VERSION "dbc-export 1 2026.26.6.5"

NS_ :

BS_:

BU_: ADSP APSB CMP DAS EPAS3P GTW OCS1P PTC RCM TCU TCU2 TRCM UDS UI UIS VCLEFT

BO_ 2047 GTW_carConfig: 8 GTW
 SG_ GTW_carConfigMultiplexer M : 0|8@1+ (1,0) [0|255] "" Vector__XXX
 SG_ GTW_deliveryStatus m1 : 8|1@1+ (1,0) [0|1] "" Vector__XXX
 SG_ GTW_cabinPTCHeaterType m1 : 10|1@1+ (1,0) [0|1] "" Vector__XXX
 SG_ GTW_rightHandDrive m1 : 11|1@1+ (1,0) [0|1] "" Vector__XXX
 SG_ GTW_rearLightType m1 : 12|2@1+ (1,0) [0|3] "" Vector__XXX
 SG_ GTW_headlamps m1 : 14|2@1+ (1,0) [0|3] "" Vector__XXX
 SG_ GTW_country m1 : 16|16@1+ (1,0) [0|65535] "" Vector__XXX
 SG_ GTW_tireType m1 : 32|6@1+ (1,0) [0|63] "" Vector__XXX
 SG_ GTW_dasHw m1 : 40|3@1+ (1,0) [3|5] "" Vector__XXX
 SG_ GTW_brakeHWType m1 : 43|5@1+ (1,0) [0|31] "" Vector__XXX
 SG_ GTW_restraintsHardwareType m1 : 48|8@1+ (1,0) [0|255] "" Vector__XXX
 SG_ GTW_drivetrainType m1 : 56|4@1+ (1,0) [0|4] "" Vector__XXX
 SG_ GTW_radarHeaterType m1 : 60|3@1+ (1,0) [0|5] "" Vector__XXX
 SG_ GTW_exteriorTrimType m2 : 8|1@1+ (1,0) [0|1] "" Vector__XXX
 SG_ GTW_frontSeatHeaters m2 : 9|1@1+ (1,0) [0|1] "" Vector__XXX
 SG_ GTW_rearSeatHeaters m2 : 10|1@1+ (1,0) [0|1] "" Vector__XXX
 SG_ GTW_eCallAntennaHW m2 : 12|1@1+ (1,0) [0|1] "" Vector__XXX
 SG_ GTW_homelinkType m2 : 13|1@1+ (1,0) [0|1] "" Vector__XXX
 SG_ GTW_vdcType m2 : 14|1@1+ (1,0) [0|1] "" Vector__XXX
 SG_ GTW_memoryMirrors m2 : 17|1@1+ (1,0) [0|1] "" Vector__XXX
 SG_ GTW_powerLiftgateType m2 : 18|2@1+ (1,0) [0|2] "" Vector__XXX
 SG_ GTW_lumbarECUType m2 : 20|4@1+ (1,0) [0|15] "" Vector__XXX
 SG_ GTW_rearSeatHeaterType m2 : 24|2@1+ (1,0) [0|3] "" Vector__XXX
 SG_ GTW_auxParkLamps m2 : 26|2@1+ (1,0) [0|3] "" Vector__XXX
 SG_ GTW_interiorCabinRadarType m2 : 28|1@1+ (1,0) [0|1] "" Vector__XXX
 SG_ GTW_hvacPanelVaneType m2 : 29|1@1+ (1,0) [0|1] "" Vector__XXX
 SG_ GTW_intakeAirFilterType m2 : 30|2@1+ (1,0) [0|2] "" Vector__XXX
 SG_ GTW_eBuckConfig m2 : 32|1@1+ (1,0) [0|1] "" Vector__XXX
 SG_ GTW_steeringHeaterEnabled m2 : 33|1@1+ (1,0) [0|1] "" Vector__XXX
 SG_ GTW_activeHighBeam m2 : 34|1@1+ (1,0) [0|1] "" Vector__XXX
 SG_ GTW_airbagCutoffSwitch m2 : 35|1@1+ (1,0) [0|1] "" Vector__XXX
 SG_ GTW_intrusionSensorType m2 : 36|1@1+ (1,0) [0|1] "" Vector__XXX
 SG_ GTW_spoilerType m2 : 37|1@1+ (1,0) [0|1] "" Vector__XXX
 SG_ GTW_backupCameraType m2 : 38|1@1+ (1,0) [0|1] "" Vector__XXX
 SG_ GTW_rearFogLamps m2 : 39|1@1+ (1,0) [0|1] "" Vector__XXX
 SG_ GTW_roofType m2 : 40|1@1+ (1,0) [0|1] "" Vector__XXX
 SG_ GTW_thirdRowSeatType m2 : 41|1@1+ (1,0) [0|1] "" Vector__XXX
 SG_ GTW_autopilot m2 : 42|3@1+ (1,0) [0|7] "" Vector__XXX
 SG_ GTW_superchargingAccess m2 : 45|2@1+ (1,0) [0|3] "" Vector__XXX
 SG_ GTW_exteriorColor m2 : 48|5@1+ (1,0) [0|31] "" Vector__XXX
 SG_ GTW_pedestrianWarningSound m2 : 53|2@1+ (1,0) [0|3] "" Vector__XXX
 SG_ GTW_steeringColumnUJointType m2 : 55|1@1+ (1,0) [0|1] "" Vector__XXX
 SG_ GTW_bPillarNFCParam m2 : 56|1@1+ (1,0) [0|1] "" Vector__XXX
 SG_ GTW_interiorLighting m2 : 57|3@1+ (1,0) [0|7] "" Vector__XXX
 SG_ GTW_headlightLevelerType m2 : 60|2@1+ (1,0) [0|3] "" Vector__XXX
 SG_ GTW_numberHVILNodes m2 : 62|2@1+ (1,0) [0|3] "" Vector__XXX
 SG_ GTW_mapRegion m3 : 8|4@1+ (1,0) [0|15] "" Vector__XXX
 SG_ GTW_performancePackage m3 : 12|3@1+ (1,0) [0|7] "" Vector__XXX
 SG_ GTW_chassisType m3 : 18|4@1+ (1,0) [0|15] "" Vector__XXX
 SG_ GTW_airSuspension m3 : 22|2@1+ (1,0) [0|3] "" Vector__XXX
 SG_ GTW_centerConsoleControllerType m3 : 24|2@1+ (1,0) [0|3] "" Vector__XXX
 SG_ GTW_autopilotCameraType m3 : 26|1@1+ (1,0) [0|1] "" Vector__XXX
 SG_ GTW_connectivityPackage m3 : 27|1@1+ (1,0) [0|1] "" Vector__XXX
 SG_ GTW_plcSupportType m3 : 28|2@1+ (1,0) [0|3] "" Vector__XXX
 SG_ GTW_badgingVersion m3 : 30|2@1+ (1,0) [0|3] "" Vector__XXX
 SG_ GTW_packEnergy m3 : 32|5@1+ (1,0) [0|31] "" Vector__XXX
 SG_ GTW_frontSeatReclinerHardware m3 : 37|2@1+ (1,0) [0|3] "" Vector__XXX
 SG_ GTW_brakeLineSwitchType m3 : 39|1@1+ (1,0) [0|1] "" Vector__XXX
 SG_ GTW_espValveType m3 : 40|2@1+ (1,0) [0|3] "" Vector__XXX
 SG_ GTW_softRange m3 : 42|3@1+ (1,0) [0|7] "" Vector__XXX
 SG_ GTW_refrigerantType m3 : 45|2@1+ (1,0) [0|3] "" Vector__XXX
 SG_ GTW_wheelType m3 : 48|7@1+ (1,0) [0|127] "" Vector__XXX
 SG_ GTW_ptcControlMode m3 : 55|2@1+ (1,0) [0|3] "" Vector__XXX
 SG_ GTW_brakeActuationType m3 : 57|3@1+ (1,0) [0|4] "" Vector__XXX
 SG_ GTW_secondRowSeatType m3 : 60|3@1+ (1,0) [0|7] "" Vector__XXX
 SG_ GTW_secondRowSeatMotorType m3 : 63|1@1+ (1,0) [0|1] "" Vector__XXX
 SG_ GTW_birthday m4 : 8|32@1+ (1,0) [0|4294967295] "" Vector__XXX
 SG_ GTW_eCallEnabled m4 : 40|2@1+ (1,0) [0|3] "" Vector__XXX
 SG_ GTW_parkAssistECUType m4 : 42|2@1+ (1,0) [0|3] "" Vector__XXX
 SG_ GTW_passengerAirbagType m4 : 44|2@1+ (1,0) [0|3] "" Vector__XXX
 SG_ GTW_forwardRadarHw m4 : 46|2@1+ (1,0) [0|2] "" Vector__XXX
 SG_ GTW_frontSeatType m4 : 48|4@1+ (1,0) [0|15] "" Vector__XXX
 SG_ GTW_secondRowDisplayType m4 : 52|1@1+ (1,0) [0|1] "" Vector__XXX
 SG_ GTW_wirelessPhoneChargerType m4 : 53|2@1+ (1,0) [0|3] "" Vector__XXX
 SG_ GTW_ethernetTunerType m4 : 55|2@1+ (1,0) [0|3] "" Vector__XXX
 SG_ GTW_interiorTrimType m4 : 60|4@1+ (1,0) [0|15] "" Vector__XXX
 SG_ GTW_gloveboxUSBType m5 : 8|2@1+ (1,0) [0|3] "" Vector__XXX
 SG_ GTW_coolantPumpType m5 : 10|3@1+ (1,0) [0|7] "" Vector__XXX
 SG_ GTW_epblHwType m5 : 13|4@1+ (1,0) [0|15] "" Vector__XXX
 SG_ GTW_epbrHwType m5 : 17|4@1+ (1,0) [0|15] "" Vector__XXX
 SG_ GTW_blowerMotorType m5 : 21|2@1+ (1,0) [0|3] "" Vector__XXX
 SG_ GTW_rearLeftBLEEndpointParameter m5 : 23|1@1+ (1,0) [0|1] "" Vector__XXX
 SG_ GTW_powerMirrorFoldType m5 : 24|1@1+ (1,0) [0|1] "" Vector__XXX
 SG_ GTW_frontUsbHubType m5 : 27|3@1+ (1,0) [0|5] "" Vector__XXX
 SG_ GTW_superManifoldType m5 : 30|2@1+ (1,0) [0|3] "" Vector__XXX
 SG_ GTW_rcmLocation m5 : 32|1@1+ (1,0) [0|1] "" Vector__XXX
 SG_ GTW_autopilotExteriorCameraType m5 : 33|1@1+ (1,0) [0|1] "" Vector__XXX
 SG_ GTW_interiorCamBeautyCoverType m5 : 35|2@1+ (1,0) [0|3] "" Vector__XXX
 SG_ GTW_sirenType m5 : 37|1@1+ (1,0) [0|1] "" Vector__XXX
 SG_ GTW_hornType m5 : 38|1@1+ (1,0) [0|1] "" Vector__XXX
 SG_ GTW_passengerTrackMotorType m5 : 40|1@1+ (1,0) [0|1] "" Vector__XXX
 SG_ GTW_steeringColumnMotorType m5 : 42|2@1+ (1,0) [0|3] "" Vector__XXX
 SG_ GTW_refrigACLineType m5 : 48|2@1+ (1,0) [0|3] "" Vector__XXX
 SG_ GTW_refrigFilterType m5 : 50|2@1+ (1,0) [0|3] "" Vector__XXX
 SG_ GTW_diBurnInType m5 : 52|1@1+ (1,0) [0|1] "" Vector__XXX
 SG_ GTW_specialBadgingType m5 : 53|2@1+ (1,0) [0|3] "" Vector__XXX
 SG_ GTW_chassisSubType m5 : 55|3@1+ (1,0) [0|7] "" Vector__XXX
 SG_ GTW_towPackage m5 : 58|2@1+ (1,0) [0|3] "" Vector__XXX
 SG_ GTW_refrigLccType m5 : 60|1@1+ (1,0) [0|1] "" Vector__XXX
 SG_ GTW_restraintControlsType m5 : 61|1@1+ (1,0) [0|1] "" Vector__XXX
 SG_ GTW_caliperColorType m5 : 62|2@1+ (1,0) [0|3] "" Vector__XXX
 SG_ GTW_wiperMotorType m6 : 9|1@1+ (1,0) [0|1] "" Vector__XXX
 SG_ GTW_frontOverheadConsoleType m6 : 10|2@1+ (1,0) [0|3] "" Vector__XXX
 SG_ GTW_shifterType m6 : 12|1@1+ (1,0) [0|1] "" Vector__XXX
 SG_ GTW_compressorType m6 : 13|4@1+ (1,0) [0|15] "" Vector__XXX
 SG_ GTW_twelveVBatteryType m6 : 17|3@1+ (1,0) [0|7] "" Vector__XXX
 SG_ GTW_efuseSWConfig m6 : 20|3@1+ (1,0) [0|7] "" Vector__XXX
 SG_ GTW_tollCollectionModuleType m6 : 23|1@1+ (1,0) [0|1] "" Vector__XXX
 SG_ GTW_bleEndpointUpdateMethod m6 : 24|1@1+ (1,0) [0|1] "" Vector__XXX
 SG_ GTW_steeringWheelControllerType m6 : 25|3@1+ (1,0) [0|7] "" Vector__XXX
 SG_ GTW_frontSeatVentilationEnabled m6 : 28|1@1+ (1,0) [0|1] "" Vector__XXX
 SG_ GTW_gloveboxActuatorType m6 : 29|2@1+ (1,0) [0|3] "" Vector__XXX
 SG_ GTW_epasType m6 : 32|4@1+ (1,0) [0|11] "" Vector__XXX
 SG_ GTW_homologationRegionOverride m6 : 36|2@1+ (1,0) [0|3] "" Vector__XXX
 SG_ GTW_windowCommandsPermissionType m6 : 38|2@1+ (1,0) [0|3] "" Vector__XXX
 SG_ GTW_headlightStepperStallDetectM m6 : 42|1@1+ (1,0) [0|1] "" Vector__XXX
 SG_ GTW_rgbInteriorLightingEnabled m6 : 43|2@1+ (1,0) [0|3] "" Vector__XXX
 SG_ GTW_windshieldWiperHeaterType m6 : 45|1@1+ (1,0) [0|1] "" Vector__XXX
 SG_ GTW_thirdRowSeatReclinerType m6 : 46|1@1+ (1,0) [0|1] "" Vector__XXX
 SG_ GTW_driveInterfaceType m6 : 47|1@1+ (1,0) [0|1] "" Vector__XXX
 SG_ GTW_efficiencyPackage m6 : 49|6@1+ (1,0) [0|63] "" Vector__XXX
 SG_ GTW_visorLightType m6 : 55|1@1+ (1,0) [0|1] "" Vector__XXX
 SG_ GTW_gnssAntennaType m6 : 58|2@1+ (1,0) [0|3] "" Vector__XXX
 SG_ GTW_airDistributionBoxType m6 : 60|1@1+ (1,0) [0|1] "" Vector__XXX
 SG_ GTW_frontSeatHeatersEnabled m6 : 62|1@1+ (1,0) [0|1] "" Vector__XXX
 SG_ GTW_windshieldWiperHeaterEnabled m6 : 63|1@1+ (1,0) [0|1] "" Vector__XXX
 SG_ GTW_alcoholInterlockType m7 : 8|1@1+ (1,0) [0|1] "" Vector__XXX
 SG_ GTW_fasciaType m7 : 9|4@1+ (1,0) [0|15] "" Vector__XXX
 SG_ GTW_powerSteeringColumn m7 : 13|1@1+ (1,0) [0|1] "" Vector__XXX
 SG_ GTW_frontSeatHeaterType m7 : 14|1@1+ (1,0) [0|1] "" Vector__XXX
 SG_ GTW_softPerformanceLimit m7 : 15|4@1+ (1,0) [0|15] "" Vector__XXX
 SG_ GTW_gsrFeatureType m7 : 21|2@1+ (1,0) [0|2] "" Vector__XXX
 SG_ GTW_immersiveAudio m7 : 23|2@1+ (1,0) [0|3] "" Vector__XXX
 SG_ GTW_frontSeatVentilationType m7 : 25|1@1+ (1,0) [0|1] "" Vector__XXX
 SG_ GTW_passengerOccupancySensorType m7 : 26|3@1+ (1,0) [0|7] "" Vector__XXX
 SG_ GTW_packPerformanceDeviation m7 : 30|3@1+ (1,0) [0|7] "" Vector__XXX
 SG_ GTW_pressurePadType m7 : 33|2@1+ (1,0) [0|3] "" Vector__XXX
 SG_ GTW_frontFogLamps m7 : 35|1@1+ (1,0) [0|1] "" Vector__XXX
 SG_ GTW_driverOccupancySensorType m7 : 36|1@1+ (1,0) [0|1] "" Vector__XXX
 SG_ GTW_audioType m7 : 37|3@1+ (1,0) [0|7] "" Vector__XXX
 SG_ GTW_thighExtenderType m7 : 41|1@1+ (1,0) [0|1] "" Vector__XXX
 SG_ GTW_occupancyClassificationFeatu m7 : 42|1@1+ (1,0) [0|1] "" Vector__XXX
 SG_ GTW_frontControllerArchitectureT m7 : 46|1@1+ (1,0) [0|1] "" Vector__XXX
 SG_ GTW_domeLightType m7 : 47|2@1+ (1,0) [0|3] "" Vector__XXX
 SG_ GTW_tpmsType m7 : 49|2@1+ (1,0) [0|3] "" Vector__XXX
 SG_ GTW_authenticationEndpointLayout m7 : 52|3@1+ (1,0) [0|6] "" Vector__XXX
 SG_ GTW_socSleepOverride m7 : 57|2@1+ (1,0) [0|3] "" Vector__XXX
 SG_ GTW_r79BehaviorOverride m7 : 59|1@1+ (1,0) [0|1] "" Vector__XXX
 SG_ GTW_steeringHeaterType m7 : 60|3@1+ (1,0) [0|7] "" Vector__XXX
 SG_ GTW_narrowWipingSupported m7 : 63|1@1+ (1,0) [0|1] "" Vector__XXX
 SG_ GTW_frontSeatHeaterGridType m8 : 8|1@1+ (1,0) [0|1] "" Vector__XXX
 SG_ GTW_frontSeatSideSwitchType m8 : 9|1@1+ (1,0) [0|1] "" Vector__XXX
 SG_ GTW_sohRegulatoryStatus m8 : 10|1@1+ (1,0) [0|1] "" Vector__XXX
 SG_ GTW_passengerTiltMotorType m8 : 11|2@1+ (1,0) [0|3] "" Vector__XXX
 SG_ GTW_frunkInteriorReleaseType m8 : 15|1@1+ (1,0) [0|1] "" Vector__XXX
 SG_ GTW_m3yBusArchitecture m8 : 17|2@1+ (1,0) [0|3] "" Vector__XXX
 SG_ GTW_passengerLiftMotorType m8 : 19|2@1+ (1,0) [0|3] "" Vector__XXX
 SG_ GTW_interiorUpperTrimType m8 : 21|1@1+ (1,0) [0|1] "" Vector__XXX
 SG_ GTW_blindSpotIndicatorLightType m8 : 22|2@1+ (1,0) [0|3] "" Vector__XXX
 SG_ GTW_wiperMotorAsicType m8 : 24|2@1+ (1,0) [0|3] "" Vector__XXX
 SG_ GTW_hvacCaseDoorType m8 : 28|1@1+ (1,0) [0|1] "" Vector__XXX
 SG_ GTW_occupancyDetectionSourceRequ m8 : 29|1@1+ (1,0) [0|1] "" Vector__XXX
 SG_ GTW_rduCableType m8 : 31|1@1+ (1,0) [0|1] "" Vector__XXX
 SG_ GTW_parkTelltaleBehaviorType m8 : 32|1@1+ (1,0) [0|1] "" Vector__XXX
 SG_ GTW_numberKeyCardsPairedInFactor m8 : 35|2@1+ (1,0) [0|2] "" Vector__XXX
 SG_ GTW_secondRowSeatVentilationType m8 : 37|1@1+ (1,0) [0|1] "" Vector__XXX
 SG_ GTW_thirdRowSeatHeaterType m8 : 38|1@1+ (1,0) [0|1] "" Vector__XXX
 SG_ GTW_interiorCameraType m8 : 39|2@1+ (1,0) [0|2] "" Vector__XXX
 SG_ GTW_frontFasciaCameraType m8 : 41|2@1+ (1,0) [0|3] "" Vector__XXX
 SG_ GTW_interiorCamFanType m8 : 45|3@1+ (1,0) [0|7] "" Vector__XXX
 SG_ GTW_puddleLampType m8 : 50|2@1+ (1,0) [0|2] "" Vector__XXX
 SG_ GTW_solarLensType m8 : 52|2@1+ (1,0) [0|2] "" Vector__XXX
 SG_ GTW_liftgateGeometryType m8 : 56|2@1+ (1,0) [0|3] "" Vector__XXX
 SG_ GTW_repeaterAeroRibType m8 : 60|3@1+ (1,0) [0|7] "" Vector__XXX
 SG_ GTW_highTipForceWiperArmsType m8 : 63|1@1+ (1,0) [0|1] "" Vector__XXX
 SG_ GTW_rcmUndersideAbuseZThreshold m9 : 8|3@1+ (1,0) [0|7] "" Vector__XXX
 SG_ GTW_rcmUndersideAbuseYThreshold m9 : 11|3@1+ (1,0) [0|7] "" Vector__XXX
 SG_ GTW_rcmUndersideAbuseWindow m9 : 14|2@1+ (1,0) [0|3] "" Vector__XXX
 SG_ GTW_uhfChargePortEnabled m9 : 16|1@1+ (1,0) [0|1] "" Vector__XXX
 SG_ GTW_automaticFeatureResetPackage m9 : 18|1@1+ (1,0) [0|1] "" Vector__XXX
 SG_ GTW_autopilotFeaturePackage m9 : 20|2@1+ (1,0) [0|2] "" Vector__XXX
 SG_ GTW_doorLatchType m9 : 23|1@1+ (1,0) [0|1] "" Vector__XXX
 SG_ GTW_headlinerMaterialType m9 : 25|2@1+ (1,0) [0|3] "" Vector__XXX
 SG_ GTW_glareShieldHeaterType m9 : 27|1@1+ (1,0) [0|1] "" Vector__XXX
 SG_ GTW_rearLightHardwareVariant m9 : 29|2@1+ (1,0) [0|3] "" Vector__XXX
 SG_ GTW_fasciaHarnessCleanPointType m9 : 31|2@1+ (1,0) [0|3] "" Vector__XXX
 SG_ GTW_epasSubType m9 : 33|1@1+ (1,0) [0|1] "" Vector__XXX
 SG_ GTW_wiperSupplyChainOrigin m9 : 35|2@1+ (1,0) [1|3] "" Vector__XXX
 SG_ GTW_windowPinchParameterType m9 : 37|2@1+ (1,0) [0|3] "" Vector__XXX
 SG_ GTW_badgingMaterialType m9 : 39|1@1+ (1,0) [0|1] "" Vector__XXX
 SG_ GTW_mRecordVersion m9 : 40|1@1+ (1,0) [0|1] "" Vector__XXX
 SG_ GTW_tcuType m9 : 47|2@1+ (1,0) [0|2] "" Vector__XXX
 SG_ GTW_carbComplianceBehaviorType m9 : 49|1@1+ (1,0) [0|1] "" Vector__XXX
 SG_ GTW_indirectTPMSCalibrationType m9 : 55|3@1+ (1,0) [0|7] "" Vector__XXX
 SG_ GTW_v2xEnabled m9 : 58|1@1+ (1,0) [0|1] "" Vector__XXX
 SG_ GTW_liftgateStrutType m9 : 60|1@1+ (1,0) [0|1] "" Vector__XXX
 SG_ GTW_exteriorMicrophoneType m9 : 63|1@1+ (1,0) [0|1] "" Vector__XXX
 SG_ GTW_contactorPowerSource m10 : 20|1@1+ (1,0) [0|1] "" Vector__XXX
 SG_ GTW_roofGlassType m10 : 21|3@1+ (1,0) [0|7] "" Vector__XXX
 SG_ GTW_pedalMapNameOverride m10 : 25|1@1+ (1,0) [0|1] "" Vector__XXX

BO_ 792 GTW_carState: 8 GTW
 SG_ GTW_factoryGated : 48|1@1+ (1,0) [0|1] "" Vector__XXX

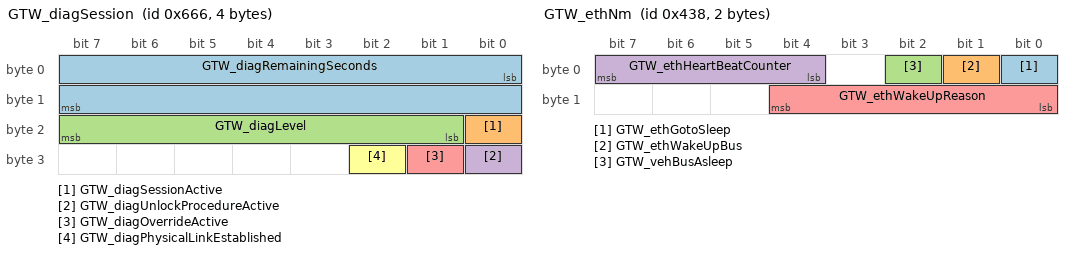
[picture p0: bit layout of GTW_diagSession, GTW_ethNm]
BO_ 1638 GTW_diagSession: 4 GTW
 SG_ GTW_diagRemainingSeconds : 0|16@1+ (1,0) [0|65535] "seconds" Vector__XXX
 SG_ GTW_diagSessionActive : 16|1@1+ (1,0) [0|1] "" Vector__XXX
 SG_ GTW_diagLevel : 17|7@1+ (1,0) [0|127] "" Vector__XXX
 SG_ GTW_diagUnlockProcedureActive : 24|1@1+ (1,0) [0|1] "" Vector__XXX
 SG_ GTW_diagOverrideActive : 25|1@1+ (1,0) [0|1] "" Vector__XXX
 SG_ GTW_diagPhysicalLinkEstablished : 26|1@1+ (1,0) [0|1] "" Vector__XXX

BO_ 1080 GTW_ethNm: 2 GTW
 SG_ GTW_ethGotoSleep : 0|1@1+ (1,0) [0|1] "" Vector__XXX
 SG_ GTW_ethWakeUpBus : 1|1@1+ (1,0) [0|1] "" Vector__XXX
 SG_ GTW_vehBusAsleep : 2|1@1+ (1,0) [0|1] "" Vector__XXX
 SG_ GTW_ethHeartBeatCounter : 4|4@1+ (1,0) [0|15] "" Vector__XXX
 SG_ GTW_ethWakeUpReason : 8|5@1+ (1,0) [0|31] "" Vector__XXX

BO_ 1376 GTW_factoryEcuPresent: 4 GTW
 SG_ GTW_OCS1Ppresent : 0|1@1+ (1,0) [0|1] "" Vector__XXX
 SG_ GTW_PCSpresent : 1|1@1+ (1,0) [0|1] "" Vector__XXX
 SG_ GTW_HVPpresent : 2|1@1+ (1,0) [0|1] "" Vector__XXX
 SG_ GTW_BMSpresent : 3|1@1+ (1,0) [0|1] "" Vector__XXX
 SG_ GTW_CPpresent : 4|1@1+ (1,0) [0|1] "" Vector__XXX
 SG_ GTW_RCMpresent : 5|1@1+ (1,0) [0|1] "" Vector__XXX
 SG_ GTW_SCCMpresent : 6|1@1+ (1,0) [0|1] "" Vector__XXX
 SG_ GTW_VCSECpresent : 7|1@1+ (1,0) [0|1] "" Vector__XXX
 SG_ GTW_EPAS3Ppresent : 8|1@1+ (1,0) [0|1] "" Vector__XXX
 SG_ GTW_EPBLpresent : 9|1@1+ (1,0) [0|1] "" Vector__XXX
 SG_ GTW_EPBRpresent : 10|1@1+ (1,0) [0|1] "" Vector__XXX
 SG_ GTW_ESPpresent : 11|1@1+ (1,0) [0|1] "" Vector__XXX
 SG_ GTW_IBSTpresent : 12|1@1+ (1,0) [0|1] "" Vector__XXX
 SG_ GTW_PARKpresent : 13|1@1+ (1,0) [0|1] "" Vector__XXX
 SG_ GTW_RADCpresent : 14|1@1+ (1,0) [0|1] "" Vector__XXX
 SG_ GTW_TPMSpresent : 15|1@1+ (1,0) [0|1] "" Vector__XXX
 SG_ GTW_VCFRONTpresent : 16|1@1+ (1,0) [0|1] "" Vector__XXX
 SG_ GTW_VCLEFTpresent : 17|1@1+ (1,0) [0|1] "" Vector__XXX
 SG_ GTW_VCRIGHTpresent : 18|1@1+ (1,0) [0|1] "" Vector__XXX
 SG_ GTW_EPAS3Spresent : 19|1@1+ (1,0) [0|1] "" Vector__XXX
 SG_ GTW_CMPpresent : 20|1@1+ (1,0) [0|1] "" Vector__XXX
 SG_ GTW_DASpresent : 21|1@1+ (1,0) [0|1] "" Vector__XXX
 SG_ GTW_PTCpresent : 22|1@1+ (1,0) [0|1] "" Vector__XXX
 SG_ GTW_SWCpresent : 23|1@1+ (1,0) [0|1] "" Vector__XXX
 SG_ GTW_PMRpresent : 25|1@1+ (1,0) [0|1] "" Vector__XXX
 SG_ GTW_PMFpresent : 26|1@1+ (1,0) [0|1] "" Vector__XXX
 SG_ GTW_DIRpresent : 27|1@1+ (1,0) [0|1] "" Vector__XXX
 SG_ GTW_DIFpresent : 28|1@1+ (1,0) [0|1] "" Vector__XXX

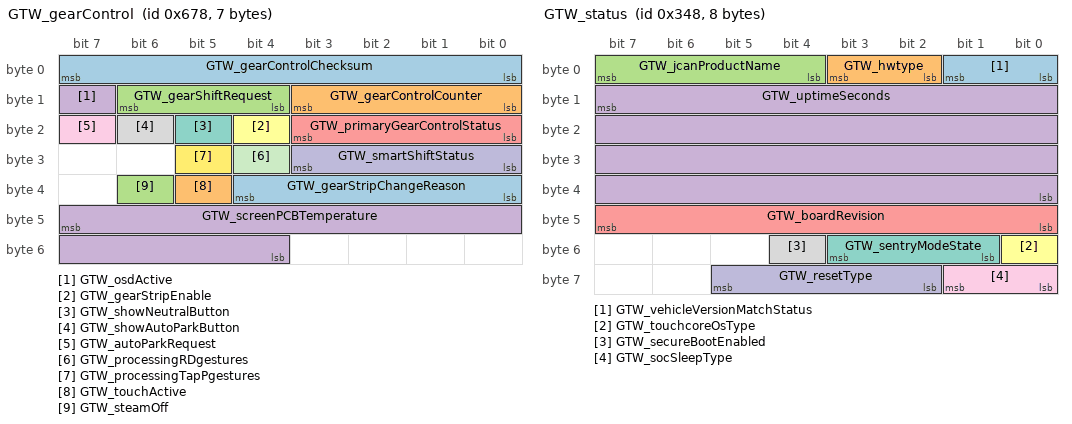
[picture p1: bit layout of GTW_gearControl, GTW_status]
BO_ 1656 GTW_gearControl: 7 GTW
 SG_ GTW_gearControlChecksum : 0|8@1+ (1,0) [0|255] "" Vector__XXX
 SG_ GTW_gearControlCounter : 8|4@1+ (1,0) [0|15] "" Vector__XXX
 SG_ GTW_gearShiftRequest : 12|3@1+ (1,0) [1|7] "" Vector__XXX
 SG_ GTW_osdActive : 15|1@1+ (1,0) [0|1] "" Vector__XXX
 SG_ GTW_primaryGearControlStatus : 16|4@1+ (1,0) [0|15] "" Vector__XXX
 SG_ GTW_gearStripEnable : 20|1@1+ (1,0) [0|1] "" Vector__XXX
 SG_ GTW_showNeutralButton : 21|1@1+ (1,0) [0|1] "" Vector__XXX
 SG_ GTW_showAutoParkButton : 22|1@1+ (1,0) [0|1] "" Vector__XXX
 SG_ GTW_autoParkRequest : 23|1@1+ (1,0) [0|1] "" Vector__XXX
 SG_ GTW_smartShiftStatus : 24|4@1+ (1,0) [1|15] "" Vector__XXX
 SG_ GTW_processingRDgestures : 28|1@1+ (1,0) [0|1] "" Vector__XXX
 SG_ GTW_processingTapPgestures : 29|1@1+ (1,0) [0|1] "" Vector__XXX
 SG_ GTW_gearStripChangeReason : 32|5@1+ (1,0) [1|31] "" Vector__XXX
 SG_ GTW_touchActive : 37|1@1+ (1,0) [0|1] "" Vector__XXX
 SG_ GTW_steamOff : 38|1@1+ (1,0) [0|1] "" Vector__XXX
 SG_ GTW_screenPCBTemperature : 47|12@0- (0.0625,0) [-128|127.875] "degC" Vector__XXX

BO_ 2033 GTW_hrl: 7 GTW
 SG_ GTW_hrlIndex M : 0|2@1+ (1,0) [0|3] "" Vector__XXX
 SG_ GTW_hrlPagesCount m1 : 15|32@0+ (1,0) [0|4294967295] "" Vector__XXX
 SG_ GTW_hrlSdCardSizeGB m1 : 40|8@1+ (1,0) [1|255] "" Vector__XXX
 SG_ GTW_hrlState m2 : 2|1@1+ (1,0) [0|1] "" Vector__XXX
 SG_ GTW_hrlTriggerDuration m2 : 15|16@0+ (1,0) [0|65535] "seconds" Vector__XXX
 SG_ GTW_hrlTriggerType m2 : 24|4@1+ (1,0) [0|15] "" Vector__XXX
 SG_ GTW_hrlTriggerId m2 : 39|16@0+ (1,0) [0|65535] "" Vector__XXX
 SG_ GTW_hrlTriggerBus m2 : 53|3@1+ (1,0) [0|7] "" Vector__XXX

BO_ 2026 GTW_hrlExternalEvent: 8 GTW
 SG_ GTW_hrlEventStartEpoch : 7|32@0+ (1,0) [0|4294967295] "seconds" Vector__XXX
 SG_ GTW_hrlEventEndEpoch : 39|32@0+ (1,0) [0|4294967295] "seconds" Vector__XXX

BO_ 60 GTW_info: 8 GTW
 SG_ GTW_infoIndex M : 0|8@1+ (1,0) [0|255] "" Vector__XXX
 SG_ GTW_buildType m10 : 8|3@1+ (1,0) [0|7] "" Vector__XXX
 SG_ GTW_hardwareId m10 : 32|16@1+ (1,0) [0|65535] "" Vector__XXX
 SG_ GTW_platformType m13 : 8|8@1+ (1,0) [0|255] "" Vector__XXX
 SG_ GTW_appCrc m13 : 32|32@1+ (1,0) [0|4294967295] "" Vector__XXX
 SG_ GTW_applicationGitHash m17 : 8|56@1+ (1,0) [0|7.20575940379e+16] "" Vector__XXX
 SG_ GTW_bootGitHash m18 : 8|56@1+ (1,0) [0|7.20575940379e+16] "" Vector__XXX

BO_ 1370 GTW_mismatchFault: 8 GTW
 SG_ GTW_mismatchFaultIndex M : 0|3@1+ (1,0) [0|7] "" Vector__XXX
 SG_ GTW_mismatchFaultChecksum : 3|8@1+ (1,0) [0|255] "" Vector__XXX
 SG_ GTW_mismatchFaultCounter : 11|4@1+ (1,0) [0|15] "" Vector__XXX
 SG_ GTW_GTWmismatchFault m1 : 15|1@1+ (1,0) [0|1] "" Vector__XXX
 SG_ GTW_BMSmismatchFault m1 : 16|1@1+ (1,0) [0|1] "" Vector__XXX
 SG_ GTW_APSmismatchFault m1 : 17|1@1+ (1,0) [0|1] "" Vector__XXX
 SG_ GTW_BLEEPCENTERmismatchFault m1 : 18|1@1+ (1,0) [0|1] "" Vector__XXX
 SG_ GTW_BLEEPLEFTmismatchFault m1 : 19|1@1+ (1,0) [0|1] "" Vector__XXX
 SG_ GTW_BLEEPREARmismatchFault m1 : 20|1@1+ (1,0) [0|1] "" Vector__XXX
 SG_ GTW_BLEEPRIGHTmismatchFault m1 : 21|1@1+ (1,0) [0|1] "" Vector__XXX
 SG_ GTW_CBCmismatchFault m1 : 22|1@1+ (1,0) [0|1] "" Vector__XXX
 SG_ GTW_CMPmismatchFault m1 : 23|1@1+ (1,0) [0|1] "" Vector__XXX
 SG_ GTW_CPmismatchFault m1 : 24|1@1+ (1,0) [0|1] "" Vector__XXX
 SG_ GTW_DIFmismatchFault m1 : 25|1@1+ (1,0) [0|1] "" Vector__XXX
 SG_ GTW_DIRmismatchFault m1 : 26|1@1+ (1,0) [0|1] "" Vector__XXX
 SG_ GTW_EPAS3PmismatchFault m1 : 27|1@1+ (1,0) [0|1] "" Vector__XXX
 SG_ GTW_EPAS3SmismatchFault m1 : 28|1@1+ (1,0) [0|1] "" Vector__XXX
 SG_ GTW_EPBLmismatchFault m1 : 29|1@1+ (1,0) [0|1] "" Vector__XXX
 SG_ GTW_EPBRmismatchFault m1 : 30|1@1+ (1,0) [0|1] "" Vector__XXX
 SG_ GTW_ESPCALmismatchFault m1 : 31|1@1+ (1,0) [0|1] "" Vector__XXX
 SG_ GTW_ESPmismatchFault m1 : 32|1@1+ (1,0) [0|1] "" Vector__XXX
 SG_ GTW_HCM3LmismatchFault m1 : 33|1@1+ (1,0) [0|1] "" Vector__XXX
 SG_ GTW_HCM3RmismatchFault m1 : 34|1@1+ (1,0) [0|1] "" Vector__XXX
 SG_ GTW_HCMLmismatchFault m1 : 35|1@1+ (1,0) [0|1] "" Vector__XXX
 SG_ GTW_HCMRmismatchFault m1 : 36|1@1+ (1,0) [0|1] "" Vector__XXX
 SG_ GTW_HVPmismatchFault m1 : 37|1@1+ (1,0) [0|1] "" Vector__XXX
 SG_ GTW_IBSTCALmismatchFault m1 : 38|1@1+ (1,0) [0|1] "" Vector__XXX
 SG_ GTW_IBSTmismatchFault m1 : 39|1@1+ (1,0) [0|1] "" Vector__XXX
 SG_ GTW_LVBMSmismatchFault m1 : 40|1@1+ (1,0) [0|1] "" Vector__XXX
 SG_ GTW_OCS1PmismatchFault m1 : 41|1@1+ (1,0) [0|1] "" Vector__XXX
 SG_ GTW_OPCFmismatchFault m1 : 42|1@1+ (1,0) [0|1] "" Vector__XXX
 SG_ GTW_OPCRmismatchFault m1 : 43|1@1+ (1,0) [0|1] "" Vector__XXX
 SG_ GTW_PARKmismatchFault m1 : 44|1@1+ (1,0) [0|1] "" Vector__XXX
 SG_ GTW_PCSCPU2mismatchFault m1 : 45|1@1+ (1,0) [0|1] "" Vector__XXX
 SG_ GTW_PCSmismatchFault m1 : 46|1@1+ (1,0) [0|1] "" Vector__XXX
 SG_ GTW_PMFmismatchFault m1 : 47|1@1+ (1,0) [0|1] "" Vector__XXX
 SG_ GTW_PMRmismatchFault m1 : 48|1@1+ (1,0) [0|1] "" Vector__XXX
 SG_ GTW_PTCmismatchFault m1 : 49|1@1+ (1,0) [0|1] "" Vector__XXX
 SG_ GTW_RCMCALmismatchFault m1 : 50|1@1+ (1,0) [0|1] "" Vector__XXX
 SG_ GTW_RCMmismatchFault m1 : 51|1@1+ (1,0) [0|1] "" Vector__XXX
 SG_ GTW_SCCMmismatchFault m1 : 52|1@1+ (1,0) [0|1] "" Vector__XXX
 SG_ GTW_SDCRmismatchFault m1 : 53|1@1+ (1,0) [0|1] "" Vector__XXX
 SG_ GTW_SWCmismatchFault m1 : 54|1@1+ (1,0) [0|1] "" Vector__XXX
 SG_ GTW_THSmismatchFault m1 : 55|1@1+ (1,0) [0|1] "" Vector__XXX
 SG_ GTW_VCFRONTmismatchFault m1 : 56|1@1+ (1,0) [0|1] "" Vector__XXX
 SG_ GTW_VCLEFTmismatchFault m1 : 57|1@1+ (1,0) [0|1] "" Vector__XXX
 SG_ GTW_VCRIGHTmismatchFault m1 : 58|1@1+ (1,0) [0|1] "" Vector__XXX
 SG_ GTW_VCSECmismatchFault m1 : 59|1@1+ (1,0) [0|1] "" Vector__XXX
 SG_ GTW_PMmismatchFault m1 : 60|1@1+ (1,0) [0|1] "" Vector__XXX

BO_ 840 GTW_status: 8 GTW
 SG_ GTW_vehicleVersionMatchStatus : 0|2@1+ (1,0) [0|3] "" Vector__XXX
 SG_ GTW_hwtype : 2|2@1+ (1,0) [1|3] "" Vector__XXX
 SG_ GTW_jcanProductName : 4|4@1+ (1,0) [1|15] "" Vector__XXX
 SG_ GTW_uptimeSeconds : 15|32@0+ (1,0) [0|4294967295] "s" Vector__XXX
 SG_ GTW_boardRevision : 40|8@1+ (1,0) [0|255] "" Vector__XXX
 SG_ GTW_touchcoreOsType : 48|1@1+ (1,0) [0|1] "" Vector__XXX
 SG_ GTW_sentryModeState : 49|3@1+ (1,0) [0|7] "" Vector__XXX
 SG_ GTW_secureBootEnabled : 52|1@1+ (1,0) [0|1] "" Vector__XXX
 SG_ GTW_socSleepType : 56|2@1+ (1,0) [1|3] "" Vector__XXX
 SG_ GTW_resetType : 58|4@1+ (1,0) [1|15] "" Vector__XXX

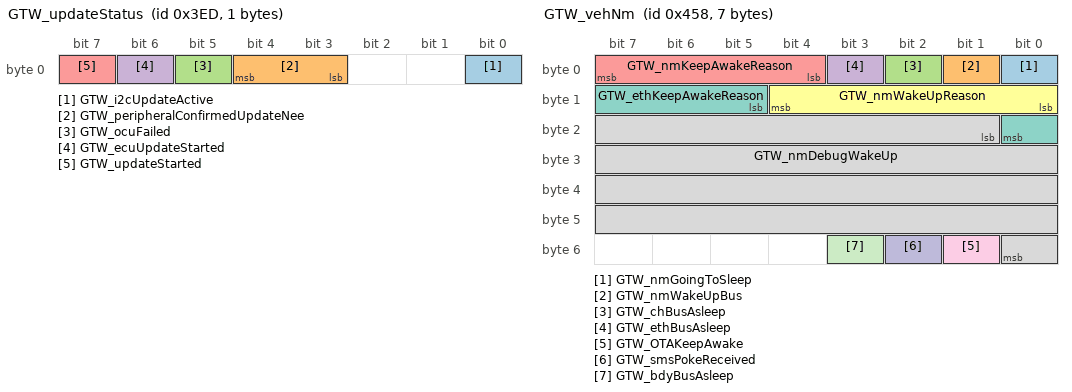
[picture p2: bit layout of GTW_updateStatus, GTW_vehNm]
BO_ 1005 GTW_updateStatus: 1 GTW
 SG_ GTW_i2cUpdateActive : 0|1@1+ (1,0) [0|1] "" Vector__XXX
 SG_ GTW_peripheralConfirmedUpdateNee : 3|2@1+ (1,0) [0|3] "" Vector__XXX
 SG_ GTW_ocuFailed : 5|1@1+ (1,0) [0|1] "" Vector__XXX
 SG_ GTW_ecuUpdateStarted : 6|1@1+ (1,0) [0|1] "" Vector__XXX
 SG_ GTW_updateStarted : 7|1@1+ (1,0) [0|1] "" Vector__XXX

BO_ 1112 GTW_vehNm: 7 GTW
 SG_ GTW_nmGoingToSleep : 0|1@1+ (1,0) [0|1] "" Vector__XXX
 SG_ GTW_nmWakeUpBus : 1|1@1+ (1,0) [0|1] "" Vector__XXX
 SG_ GTW_chBusAsleep : 2|1@1+ (1,0) [0|1] "" Vector__XXX
 SG_ GTW_ethBusAsleep : 3|1@1+ (1,0) [0|1] "" Vector__XXX
 SG_ GTW_nmKeepAwakeReason : 4|4@1+ (1,0) [1|15] "" Vector__XXX
 SG_ GTW_nmWakeUpReason : 8|5@1+ (1,0) [0|31] "" Vector__XXX
 SG_ GTW_ethKeepAwakeReason : 13|4@1+ (1,0) [1|15] "" Vector__XXX
 SG_ GTW_nmDebugWakeUp : 17|32@1+ (1,0) [0|4294967295] "" Vector__XXX
 SG_ GTW_OTAKeepAwake : 49|1@1+ (1,0) [0|1] "" Vector__XXX
 SG_ GTW_smsPokeReceived : 50|1@1+ (1,0) [0|1] "" Vector__XXX
 SG_ GTW_bdyBusAsleep : 51|1@1+ (1,0) [0|1] "" Vector__XXX

BO_ 1429 OCS1P_alertLog: 8 OCS1P
 SG_ OCS1P_alertID M : 0|8@1+ (1,0) [0|255] "" Vector__XXX
 SG_ OCS1P_alertState : 15|1@1+ (1,0) [0|1] "" Vector__XXX
 SG_ OCS1P_a121_sandwichFreq m121 : 16|32@1+ (1,0) [0|4294967295] "" Vector__XXX
 SG_ OCS1P_a122_sandwichFreq m122 : 16|32@1+ (1,0) [0|4294967295] "" Vector__XXX
 SG_ OCS1P_a123_sandwichFreq m123 : 16|32@1+ (1,0) [0|4294967295] "" Vector__XXX
 SG_ OCS1P_a124_cushionSelfFreq m124 : 16|32@1+ (1,0) [0|4294967295] "" Vector__XXX
 SG_ OCS1P_a125_cushionSelfFreq m125 : 16|32@1+ (1,0) [0|4294967295] "" Vector__XXX
 SG_ OCS1P_a126_cushionSelfFreq m126 : 16|32@1+ (1,0) [0|4294967295] "" Vector__XXX
 SG_ OCS1P_a127_seatbackSelfFreq m127 : 16|32@1+ (1,0) [0|4294967295] "" Vector__XXX
 SG_ OCS1P_a128_seatbackSelfFreq m128 : 16|32@1+ (1,0) [0|4294967295] "" Vector__XXX
 SG_ OCS1P_a129_seatbackSelfFreq m129 : 16|32@1+ (1,0) [0|4294967295] "" Vector__XXX
 SG_ OCS1P_a130_sandwichNoCalib m130 : 16|1@1+ (1,0) [0|1] "" Vector__XXX
 SG_ OCS1P_a131_cushionSelfNoCalib m131 : 16|1@1+ (1,0) [0|1] "" Vector__XXX
 SG_ OCS1P_a132_seatbackSelfNoCalib m132 : 16|1@1+ (1,0) [0|1] "" Vector__XXX
 SG_ OCS1P_a133_sandwichBadCalib m133 : 16|1@1+ (1,0) [0|1] "" Vector__XXX
 SG_ OCS1P_a134_uninitializedCalib m134 : 16|1@1+ (1,0) [0|1] "" Vector__XXX
 SG_ OCS1P_a135_tempNoCalib m135 : 16|1@1+ (1,0) [0|1] "" Vector__XXX
 SG_ OCS1P_a140_tempInvalidCalib m140 : 16|1@1+ (1,0) [0|1] "" Vector__XXX
 SG_ OCS1P_a141_humidityInvalidCalib m141 : 16|1@1+ (1,0) [0|1] "" Vector__XXX
 SG_ OCS1P_a142_tempHumidityInvalid m142 : 16|1@1+ (1,0) [0|1] "" Vector__XXX
 SG_ OCS1P_a143_mismatchPassAirbag m143 : 16|1@1+ (1,0) [0|1] "" Vector__XXX
 SG_ OCS1P_a144_mismatchCarRegion m144 : 16|1@1+ (1,0) [0|1] "" Vector__XXX

BO_ 767 OCS1P_alertMatrix: 8 OCS1P
 SG_ OCS1P_matrixIndex M : 0|4@1+ (1,0) [0|15] "" Vector__XXX
 SG_ OCS1P_w015_NVMMAlert m0 : 18|1@1+ (1,0) [0|1] "" Vector__XXX
 SG_ OCS1P_w121_sandwichOpen m2 : 4|1@1+ (1,0) [0|1] "" Vector__XXX
 SG_ OCS1P_w122_sandwichLow m2 : 5|1@1+ (1,0) [0|1] "" Vector__XXX
 SG_ OCS1P_w123_sandwichShort m2 : 6|1@1+ (1,0) [0|1] "" Vector__XXX
 SG_ OCS1P_w124_cushionSelfOpen m2 : 7|1@1+ (1,0) [0|1] "" Vector__XXX
 SG_ OCS1P_w125_cushionSelfLow m2 : 8|1@1+ (1,0) [0|1] "" Vector__XXX
 SG_ OCS1P_w126_cushionSelfShort m2 : 9|1@1+ (1,0) [0|1] "" Vector__XXX
 SG_ OCS1P_w127_seatbackSelfOpen m2 : 10|1@1+ (1,0) [0|1] "" Vector__XXX
 SG_ OCS1P_w128_seatbackSelfLow m2 : 11|1@1+ (1,0) [0|1] "" Vector__XXX
 SG_ OCS1P_w129_seatbackSelfShort m2 : 12|1@1+ (1,0) [0|1] "" Vector__XXX
 SG_ OCS1P_w130_sandwichNoCalib m2 : 13|1@1+ (1,0) [0|1] "" Vector__XXX
 SG_ OCS1P_w131_cushionSelfNoCalib m2 : 14|1@1+ (1,0) [0|1] "" Vector__XXX
 SG_ OCS1P_w132_seatbackSelfNoCalib m2 : 15|1@1+ (1,0) [0|1] "" Vector__XXX
 SG_ OCS1P_w133_sandwichBadCalib m2 : 16|1@1+ (1,0) [0|1] "" Vector__XXX
 SG_ OCS1P_w134_uninitializedCalib m2 : 17|1@1+ (1,0) [0|1] "" Vector__XXX
 SG_ OCS1P_w135_tempNoCalib m2 : 18|1@1+ (1,0) [0|1] "" Vector__XXX
 SG_ OCS1P_w136_cushionSelfDutyLow m2 : 19|1@1+ (1,0) [0|1] "" Vector__XXX
 SG_ OCS1P_w137_cushionSelfDutyHigh m2 : 20|1@1+ (1,0) [0|1] "" Vector__XXX
 SG_ OCS1P_w138_seatbackSelfDutyLow m2 : 21|1@1+ (1,0) [0|1] "" Vector__XXX
 SG_ OCS1P_w139_seatbackSelfDutyHigh m2 : 22|1@1+ (1,0) [0|1] "" Vector__XXX
 SG_ OCS1P_w140_tempInvalidCalib m2 : 23|1@1+ (1,0) [0|1] "" Vector__XXX
 SG_ OCS1P_w141_humidityInvalidCalib m2 : 24|1@1+ (1,0) [0|1] "" Vector__XXX
 SG_ OCS1P_w142_tempHumidityInvalid m2 : 25|1@1+ (1,0) [0|1] "" Vector__XXX
 SG_ OCS1P_w143_mismatchPassAirbag m2 : 26|1@1+ (1,0) [0|1] "" Vector__XXX
 SG_ OCS1P_w144_mismatchCarRegion m2 : 27|1@1+ (1,0) [0|1] "" Vector__XXX
 SG_ OCS1P_w145_rebaselineTriggered m2 : 28|1@1+ (1,0) [0|1] "" Vector__XXX
 SG_ OCS1P_w148_classificationMismatc m2 : 31|1@1+ (1,0) [0|1] "" Vector__XXX
 SG_ OCS1P_w150_rbEntryTriggered m2 : 33|1@1+ (1,0) [0|1] "" Vector__XXX
 SG_ OCS1P_w151_rbEntryExited m2 : 34|1@1+ (1,0) [0|1] "" Vector__XXX
 SG_ OCS1P_w152_rbExit1Triggered m2 : 35|1@1+ (1,0) [0|1] "" Vector__XXX
 SG_ OCS1P_w153_rbExit1Exited m2 : 36|1@1+ (1,0) [0|1] "" Vector__XXX
 SG_ OCS1P_w154_rbExit2Exited1 m2 : 37|1@1+ (1,0) [0|1] "" Vector__XXX
 SG_ OCS1P_w155_rbExit2Exited2 m2 : 38|1@1+ (1,0) [0|1] "" Vector__XXX
 SG_ OCS1P_w156_seatbeltReminderUnava m2 : 39|1@1+ (1,0) [0|1] "" Vector__XXX

BO_ 766 OCS1P_info: 8 OCS1P
 SG_ OCS1P_infoIndex M : 0|8@1+ (1,0) [0|255] "" Vector__XXX
 SG_ OCS1P_infoBuildType m10 : 8|8@1+ (1,0) [0|255] "" Vector__XXX
 SG_ OCS1P_infoBuildConfigID m10 : 16|16@1+ (1,0) [0|65535] "" Vector__XXX
 SG_ OCS1P_infoHardwareID m10 : 32|16@1+ (1,0) [0|65535] "" Vector__XXX
 SG_ OCS1P_infoComponentID m10 : 48|16@1+ (1,0) [0|65535] "" Vector__XXX
 SG_ OCS1P_infoPcbaID m11 : 16|8@1+ (1,0) [0|255] "" Vector__XXX
 SG_ OCS1P_infoAssemblyID m11 : 24|8@1+ (1,0) [0|255] "" Vector__XXX
 SG_ OCS1P_infoUsageID m11 : 32|16@1+ (1,0) [0|65535] "" Vector__XXX
 SG_ OCS1P_infoSubUsageID m11 : 48|16@1+ (1,0) [0|65535] "" Vector__XXX
 SG_ OCS1P_infoApplicationCRC m13 : 32|32@1+ (1,0) [0|4294967295] "" Vector__XXX
 SG_ OCS1P_infoBootSvnRev m14 : 8|24@1+ (1,0) [0|16777215] "" Vector__XXX
 SG_ OCS1P_infoAppGitHashBytes m17 : 8|56@1+ (1,0) [0|7.20575940379e+16] "" Vector__XXX
 SG_ OCS1P_infoBootGitHashBytes m18 : 8|56@1+ (1,0) [0|7.20575940379e+16] "" Vector__XXX
 SG_ OCS1P_infoPlatformType m19 : 8|8@1+ (1,0) [0|255] "" Vector__XXX
 SG_ OCS1P_infoBootUdsProtoVersion m20 : 8|8@1+ (1,0) [0|255] "" Vector__XXX
 SG_ OCS1P_infoBootloaderCRC m20 : 32|32@1+ (1,0) [0|4294967295] "" Vector__XXX

BO_ 771 OCS1P_status: 8 OCS1P
 SG_ OCS1P_occupantClassification : 0|8@1+ (1,0) [0|254] "" Vector__XXX
 SG_ OCS1P_occupantClassificationQF : 8|1@1+ (1,0) [0|1] "" Vector__XXX
 SG_ OCS1P_occupiedState : 9|2@1+ (1,0) [0|2] "" Vector__XXX
 SG_ OCS1P_triggerSnapshot : 11|5@1+ (1,0) [0|31] "" Vector__XXX
 SG_ OCS1P_occupantClassificationRaw : 16|3@1+ (1,0) [0|6] "" Vector__XXX
 SG_ OCS1P_occupantClassificationSelf : 19|3@1+ (1,0) [0|6] "" Vector__XXX
 SG_ OCS1P_occupantClassificationRawC : 22|3@1+ (1,0) [0|6] "" Vector__XXX
 SG_ OCS1P_occupantClassificationCap : 25|3@1+ (1,0) [0|6] "" Vector__XXX
 SG_ OCS1P_classificationHeld : 30|1@1+ (1,0) [0|1] "" Vector__XXX
 SG_ OCS1P_cushionStable : 31|1@1+ (1,0) [0|1] "" Vector__XXX
 SG_ OCS1P_classificationExtHold : 32|1@1+ (1,0) [0|1] "" Vector__XXX
 SG_ OCS1P_classificationHoldState : 33|3@1+ (1,0) [0|7] "" Vector__XXX
 SG_ OCS1P_classificationVariant : 36|3@1+ (1,0) [0|7] "" Vector__XXX
 SG_ OCS1P_sandwichDisabled : 39|1@1+ (1,0) [0|1] "" Vector__XXX
 SG_ OCS1P_noSandwichType : 40|2@1+ (1,0) [0|3] "" Vector__XXX
 SG_ OCS1P_sandwichBoundaryType : 42|1@1+ (1,0) [0|1] "" Vector__XXX
 SG_ OCS1P_sbrBoundaryType : 43|1@1+ (1,0) [0|1] "" Vector__XXX
 SG_ OCS1P_occupiedStateCap : 45|2@1+ (1,0) [0|2] "" Vector__XXX
 SG_ OCS1P_seatbackStable : 47|1@1+ (1,0) [0|1] "" Vector__XXX
 SG_ OCS1P_sandwichStable : 48|1@1+ (1,0) [0|1] "" Vector__XXX
 SG_ OCS1P_cushionStableCap : 49|1@1+ (1,0) [0|1] "" Vector__XXX
 SG_ OCS1P_seatbackStableCap : 50|1@1+ (1,0) [0|1] "" Vector__XXX
 SG_ OCS1P_classificationHeldCap : 51|1@1+ (1,0) [0|1] "" Vector__XXX
 SG_ OCS1P_statusCounter : 52|4@1+ (1,0) [0|15] "" Vector__XXX
 SG_ OCS1P_statusChecksum : 56|8@1+ (1,0) [0|255] "" Vector__XXX

BO_ 1619 OCS1P_udsResponse: 8 OCS1P
 SG_ OCS1P_udsResponseData : 0|64@1+ (1,0) [0|1.84467440737e+19] "" Vector__XXX

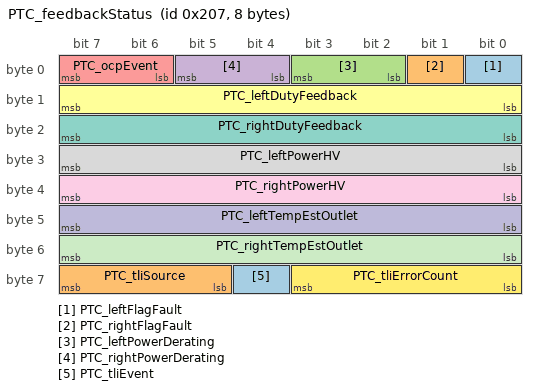
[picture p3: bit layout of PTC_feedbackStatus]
BO_ 519 PTC_feedbackStatus: 8 PTC
 SG_ PTC_leftFlagFault : 0|1@1+ (1,0) [0|1] "" Vector__XXX
 SG_ PTC_rightFlagFault : 1|1@1+ (1,0) [0|1] "" Vector__XXX
 SG_ PTC_leftPowerDerating : 2|2@1+ (1,0) [0|3] "" Vector__XXX
 SG_ PTC_rightPowerDerating : 4|2@1+ (1,0) [0|3] "" Vector__XXX
 SG_ PTC_ocpEvent : 6|2@1+ (1,0) [0|3] "" Vector__XXX
 SG_ PTC_leftDutyFeedback : 8|8@1+ (0.5,0) [0|100] "%" Vector__XXX
 SG_ PTC_rightDutyFeedback : 16|8@1+ (0.5,0) [0|100] "%" Vector__XXX
 SG_ PTC_leftPowerHV : 24|8@1+ (30,0) [0|7650] "W" Vector__XXX
 SG_ PTC_rightPowerHV : 32|8@1+ (30,0) [0|7650] "W" Vector__XXX
 SG_ PTC_leftTempEstOutlet : 40|8@1+ (1,-40) [-40|200] "degC" Vector__XXX
 SG_ PTC_rightTempEstOutlet : 48|8@1+ (1,-40) [-40|200] "degC" Vector__XXX
 SG_ PTC_tliErrorCount : 56|4@1+ (1,0) [0|15] "" Vector__XXX
 SG_ PTC_tliEvent : 60|1@1+ (1,0) [0|1] "" Vector__XXX
 SG_ PTC_tliSource : 61|3@1+ (1,0) [0|7] "" Vector__XXX

BO_ 1297 RCM_alertLog: 8 RCM
 SG_ RCM_alertID M : 0|10@1+ (1,0) [0|1023] "" Vector__XXX
 SG_ RCM_alertState : 10|1@1+ (1,0) [0|1] "" Vector__XXX
 SG_ RCM_a000_eventArmStatus m0 : 11|1@1+ (1,0) [0|1] "" Vector__XXX
 SG_ RCM_a000_eventFactoryMode m0 : 12|1@1+ (1,0) [0|1] "" Vector__XXX
 SG_ RCM_a000_eventDiagEnabled m0 : 13|1@1+ (1,0) [0|1] "" Vector__XXX
 SG_ RCM_a000_eventDriveOrientation m0 : 14|1@1+ (1,0) [0|1] "" Vector__XXX
 SG_ RCM_a000_crashDetectedFront m0 : 16|1@1+ (1,0) [0|1] "" Vector__XXX
 SG_ RCM_a000_crashDetectedRear m0 : 17|1@1+ (1,0) [0|1] "" Vector__XXX
 SG_ RCM_a000_crashDetectedLeft m0 : 18|1@1+ (1,0) [0|1] "" Vector__XXX
 SG_ RCM_a000_crashDetectedRight m0 : 19|1@1+ (1,0) [0|1] "" Vector__XXX
 SG_ RCM_a000_crashDetectedRoll m0 : 20|1@1+ (1,0) [0|1] "" Vector__XXX
 SG_ RCM_a000_crashDetectedPreten m0 : 21|1@1+ (1,0) [0|1] "" Vector__XXX
 SG_ RCM_a000_crashDetectedStage1 m0 : 22|1@1+ (1,0) [0|1] "" Vector__XXX
 SG_ RCM_a000_crashDetectedStage2 m0 : 23|1@1+ (1,0) [0|1] "" Vector__XXX
 SG_ RCM_a000_crashDetectedHVpyro m0 : 24|1@1+ (1,0) [0|1] "" Vector__XXX
 SG_ RCM_a000_eventIDFsignal m0 : 25|1@1+ (1,0) [0|1] "" Vector__XXX
 SG_ RCM_a000_eventFrontLeftSeatbelt m0 : 26|1@1+ (1,0) [0|1] "" Vector__XXX
 SG_ RCM_a000_eventFrontRightSeatbelt m0 : 27|1@1+ (1,0) [0|1] "" Vector__XXX
 SG_ RCM_a000_eventVehicleSpeed m0 : 28|12@1+ (0.08,-40) [-40|287.6] "kph" Vector__XXX
 SG_ RCM_a000_eventSteeringAngle m0 : 45|14@0+ (0.1,-819.2) [-819.2|819.1] "deg" Vector__XXX
 SG_ RCM_a000_eventDriverBrakeApply m0 : 46|2@1+ (1,0) [0|3] "" Vector__XXX
 SG_ RCM_a000_eventAccelPedalPos m0 : 56|8@1+ (0.4,0) [0|102] "%" Vector__XXX
 SG_ RCM_a001_eventArmStatus m1 : 11|1@1+ (1,0) [0|1] "" Vector__XXX
 SG_ RCM_a001_eventFactoryMode m1 : 12|1@1+ (1,0) [0|1] "" Vector__XXX
 SG_ RCM_a001_eventDiagEnabled m1 : 13|1@1+ (1,0) [0|1] "" Vector__XXX
 SG_ RCM_a001_eventDriveOrientation m1 : 14|1@1+ (1,0) [0|1] "" Vector__XXX
 SG_ RCM_a001_nearDeployFront m1 : 16|1@1+ (1,0) [0|1] "" Vector__XXX
 SG_ RCM_a001_nearDeployRear m1 : 17|1@1+ (1,0) [0|1] "" Vector__XXX
 SG_ RCM_a001_nearDeployLeft m1 : 18|1@1+ (1,0) [0|1] "" Vector__XXX
 SG_ RCM_a001_nearDeployRight m1 : 19|1@1+ (1,0) [0|1] "" Vector__XXX
 SG_ RCM_a001_nearDeployRoll m1 : 20|1@1+ (1,0) [0|1] "" Vector__XXX
 SG_ RCM_a001_nearDeployPretensioner m1 : 21|1@1+ (1,0) [0|1] "" Vector__XXX
 SG_ RCM_a001_eventIDFsignal m1 : 25|1@1+ (1,0) [0|1] "" Vector__XXX
 SG_ RCM_a001_eventFrontLeftSeatbelt m1 : 26|1@1+ (1,0) [0|1] "" Vector__XXX
 SG_ RCM_a001_eventFrontRightSeatbelt m1 : 27|1@1+ (1,0) [0|1] "" Vector__XXX
 SG_ RCM_a001_eventVehicleSpeed m1 : 28|12@1+ (0.08,-40) [-40|287.6] "kph" Vector__XXX
 SG_ RCM_a001_eventSteeringAngle m1 : 45|14@0+ (0.1,-819.2) [-819.2|819.1] "deg" Vector__XXX
 SG_ RCM_a001_eventDriverBrakeApply m1 : 46|2@1+ (1,0) [0|2] "" Vector__XXX
 SG_ RCM_a001_eventAccelPedalPos m1 : 56|8@1+ (0.4,0) [0|101.6] "%" Vector__XXX
 SG_ RCM_a002_eventArmStatus m2 : 11|1@1+ (1,0) [0|1] "" Vector__XXX
 SG_ RCM_a002_eventFactoryMode m2 : 12|1@1+ (1,0) [0|1] "" Vector__XXX
 SG_ RCM_a002_eventDiagEnabled m2 : 13|1@1+ (1,0) [0|1] "" Vector__XXX
 SG_ RCM_a002_eventDriveOrientation m2 : 14|1@1+ (1,0) [0|1] "" Vector__XXX
 SG_ RCM_a002_airbagsUnArmed m2 : 16|1@1+ (1,0) [0|1] "" Vector__XXX
 SG_ RCM_a002_eventIDFsignal m2 : 25|1@1+ (1,0) [0|1] "" Vector__XXX
 SG_ RCM_a002_eventFrontLeftSeatbelt m2 : 26|1@1+ (1,0) [0|1] "" Vector__XXX
 SG_ RCM_a002_eventFrontRightSeatbelt m2 : 27|1@1+ (1,0) [0|1] "" Vector__XXX
 SG_ RCM_a002_eventVehicleSpeed m2 : 28|12@1+ (0.08,-40) [-40|287.6] "kph" Vector__XXX
 SG_ RCM_a002_eventSteeringAngle m2 : 45|14@0+ (0.1,-819.2) [-819.2|819.1] "deg" Vector__XXX
 SG_ RCM_a002_eventDriverBrakeApply m2 : 46|2@1+ (1,0) [0|2] "" Vector__XXX
 SG_ RCM_a002_eventAccelPedalPos m2 : 56|8@1+ (0.4,0) [0|101.6] "%" Vector__XXX
 SG_ RCM_a003_eventArmStatus m3 : 11|1@1+ (1,0) [0|1] "" Vector__XXX
 SG_ RCM_a003_eventFactoryMode m3 : 12|1@1+ (1,0) [0|1] "" Vector__XXX
 SG_ RCM_a003_eventDiagEnabled m3 : 13|1@1+ (1,0) [0|1] "" Vector__XXX
 SG_ RCM_a003_eventDriveOrientation m3 : 14|1@1+ (1,0) [0|1] "" Vector__XXX
 SG_ RCM_a003_warningIndicatorOn m3 : 16|1@1+ (1,0) [0|1] "" Vector__XXX
 SG_ RCM_a003_eventIDFsignal m3 : 25|1@1+ (1,0) [0|1] "" Vector__XXX
 SG_ RCM_a003_eventFrontLeftSeatbelt m3 : 26|1@1+ (1,0) [0|1] "" Vector__XXX
 SG_ RCM_a003_eventFrontRightSeatbelt m3 : 27|1@1+ (1,0) [0|1] "" Vector__XXX
 SG_ RCM_a003_eventVehicleSpeed m3 : 28|12@1+ (0.08,-40) [-40|287.6] "kph" Vector__XXX
 SG_ RCM_a003_eventSteeringAngle m3 : 45|14@0+ (0.1,-819.2) [-819.2|819.1] "deg" Vector__XXX
 SG_ RCM_a003_eventDriverBrakeApply m3 : 46|2@1+ (1,0) [0|2] "" Vector__XXX
 SG_ RCM_a003_eventAccelPedalPos m3 : 56|8@1+ (0.4,0) [0|101.6] "%" Vector__XXX
 SG_ RCM_a004_eventArmStatus m4 : 11|1@1+ (1,0) [0|1] "" Vector__XXX
 SG_ RCM_a004_eventFactoryMode m4 : 12|1@1+ (1,0) [0|1] "" Vector__XXX
 SG_ RCM_a004_eventDiagEnabled m4 : 13|1@1+ (1,0) [0|1] "" Vector__XXX
 SG_ RCM_a004_eventDriveOrientation m4 : 14|1@1+ (1,0) [0|1] "" Vector__XXX
 SG_ RCM_a004_frontAlgoDisabled m4 : 16|1@1+ (1,0) [0|1] "" Vector__XXX
 SG_ RCM_a004_sideAlgoDisabled m4 : 17|1@1+ (1,0) [0|1] "" Vector__XXX
 SG_ RCM_a004_rollAlgoDisabled m4 : 18|1@1+ (1,0) [0|1] "" Vector__XXX
 SG_ RCM_a004_idleMode m4 : 19|1@1+ (1,0) [0|1] "" Vector__XXX
 SG_ RCM_a004_internalFaultDetected m4 : 20|1@1+ (1,0) [0|1] "" Vector__XXX
 SG_ RCM_a004_swVersionMismatch m4 : 21|1@1+ (1,0) [0|1] "" Vector__XXX
 SG_ RCM_a004_paramLayoutIDInv m4 : 22|1@1+ (1,0) [0|1] "" Vector__XXX
 SG_ RCM_a004_algoPASIDMismatch m4 : 23|1@1+ (1,0) [0|1] "" Vector__XXX
 SG_ RCM_a004_eventIDFsignal m4 : 25|1@1+ (1,0) [0|1] "" Vector__XXX
 SG_ RCM_a004_eventFrontLeftSeatbelt m4 : 26|1@1+ (1,0) [0|1] "" Vector__XXX
 SG_ RCM_a004_eventFrontRightSeatbelt m4 : 27|1@1+ (1,0) [0|1] "" Vector__XXX
 SG_ RCM_a004_eventVehicleSpeed m4 : 28|12@1+ (0.08,-40) [-40|287.6] "kph" Vector__XXX
 SG_ RCM_a004_eventSteeringAngle m4 : 45|14@0+ (0.1,-819.2) [-819.2|819.1] "deg" Vector__XXX
 SG_ RCM_a004_eventDriverBrakeApply m4 : 46|2@1+ (1,0) [0|2] "" Vector__XXX
 SG_ RCM_a004_eventAccelPedalPos m4 : 56|8@1+ (0.4,0) [0|101.6] "%" Vector__XXX
 SG_ RCM_a005_eventArmStatus m5 : 11|1@1+ (1,0) [0|1] "" Vector__XXX
 SG_ RCM_a005_eventFactoryMode m5 : 12|1@1+ (1,0) [0|1] "" Vector__XXX
 SG_ RCM_a005_eventDiagEnabled m5 : 13|1@1+ (1,0) [0|1] "" Vector__XXX
 SG_ RCM_a005_eventDriveOrientation m5 : 14|1@1+ (1,0) [0|1] "" Vector__XXX
 SG_ RCM_a005_externalCRCError m5 : 16|1@1+ (1,0) [0|1] "" Vector__XXX
 SG_ RCM_a005_eventIDFsignal m5 : 25|1@1+ (1,0) [0|1] "" Vector__XXX
 SG_ RCM_a005_eventFrontLeftSeatbelt m5 : 26|1@1+ (1,0) [0|1] "" Vector__XXX
 SG_ RCM_a005_eventFrontRightSeatbelt m5 : 27|1@1+ (1,0) [0|1] "" Vector__XXX
 SG_ RCM_a005_eventVehicleSpeed m5 : 28|12@1+ (0.08,-40) [-40|287.6] "kph" Vector__XXX
 SG_ RCM_a005_eventSteeringAngle m5 : 45|14@0+ (0.1,-819.2) [-819.2|819.1] "deg" Vector__XXX
 SG_ RCM_a005_eventDriverBrakeApply m5 : 46|2@1+ (1,0) [0|2] "" Vector__XXX
 SG_ RCM_a005_eventAccelPedalPos m5 : 56|8@1+ (0.4,0) [0|101.6] "%" Vector__XXX
 SG_ RCM_a006_eventArmStatus m6 : 11|1@1+ (1,0) [0|1] "" Vector__XXX
 SG_ RCM_a006_eventFactoryMode m6 : 12|1@1+ (1,0) [0|1] "" Vector__XXX
 SG_ RCM_a006_eventDiagEnabled m6 : 13|1@1+ (1,0) [0|1] "" Vector__XXX
 SG_ RCM_a006_eventDriveOrientation m6 : 14|1@1+ (1,0) [0|1] "" Vector__XXX
 SG_ RCM_a006_batteryVoltageTooHigh m6 : 16|1@1+ (1,0) [0|1] "" Vector__XXX
 SG_ RCM_a006_batteryVoltageTooLow m6 : 17|1@1+ (1,0) [0|1] "" Vector__XXX
 SG_ RCM_a006_eventIDFsignal m6 : 25|1@1+ (1,0) [0|1] "" Vector__XXX
 SG_ RCM_a006_eventFrontLeftSeatbelt m6 : 26|1@1+ (1,0) [0|1] "" Vector__XXX
 SG_ RCM_a006_eventFrontRightSeatbelt m6 : 27|1@1+ (1,0) [0|1] "" Vector__XXX
 SG_ RCM_a006_eventVehicleSpeed m6 : 28|12@1+ (0.08,-40) [-40|287.6] "kph" Vector__XXX
 SG_ RCM_a006_eventSteeringAngle m6 : 45|14@0+ (0.1,-819.2) [-819.2|819.1] "deg" Vector__XXX
 SG_ RCM_a006_eventDriverBrakeApply m6 : 46|2@1+ (1,0) [0|2] "" Vector__XXX
 SG_ RCM_a006_eventAccelPedalPos m6 : 56|8@1+ (0.4,0) [0|101.6] "%" Vector__XXX
 SG_ RCM_a008_eventArmStatus m8 : 11|1@1+ (1,0) [0|1] "" Vector__XXX
 SG_ RCM_a008_eventFactoryMode m8 : 12|1@1+ (1,0) [0|1] "" Vector__XXX
 SG_ RCM_a008_eventDiagEnabled m8 : 13|1@1+ (1,0) [0|1] "" Vector__XXX
 SG_ RCM_a008_eventDriveOrientation m8 : 14|1@1+ (1,0) [0|1] "" Vector__XXX
 SG_ RCM_a008_lossOfMainPwrSupMonit m8 : 16|1@1+ (1,0) [0|1] "" Vector__XXX
 SG_ RCM_a008_lossOfBckupPwrSupMonit m8 : 17|1@1+ (1,0) [0|1] "" Vector__XXX
 SG_ RCM_a008_normalShtdwnUnavail m8 : 18|1@1+ (1,0) [0|1] "" Vector__XXX
 SG_ RCM_a008_eventIDFsignal m8 : 25|1@1+ (1,0) [0|1] "" Vector__XXX
 SG_ RCM_a008_eventFrontLeftSeatbelt m8 : 26|1@1+ (1,0) [0|1] "" Vector__XXX
 SG_ RCM_a008_eventFrontRightSeatbelt m8 : 27|1@1+ (1,0) [0|1] "" Vector__XXX
 SG_ RCM_a008_eventVehicleSpeed m8 : 28|12@1+ (0.08,-40) [-40|287.6] "kph" Vector__XXX
 SG_ RCM_a008_eventSteeringAngle m8 : 45|14@0+ (0.1,-819.2) [-819.2|819.1] "deg" Vector__XXX
 SG_ RCM_a008_eventDriverBrakeApply m8 : 46|2@1+ (1,0) [0|2] "" Vector__XXX
 SG_ RCM_a008_eventAccelPedalPos m8 : 56|8@1+ (0.4,0) [0|101.6] "%" Vector__XXX
 SG_ RCM_a009_eventArmStatus m9 : 11|1@1+ (1,0) [0|1] "" Vector__XXX
 SG_ RCM_a009_eventFactoryMode m9 : 12|1@1+ (1,0) [0|1] "" Vector__XXX
 SG_ RCM_a009_eventDiagEnabled m9 : 13|1@1+ (1,0) [0|1] "" Vector__XXX
 SG_ RCM_a009_eventDriveOrientation m9 : 14|1@1+ (1,0) [0|1] "" Vector__XXX
 SG_ RCM_a009_reprogramLimitExceeded m9 : 16|1@1+ (1,0) [0|1] "" Vector__XXX
 SG_ RCM_a009_eventIDFsignal m9 : 25|1@1+ (1,0) [0|1] "" Vector__XXX
 SG_ RCM_a009_eventFrontLeftSeatbelt m9 : 26|1@1+ (1,0) [0|1] "" Vector__XXX
 SG_ RCM_a009_eventFrontRightSeatbelt m9 : 27|1@1+ (1,0) [0|1] "" Vector__XXX
 SG_ RCM_a009_eventVehicleSpeed m9 : 28|12@1+ (0.08,-40) [-40|287.6] "kph" Vector__XXX
 SG_ RCM_a009_eventSteeringAngle m9 : 45|14@0+ (0.1,-819.2) [-819.2|819.1] "deg" Vector__XXX
 SG_ RCM_a009_eventDriverBrakeApply m9 : 46|2@1+ (1,0) [0|2] "" Vector__XXX
 SG_ RCM_a009_eventAccelPedalPos m9 : 56|8@1+ (0.4,0) [0|101.6] "%" Vector__XXX
 SG_ RCM_a011_eventArmStatus m11 : 11|1@1+ (1,0) [0|1] "" Vector__XXX
 SG_ RCM_a011_eventFactoryMode m11 : 12|1@1+ (1,0) [0|1] "" Vector__XXX
 SG_ RCM_a011_eventDiagEnabled m11 : 13|1@1+ (1,0) [0|1] "" Vector__XXX
 SG_ RCM_a011_eventDriveOrientation m11 : 14|1@1+ (1,0) [0|1] "" Vector__XXX
 SG_ RCM_a011_edrDataAreaLocked m11 : 16|1@1+ (1,0) [0|1] "" Vector__XXX
 SG_ RCM_a011_eventIDFsignal m11 : 25|1@1+ (1,0) [0|1] "" Vector__XXX
 SG_ RCM_a011_eventFrontLeftSeatbelt m11 : 26|1@1+ (1,0) [0|1] "" Vector__XXX
 SG_ RCM_a011_eventFrontRightSeatbelt m11 : 27|1@1+ (1,0) [0|1] "" Vector__XXX
 SG_ RCM_a011_eventVehicleSpeed m11 : 28|12@1+ (0.08,-40) [-40|287.6] "kph" Vector__XXX
 SG_ RCM_a011_eventSteeringAngle m11 : 45|14@0+ (0.1,-819.2) [-819.2|819.1] "deg" Vector__XXX
 SG_ RCM_a011_eventDriverBrakeApply m11 : 46|2@1+ (1,0) [0|2] "" Vector__XXX
 SG_ RCM_a011_eventAccelPedalPos m11 : 56|8@1+ (0.4,0) [0|101.6] "%" Vector__XXX
 SG_ RCM_a012_eventArmStatus m12 : 11|1@1+ (1,0) [0|1] "" Vector__XXX
 SG_ RCM_a012_eventFactoryMode m12 : 12|1@1+ (1,0) [0|1] "" Vector__XXX
 SG_ RCM_a012_eventDiagEnabled m12 : 13|1@1+ (1,0) [0|1] "" Vector__XXX
 SG_ RCM_a012_eventDriveOrientation m12 : 14|1@1+ (1,0) [0|1] "" Vector__XXX
 SG_ RCM_a012_vinMismatch m12 : 16|1@1+ (1,0) [0|1] "" Vector__XXX
 SG_ RCM_a012_vinNotProgrammed m12 : 17|1@1+ (1,0) [0|1] "" Vector__XXX
 SG_ RCM_a012_eventIDFsignal m12 : 25|1@1+ (1,0) [0|1] "" Vector__XXX
 SG_ RCM_a012_eventFrontLeftSeatbelt m12 : 26|1@1+ (1,0) [0|1] "" Vector__XXX
 SG_ RCM_a012_eventFrontRightSeatbelt m12 : 27|1@1+ (1,0) [0|1] "" Vector__XXX
 SG_ RCM_a012_eventVehicleSpeed m12 : 28|12@1+ (0.08,-40) [-40|287.6] "kph" Vector__XXX
 SG_ RCM_a012_eventSteeringAngle m12 : 45|14@0+ (0.1,-819.2) [-819.2|819.1] "deg" Vector__XXX
 SG_ RCM_a012_eventDriverBrakeApply m12 : 46|2@1+ (1,0) [0|2] "" Vector__XXX
 SG_ RCM_a012_eventAccelPedalPos m12 : 56|8@1+ (0.4,0) [0|101.6] "%" Vector__XXX
 SG_ RCM_a013_eventArmStatus m13 : 11|1@1+ (1,0) [0|1] "" Vector__XXX
 SG_ RCM_a013_eventFactoryMode m13 : 12|1@1+ (1,0) [0|1] "" Vector__XXX
 SG_ RCM_a013_eventDiagEnabled m13 : 13|1@1+ (1,0) [0|1] "" Vector__XXX
 SG_ RCM_a013_eventDriveOrientation m13 : 14|1@1+ (1,0) [0|1] "" Vector__XXX
 SG_ RCM_a013_driveOrientiInitNotDone m13 : 16|1@1+ (1,0) [0|1] "" Vector__XXX
 SG_ RCM_a013_driveOrientPlausiCheck m13 : 17|1@1+ (1,0) [0|1] "" Vector__XXX
 SG_ RCM_a013_eventIDFsignal m13 : 25|1@1+ (1,0) [0|1] "" Vector__XXX
 SG_ RCM_a013_eventFrontLeftSeatbelt m13 : 26|1@1+ (1,0) [0|1] "" Vector__XXX
 SG_ RCM_a013_eventFrontRightSeatbelt m13 : 27|1@1+ (1,0) [0|1] "" Vector__XXX
 SG_ RCM_a013_eventVehicleSpeed m13 : 28|12@1+ (0.08,-40) [-40|287.6] "kph" Vector__XXX
 SG_ RCM_a013_eventSteeringAngle m13 : 45|14@0+ (0.1,-819.2) [-819.2|819.1] "deg" Vector__XXX
 SG_ RCM_a013_eventDriverBrakeApply m13 : 46|2@1+ (1,0) [0|2] "" Vector__XXX
 SG_ RCM_a013_eventAccelPedalPos m13 : 56|8@1+ (0.4,0) [0|101.6] "%" Vector__XXX
 SG_ RCM_a014_eventArmStatus m14 : 11|1@1+ (1,0) [0|1] "" Vector__XXX
 SG_ RCM_a014_eventFactoryMode m14 : 12|1@1+ (1,0) [0|1] "" Vector__XXX
 SG_ RCM_a014_eventDiagEnabled m14 : 13|1@1+ (1,0) [0|1] "" Vector__XXX
 SG_ RCM_a014_eventDriveOrientation m14 : 14|1@1+ (1,0) [0|1] "" Vector__XXX
 SG_ RCM_a014_driverABStg1Sht2Gnd m14 : 16|1@1+ (1,0) [0|1] "" Vector__XXX
 SG_ RCM_a014_driverABStg1Sht2Bat m14 : 17|1@1+ (1,0) [0|1] "" Vector__XXX
 SG_ RCM_a014_driverABStg1Open m14 : 18|1@1+ (1,0) [0|1] "" Vector__XXX
 SG_ RCM_a014_driverABStg1Short m14 : 19|1@1+ (1,0) [0|1] "" Vector__XXX
 SG_ RCM_a014_driverABStg1CrossCoup m14 : 20|1@1+ (1,0) [0|1] "" Vector__XXX
 SG_ RCM_a014_driverABStg1Config m14 : 21|1@1+ (1,0) [0|1] "" Vector__XXX
 SG_ RCM_a014_eventIDFsignal m14 : 25|1@1+ (1,0) [0|1] "" Vector__XXX
 SG_ RCM_a014_eventFrontLeftSeatbelt m14 : 26|1@1+ (1,0) [0|1] "" Vector__XXX
 SG_ RCM_a014_eventFrontRightSeatbelt m14 : 27|1@1+ (1,0) [0|1] "" Vector__XXX
 SG_ RCM_a014_eventVehicleSpeed m14 : 28|12@1+ (0.08,-40) [-40|287.6] "kph" Vector__XXX

BO_TX_BU_ 2047 : GTW;
BO_TX_BU_ 792 : GTW;
BO_TX_BU_ 1638 : GTW;
BO_TX_BU_ 1080 : GTW;
BO_TX_BU_ 1376 : GTW;
BO_TX_BU_ 1656 : GTW;
BO_TX_BU_ 2033 : GTW;
BO_TX_BU_ 2026 : GTW;
BO_TX_BU_ 60 : GTW;
BO_TX_BU_ 1370 : GTW;
BO_TX_BU_ 840 : GTW;
BO_TX_BU_ 1005 : GTW;
BO_TX_BU_ 1112 : GTW;
BO_TX_BU_ 1429 : OCS1P;
BO_TX_BU_ 767 : OCS1P;
BO_TX_BU_ 766 : OCS1P;
BO_TX_BU_ 771 : OCS1P;
BO_TX_BU_ 1619 : OCS1P;
BO_TX_BU_ 519 : PTC;
BO_TX_BU_ 1297 : RCM;
CM_ BO_ 2047 "Gateway message: car config";
CM_ SG_ 2047 GTW_carConfigMultiplexer "Gateway: car config multiplexer";
CM_ SG_ 2047 GTW_deliveryStatus "Indicates whether the vehicle has been marked delivered to the customer in Tesla backend systems.";
CM_ SG_ 2047 GTW_cabinPTCHeaterType "Gateway: cabin PTC heater type";
CM_ SG_ 2047 GTW_rightHandDrive "Gateway: right hand drive";
CM_ SG_ 2047 GTW_rearLightType "Gateway: rear light type";
CM_ SG_ 2047 GTW_headlamps "Gateway: headlamps";
CM_ SG_ 2047 GTW_country "Gateway: country";
CM_ SG_ 2047 GTW_tireType "Gateway: tire type";
CM_ SG_ 2047 GTW_dasHw "Indicates the Driver Assistance System (DAS) hardware installed.";
CM_ SG_ 2047 GTW_brakeHWType "Gateway: brake HW type";
CM_ SG_ 2047 GTW_restraintsHardwareType "Gateway: restraints hardware type";
CM_ SG_ 2047 GTW_drivetrainType "Gateway: drivetrain type";
CM_ SG_ 2047 GTW_radarHeaterType "Gateway: radar heater type";
CM_ SG_ 2047 GTW_exteriorTrimType "Gateway: exterior trim type";
CM_ SG_ 2047 GTW_frontSeatHeaters "Gateway: front seat heaters";
CM_ SG_ 2047 GTW_rearSeatHeaters "Gateway: rear seat heaters";
CM_ SG_ 2047 GTW_eCallAntennaHW "Gateway: e call antenna HW";
CM_ SG_ 2047 GTW_homelinkType "Gateway: homelink type";
CM_ SG_ 2047 GTW_vdcType "Gateway: vdc type";
CM_ SG_ 2047 GTW_memoryMirrors "Gateway: memory mirrors";
CM_ SG_ 2047 GTW_powerLiftgateType "Gateway: power liftgate type";
CM_ SG_ 2047 GTW_lumbarECUType "Gateway: lumbar ECU type";
CM_ SG_ 2047 GTW_rearSeatHeaterType "Gateway: rear seat heater type";
CM_ SG_ 2047 GTW_auxParkLamps "Gateway: aux park lamps";
CM_ SG_ 2047 GTW_interiorCabinRadarType "Gateway: interior cabin radar type";
CM_ SG_ 2047 GTW_hvacPanelVaneType "Gateway: hvac panel vane type";
CM_ SG_ 2047 GTW_intakeAirFilterType "Gateway: intake air filter type";
CM_ SG_ 2047 GTW_eBuckConfig "Gateway: e buck config";
CM_ SG_ 2047 GTW_steeringHeaterEnabled "Gateway: steering heater enabled";
CM_ SG_ 2047 GTW_activeHighBeam "Gateway: active high beam";
CM_ SG_ 2047 GTW_airbagCutoffSwitch "Gateway: airbag cutoff switch";
CM_ SG_ 2047 GTW_intrusionSensorType "Gateway: intrusion sensor type";
CM_ SG_ 2047 GTW_spoilerType "Gateway: spoiler type";
CM_ SG_ 2047 GTW_backupCameraType "Gateway: backup camera type";
CM_ SG_ 2047 GTW_rearFogLamps "Gateway: rear fog lamps";
CM_ SG_ 2047 GTW_roofType "Gateway: roof type";
CM_ SG_ 2047 GTW_thirdRowSeatType "Gateway: third row seat type";
CM_ SG_ 2047 GTW_autopilot "Gateway: autopilot";
CM_ SG_ 2047 GTW_superchargingAccess "Gateway: supercharging access";
CM_ SG_ 2047 GTW_exteriorColor "Gateway: exterior color";
CM_ SG_ 2047 GTW_pedestrianWarningSound "Gateway: pedestrian warning sound";
CM_ SG_ 2047 GTW_steeringColumnUJointType "Gateway: steering column u joint type";
CM_ SG_ 2047 GTW_bPillarNFCParam "Gateway: b pillar NFC param";
CM_ SG_ 2047 GTW_interiorLighting "Gateway: interior lighting";
CM_ SG_ 2047 GTW_headlightLevelerType "Gateway: headlight leveler type";
CM_ SG_ 2047 GTW_numberHVILNodes "Gateway: number HVIL nodes";
CM_ SG_ 2047 GTW_mapRegion "Gateway: map region";
CM_ SG_ 2047 GTW_performancePackage "Gateway: performance package";
CM_ SG_ 2047 GTW_chassisType "Indicates the chassis type, which determines physical aspects such as suspension geometry, track width, wheel base, baseline tire size, and trailer capability.";
CM_ SG_ 2047 GTW_airSuspension "Gateway: air suspension";
CM_ SG_ 2047 GTW_centerConsoleControllerType "Gateway: center console controller type";
CM_ SG_ 2047 GTW_autopilotCameraType "Gateway: autopilot camera type";
CM_ SG_ 2047 GTW_connectivityPackage "Gateway: connectivity package";
CM_ SG_ 2047 GTW_plcSupportType "Gateway: plc support type";
CM_ SG_ 2047 GTW_badgingVersion "Gateway: badging version";
CM_ SG_ 2047 GTW_packEnergy "Gateway: pack energy";
CM_ SG_ 2047 GTW_frontSeatReclinerHardware "Gateway: front seat recliner hardware";
CM_ SG_ 2047 GTW_brakeLineSwitchType "Gateway: brake line switch type";
CM_ SG_ 2047 GTW_espValveType "Gateway: esp valve type";
CM_ SG_ 2047 GTW_softRange "Gateway: soft range";
CM_ SG_ 2047 GTW_refrigerantType "Gateway: refrigerant type";
CM_ SG_ 2047 GTW_wheelType "Gateway: wheel type";
CM_ SG_ 2047 GTW_ptcControlMode "Gateway: ptc control mode";
CM_ SG_ 2047 GTW_brakeActuationType "Gateway: brake actuation type";
CM_ SG_ 2047 GTW_secondRowSeatType "Gateway: second row seat type";
CM_ SG_ 2047 GTW_secondRowSeatMotorType "Gateway: second row seat motor type";
CM_ SG_ 2047 GTW_birthday "Gateway: birthday";
CM_ SG_ 2047 GTW_eCallEnabled "Gateway: e call enabled";
CM_ SG_ 2047 GTW_parkAssistECUType "Gateway: park assist ECU type";
CM_ SG_ 2047 GTW_passengerAirbagType "Gateway: passenger airbag type";
CM_ SG_ 2047 GTW_forwardRadarHw "Gateway: forward radar hw";
CM_ SG_ 2047 GTW_frontSeatType "Gateway: front seat type";
CM_ SG_ 2047 GTW_secondRowDisplayType "Gateway: second row display type";
CM_ SG_ 2047 GTW_wirelessPhoneChargerType "Gateway: wireless phone charger type";
CM_ SG_ 2047 GTW_ethernetTunerType "Gateway: ethernet tuner type";
CM_ SG_ 2047 GTW_interiorTrimType "Gateway: interior trim type";
CM_ SG_ 2047 GTW_gloveboxUSBType "Gateway: glovebox USB type";
CM_ SG_ 2047 GTW_coolantPumpType "Gateway: coolant pump type";
CM_ SG_ 2047 GTW_epblHwType "Gateway: epbl hw type";
CM_ SG_ 2047 GTW_epbrHwType "Gateway: epbr hw type";
CM_ SG_ 2047 GTW_blowerMotorType "Gateway: blower motor type";
CM_ SG_ 2047 GTW_rearLeftBLEEndpointParameter "Gateway: rear left BLE endpoint parameter type";
CM_ SG_ 2047 GTW_powerMirrorFoldType "Gateway: power mirror fold type";
CM_ SG_ 2047 GTW_frontUsbHubType "Gateway: front usb hub type";
CM_ SG_ 2047 GTW_superManifoldType "Type of HVAC super manifold installed";
CM_ SG_ 2047 GTW_rcmLocation "Gateway: rcm location";
CM_ SG_ 2047 GTW_autopilotExteriorCameraType "Gateway: autopilot exterior camera type";
CM_ SG_ 2047 GTW_interiorCamBeautyCoverType "Gateway: interior cam beauty cover type";
CM_ SG_ 2047 GTW_sirenType "Gateway: siren type";
CM_ SG_ 2047 GTW_hornType "Gateway: horn type";
CM_ SG_ 2047 GTW_passengerTrackMotorType "Gateway: passenger track motor type";
CM_ SG_ 2047 GTW_steeringColumnMotorType "Gateway: steering column motor type";
CM_ SG_ 2047 GTW_refrigACLineType "Gateway: refrig AC line type";
CM_ SG_ 2047 GTW_refrigFilterType "Gateway: refrig filter type";
CM_ SG_ 2047 GTW_diBurnInType "Gateway: di burn in type";
CM_ SG_ 2047 GTW_specialBadgingType "Gateway: special badging type";
CM_ SG_ 2047 GTW_chassisSubType "Reports chassis sub-variant type.";
CM_ SG_ 2047 GTW_towPackage "Gateway: tow package";
CM_ SG_ 2047 GTW_refrigLccType "Gateway: refrig lcc type";
CM_ SG_ 2047 GTW_restraintControlsType "Gateway: restraint controls type";
CM_ SG_ 2047 GTW_caliperColorType "Gateway: caliper color type";
CM_ SG_ 2047 GTW_wiperMotorType "Gateway: wiper motor type";
CM_ SG_ 2047 GTW_frontOverheadConsoleType "Gateway: front overhead console type";
CM_ SG_ 2047 GTW_shifterType "Gateway: shifter type";
CM_ SG_ 2047 GTW_compressorType "Gateway: compressor type";
CM_ SG_ 2047 GTW_twelveVBatteryType "Gateway: twelve v battery type";
CM_ SG_ 2047 GTW_efuseSWConfig "Gateway: efuse SW config";
CM_ SG_ 2047 GTW_tollCollectionModuleType "Gateway: toll collection module type";
CM_ SG_ 2047 GTW_bleEndpointUpdateMethod "Gateway: ble endpoint update method";
CM_ SG_ 2047 GTW_steeringWheelControllerType "Gateway: steering wheel controller type";
CM_ SG_ 2047 GTW_frontSeatVentilationEnabled "Gateway: front seat ventilation enabled";
CM_ SG_ 2047 GTW_gloveboxActuatorType "Gateway: glovebox actuator type";
CM_ SG_ 2047 GTW_epasType "Gateway: epas type";
CM_ SG_ 2047 GTW_homologationRegionOverride "Gateway: homologation region override";
CM_ SG_ 2047 GTW_windowCommandsPermissionType "Gateway: window commands permission type";
CM_ SG_ 2047 GTW_headlightStepperStallDetectM "Gateway: headlight stepper stall detect mode";
CM_ SG_ 2047 GTW_rgbInteriorLightingEnabled "Gateway: rgb interior lighting enabled";
CM_ SG_ 2047 GTW_windshieldWiperHeaterType "Gateway: windshield wiper heater type";
CM_ SG_ 2047 GTW_thirdRowSeatReclinerType "Gateway: third row seat recliner type";
CM_ SG_ 2047 GTW_driveInterfaceType "Gateway: drive interface type";
CM_ SG_ 2047 GTW_efficiencyPackage "Gateway: efficiency package";
CM_ SG_ 2047 GTW_visorLightType "Gateway: visor light type";
CM_ SG_ 2047 GTW_gnssAntennaType "Gateway: gnss antenna type";
CM_ SG_ 2047 GTW_airDistributionBoxType "Gateway: air distribution box type";
CM_ SG_ 2047 GTW_frontSeatHeatersEnabled "Gateway: front seat heaters enabled";
CM_ SG_ 2047 GTW_windshieldWiperHeaterEnabled "Gateway: windshield wiper heater enabled";
CM_ SG_ 2047 GTW_alcoholInterlockType "Gateway: alcohol interlock type";
CM_ SG_ 2047 GTW_fasciaType "Gateway: fascia type";
CM_ SG_ 2047 GTW_powerSteeringColumn "Gateway: power steering column";
CM_ SG_ 2047 GTW_frontSeatHeaterType "Gateway: front seat heater type";
CM_ SG_ 2047 GTW_softPerformanceLimit "Gateway: soft performance limit";
CM_ SG_ 2047 GTW_gsrFeatureType "Gateway: gsr feature type";
CM_ SG_ 2047 GTW_immersiveAudio "Gateway: immersive audio";
CM_ SG_ 2047 GTW_frontSeatVentilationType "Gateway: front seat ventilation type";
CM_ SG_ 2047 GTW_passengerOccupancySensorType "Gateway: passenger occupancy sensor type";
CM_ SG_ 2047 GTW_packPerformanceDeviation "Measures deviation from standard pack mass or power output capability associated with the vehicle packEnergy configuration.";
CM_ SG_ 2047 GTW_pressurePadType "Gateway: pressure pad type";
CM_ SG_ 2047 GTW_frontFogLamps "Gateway: front fog lamps";
CM_ SG_ 2047 GTW_driverOccupancySensorType "Gateway: driver occupancy sensor type";
CM_ SG_ 2047 GTW_audioType "Gateway: audio type";
CM_ SG_ 2047 GTW_thighExtenderType "Gateway: thigh extender type";
CM_ SG_ 2047 GTW_occupancyClassificationFeatu "Gateway: occupancy classification feature type";
CM_ SG_ 2047 GTW_frontControllerArchitectureT "Reports internal microcontroller architecture of the Front Controller assembly, which contains the Front Vehicle Controller (VCFRONT) and may contain a Vehicle Battery Controller (VCBATT).";
CM_ SG_ 2047 GTW_domeLightType "Gateway: dome light type";
CM_ SG_ 2047 GTW_tpmsType "Gateway: tpms type";
CM_ SG_ 2047 GTW_authenticationEndpointLayout "Gateway: authentication endpoint layout";
CM_ SG_ 2047 GTW_socSleepOverride "Gateway: soc sleep override";
CM_ SG_ 2047 GTW_r79BehaviorOverride "Gateway: r79 behavior override";
CM_ SG_ 2047 GTW_steeringHeaterType "Gateway: steering heater type";
CM_ SG_ 2047 GTW_narrowWipingSupported "Gateway: narrow wiping supported";
CM_ SG_ 2047 GTW_frontSeatHeaterGridType "Gateway: front seat heater grid type";
CM_ SG_ 2047 GTW_frontSeatSideSwitchType "Gateway: front seat side switch type";
CM_ SG_ 2047 GTW_sohRegulatoryStatus "Gateway: soh regulatory status";
CM_ SG_ 2047 GTW_passengerTiltMotorType "Gateway: passenger tilt motor type";
CM_ SG_ 2047 GTW_frunkInteriorReleaseType "Gateway: frunk interior release type";
CM_ SG_ 2047 GTW_m3yBusArchitecture "Reports notable features of vehicle communication bus architecture. Used for firmware artifact selection during update installation process.";
CM_ SG_ 2047 GTW_passengerLiftMotorType "Gateway: passenger lift motor type";
CM_ SG_ 2047 GTW_interiorUpperTrimType "Gateway: interior upper trim type";
CM_ SG_ 2047 GTW_blindSpotIndicatorLightType "Gateway: blind spot indicator light type";
CM_ SG_ 2047 GTW_wiperMotorAsicType "Gateway: wiper motor asic type";
CM_ SG_ 2047 GTW_hvacCaseDoorType "Gateway: hvac case door type";
CM_ SG_ 2047 GTW_occupancyDetectionSourceRequ "Gateway: occupancy detection source request";
CM_ SG_ 2047 GTW_rduCableType "Indicates type of rear drive unit cable installed on vehicle.";
CM_ SG_ 2047 GTW_parkTelltaleBehaviorType "Gateway: park telltale behavior type";
CM_ SG_ 2047 GTW_numberKeyCardsPairedInFactor "Gateway: number key cards paired in factory";
CM_ SG_ 2047 GTW_secondRowSeatVentilationType "Gateway: second row seat ventilation type";
CM_ SG_ 2047 GTW_thirdRowSeatHeaterType "Gateway: third row seat heater type";
CM_ SG_ 2047 GTW_interiorCameraType "Gateway: interior camera type";
CM_ SG_ 2047 GTW_frontFasciaCameraType "Reports type of forward facing fascia camera installed.";
CM_ SG_ 2047 GTW_interiorCamFanType "Gateway: interior cam fan type";
CM_ SG_ 2047 GTW_puddleLampType "Gateway: puddle lamp type";
CM_ SG_ 2047 GTW_solarLensType "Gateway: solar lens type";
CM_ SG_ 2047 GTW_liftgateGeometryType "Gateway: liftgate geometry type";
CM_ SG_ 2047 GTW_repeaterAeroRibType "Gateway: repeater aero rib type";
CM_ SG_ 2047 GTW_highTipForceWiperArmsType "Gateway: high tip force wiper arms type";
CM_ SG_ 2047 GTW_rcmUndersideAbuseZThreshold "Gateway: rcm underside abuse z threshold";
CM_ SG_ 2047 GTW_rcmUndersideAbuseYThreshold "Gateway: rcm underside abuse y threshold";
CM_ SG_ 2047 GTW_rcmUndersideAbuseWindow "Gateway: rcm underside abuse window";
CM_ SG_ 2047 GTW_uhfChargePortEnabled "Gateway: uhf charge port enabled";
CM_ SG_ 2047 GTW_automaticFeatureResetPackage "Gateway: automatic feature reset package";
CM_ SG_ 2047 GTW_autopilotFeaturePackage "Gateway: autopilot feature package";
CM_ SG_ 2047 GTW_doorLatchType "Gateway: door latch type";
CM_ SG_ 2047 GTW_headlinerMaterialType "Gateway: headliner material type";
CM_ SG_ 2047 GTW_glareShieldHeaterType "Gateway: glare shield heater type";
CM_ SG_ 2047 GTW_rearLightHardwareVariant "Gateway: rear light hardware variant";
CM_ SG_ 2047 GTW_fasciaHarnessCleanPointType "Gateway: fascia harness clean point type";
CM_ SG_ 2047 GTW_epasSubType "Gateway: epas sub type";
CM_ SG_ 2047 GTW_wiperSupplyChainOrigin "Gateway: wiper supply chain origin; raw 0 = signal not available (SNA)";
CM_ SG_ 2047 GTW_windowPinchParameterType "Gateway: window pinch parameter type";
CM_ SG_ 2047 GTW_badgingMaterialType "Gateway: badging material type";
CM_ SG_ 2047 GTW_mRecordVersion "Gateway: m record version";
CM_ SG_ 2047 GTW_tcuType "Gateway: tcu type";
CM_ SG_ 2047 GTW_carbComplianceBehaviorType "Gateway: carb compliance behavior type";
CM_ SG_ 2047 GTW_indirectTPMSCalibrationType "Indirect TPMS calibration type.";
CM_ SG_ 2047 GTW_v2xEnabled "Gateway: v2x enabled";
CM_ SG_ 2047 GTW_liftgateStrutType "Gateway: liftgate strut type";
CM_ SG_ 2047 GTW_exteriorMicrophoneType "Gateway: exterior microphone type";
CM_ SG_ 2047 GTW_contactorPowerSource "Gateway: contactor power source";
CM_ SG_ 2047 GTW_roofGlassType "Gateway: roof glass type";
CM_ SG_ 2047 GTW_pedalMapNameOverride "Gateway: pedal map name override";
CM_ BO_ 792 "Gateway message: car state";
CM_ SG_ 792 GTW_factoryGated "Gateway: factory gated";
CM_ BO_ 1638 "Gateway message: diag session";
CM_ SG_ 1638 GTW_diagRemainingSeconds "Seconds remaining for the diagnostics session";
CM_ SG_ 1638 GTW_diagSessionActive "UDS Session Active";
CM_ SG_ 1638 GTW_diagLevel "Current diagnostics level";
CM_ SG_ 1638 GTW_diagUnlockProcedureActive "GTW diag unlock procedure active";
CM_ SG_ 1638 GTW_diagOverrideActive "GTW diag level override active";
CM_ SG_ 1638 GTW_diagPhysicalLinkEstablished "Physical diag cable connected to the switch and link established";
CM_ BO_ 1080 "Gateway message: eth nm";
CM_ SG_ 1080 GTW_ethGotoSleep "ETH bus sleep commanded";
CM_ SG_ 1080 GTW_ethWakeUpBus "Gateway: eth wake up bus";
CM_ SG_ 1080 GTW_vehBusAsleep "VEH bus sleep state";
CM_ SG_ 1080 GTW_ethHeartBeatCounter "Gateway: eth heart beat counter";
CM_ SG_ 1080 GTW_ethWakeUpReason "Tracks the cause of why the gateway wakes up the ethernet bus";
CM_ BO_ 1376 "Gateway message: factory ecu present";
CM_ SG_ 1376 GTW_OCS1Ppresent "Gateway: OCS1 ppresent";
CM_ SG_ 1376 GTW_PCSpresent "Gateway: PC spresent";
CM_ SG_ 1376 GTW_HVPpresent "Gateway: HV ppresent";
CM_ SG_ 1376 GTW_BMSpresent "Gateway: BM spresent";
CM_ SG_ 1376 GTW_CPpresent "Gateway: c ppresent";
CM_ SG_ 1376 GTW_RCMpresent "Gateway: RC mpresent";
CM_ SG_ 1376 GTW_SCCMpresent "Gateway: SCC mpresent";
CM_ SG_ 1376 GTW_VCSECpresent "Gateway: VCSE cpresent";
CM_ SG_ 1376 GTW_EPAS3Ppresent "Gateway: EPAS3 ppresent";
CM_ SG_ 1376 GTW_EPBLpresent "Gateway: EPB lpresent";
CM_ SG_ 1376 GTW_EPBRpresent "Gateway: EPB rpresent";
CM_ SG_ 1376 GTW_ESPpresent "Gateway: ES ppresent";
CM_ SG_ 1376 GTW_IBSTpresent "Gateway: IBS tpresent";
CM_ SG_ 1376 GTW_PARKpresent "Gateway: PAR kpresent";
CM_ SG_ 1376 GTW_RADCpresent "Gateway: RAD cpresent";
CM_ SG_ 1376 GTW_TPMSpresent "Gateway: TPM spresent";
CM_ SG_ 1376 GTW_VCFRONTpresent "Gateway: VCFRON tpresent";
CM_ SG_ 1376 GTW_VCLEFTpresent "Gateway: VCLEF tpresent";
CM_ SG_ 1376 GTW_VCRIGHTpresent "Gateway: VCRIGH tpresent";
CM_ SG_ 1376 GTW_EPAS3Spresent "Gateway: EPAS3 spresent";
CM_ SG_ 1376 GTW_CMPpresent "Gateway: CM ppresent";
CM_ SG_ 1376 GTW_DASpresent "Gateway: DA spresent";
CM_ SG_ 1376 GTW_PTCpresent "Gateway: PT cpresent";
CM_ SG_ 1376 GTW_SWCpresent "Gateway: SW cpresent";
CM_ SG_ 1376 GTW_PMRpresent "Gateway: PM rpresent";
CM_ SG_ 1376 GTW_PMFpresent "Gateway: PM fpresent";
CM_ SG_ 1376 GTW_DIRpresent "Gateway: DI rpresent";
CM_ SG_ 1376 GTW_DIFpresent "Gateway: DI fpresent";
CM_ BO_ 1656 "Gateway message: gear control";
CM_ SG_ 1656 GTW_gearControlChecksum "Gateway: gear control checksum";
CM_ SG_ 1656 GTW_gearControlCounter "Gateway: gear control counter";
CM_ SG_ 1656 GTW_gearShiftRequest "Request to change gear state from center display UI control; raw 0 = signal not available (SNA)";
CM_ SG_ 1656 GTW_osdActive "Whether OSD is active";
CM_ SG_ 1656 GTW_primaryGearControlStatus "Status of the center display UI control";
CM_ SG_ 1656 GTW_gearStripEnable "UI control for showing and or activating the primary gear strip interface";
CM_ SG_ 1656 GTW_showNeutralButton "Tell UI that it is time to animate the N button to be shown";
CM_ SG_ 1656 GTW_showAutoParkButton "Tell UI that it is time to animate the autopark button to be shown";
CM_ SG_ 1656 GTW_autoParkRequest "Request to auto park from center display UI control";
CM_ SG_ 1656 GTW_smartShiftStatus "Based on the status of the infotainment system smart shift feature should be disabled; raw 0 = signal not available (SNA)";
CM_ SG_ 1656 GTW_processingRDgestures "Is GTW processing R and D swipe gestures";
CM_ SG_ 1656 GTW_processingTapPgestures "Is GTW processing contextual tap-to-park gestures";
CM_ SG_ 1656 GTW_gearStripChangeReason "Gateway: gear strip change reason; raw 0 = signal not available (SNA)";
CM_ SG_ 1656 GTW_touchActive "User present as touch on display is active";
CM_ SG_ 1656 GTW_steamOff "Let UI know to turn Steam off";
CM_ SG_ 1656 GTW_screenPCBTemperature "Reading from display i2c temperature sensor; raw 2047 = signal not available (SNA)";
CM_ BO_ 2033 "Gateway message: hrl";
CM_ SG_ 2033 GTW_hrlIndex "Gateway: hrl index";
CM_ SG_ 2033 GTW_hrlPagesCount "Gateway: hrl pages count";
CM_ SG_ 2033 GTW_hrlSdCardSizeGB "Gateway: hrl sd card size GB; raw 0 = signal not available (SNA)";
CM_ SG_ 2033 GTW_hrlState "GTW hrl state";
CM_ SG_ 2033 GTW_hrlTriggerDuration "HRL duration";
CM_ SG_ 2033 GTW_hrlTriggerType "HRL trigger type";
CM_ SG_ 2033 GTW_hrlTriggerId "HRL trigger ID. A unique ID representing the signal conditions causing the HRL event to occur.";
CM_ SG_ 2033 GTW_hrlTriggerBus "Gateway: hrl trigger bus";
CM_ BO_ 2026 "Gateway message: hrl external event";
CM_ SG_ 2026 GTW_hrlEventStartEpoch "Gateway: hrl event start epoch";
CM_ SG_ 2026 GTW_hrlEventEndEpoch "Gateway: hrl event end epoch";
CM_ BO_ 60 "Gateway message: info";
CM_ SG_ 60 GTW_infoIndex "Gateway: info index";
CM_ SG_ 60 GTW_buildType "Gateway: build type";
CM_ SG_ 60 GTW_hardwareId "GTW hardware ID";
CM_ SG_ 60 GTW_platformType "Gateway: platform type";
CM_ SG_ 60 GTW_appCrc "Gateway: app crc";
CM_ SG_ 60 GTW_applicationGitHash "Gateway: application git hash";
CM_ SG_ 60 GTW_bootGitHash "Gateway: boot git hash";
CM_ BO_ 1370 "Gateway message: mismatch fault";
CM_ SG_ 1370 GTW_mismatchFaultIndex "Gateway: mismatch fault index";
CM_ SG_ 1370 GTW_mismatchFaultChecksum "Gateway: mismatch fault checksum";
CM_ SG_ 1370 GTW_mismatchFaultCounter "Gateway: mismatch fault counter";
CM_ SG_ 1370 GTW_GTWmismatchFault "Reports the Gateway (GTW) running a firmware version that does not match the rest of the vehicle";
CM_ SG_ 1370 GTW_BMSmismatchFault "Reports the high voltage Battery Management System (BMS) electronic control unit (ECU) running a firmware version that does not match the rest of the vehicle";
CM_ SG_ 1370 GTW_APSmismatchFault "Reports the Autopilot Processor Secondary (APS) electronic control unit (ECU) running a firmware version that does not match the rest of the vehicle";
CM_ SG_ 1370 GTW_BLEEPCENTERmismatchFault "Reports the Bluetooth Low Energy End Point Center (BLEEPCENTER) electronic control unit (ECU) running a firmware version that does not match the rest of the vehicle";
CM_ SG_ 1370 GTW_BLEEPLEFTmismatchFault "Reports the Bluetooth Low Energy End Point Left (BLEEPLEFT) electronic control unit (ECU) running a firmware version that does not match the rest of the vehicle";
CM_ SG_ 1370 GTW_BLEEPREARmismatchFault "Reports the Bluetooth Low Energy End Point Rear (BLEEPREAR) electronic control unit (ECU) running a firmware version that does not match the rest of the vehicle";
CM_ SG_ 1370 GTW_BLEEPRIGHTmismatchFault "Reports the Bluetooth Low Energy End Point Right (BLEEPRIGHT) electronic control unit (ECU) running a firmware version that does not match the rest of the vehicle";
CM_ SG_ 1370 GTW_CBCmismatchFault "Reports the Cabin Blower Controller (CBC) electronic control unit (ECU) running a firmware version that does not match the rest of the vehicle";
CM_ SG_ 1370 GTW_CMPmismatchFault "Reports the air conditioning compressor (CMP) electronic control unit (ECU) running a firmware version that does not match the rest of the vehicle";
CM_ SG_ 1370 GTW_CPmismatchFault "Reports the Charge Port (CP) electronic control unit (ECU) running a firmware version that does not match the rest of the vehicle";
CM_ SG_ 1370 GTW_DIFmismatchFault "Reports the front drive inverter (DIF) electronic control unit (ECU) running a firmware version that does not match the rest of the vehicle";
CM_ SG_ 1370 GTW_DIRmismatchFault "Reports the rear drive inverter (DIR) electronic control unit (ECU) running a firmware version that does not match the rest of the vehicle";
CM_ SG_ 1370 GTW_EPAS3PmismatchFault "Reports the primary Electronic Power Assisted Steering (EPAS3P) electronic control unit (ECU) running a firmware version that does not match the rest of the vehicle";
CM_ SG_ 1370 GTW_EPAS3SmismatchFault "Reports the secondary Electronic Power Assisted Steering (EPAS3S) electronic control unit (ECU) running a firmware version that does not match the rest of the vehicle";
CM_ SG_ 1370 GTW_EPBLmismatchFault "Reports the left Electronic Park Brake (EPBL) electronic control unit (ECU) running a firmware version that does not match the rest of the vehicle";
CM_ SG_ 1370 GTW_EPBRmismatchFault "Reports the right Electronic Park Brake (EPBR) electronic control unit (ECU) running a firmware version that does not match the rest of the vehicle";
CM_ SG_ 1370 GTW_ESPCALmismatchFault "Reports the Electronic Stability Program Calibration (ESPCAL) electronic control unit (ECU) running a firmware version that does not match the rest of the vehicle";
CM_ SG_ 1370 GTW_ESPmismatchFault "Reports the Electronic Stability Program (ESP) electronic control unit (ECU) running a firmware version that does not match the rest of the vehicle";
CM_ SG_ 1370 GTW_HCM3LmismatchFault "Reports the left LED matrix Headlamp Control Module (HCM3L) electronic control unit (ECU) running a firmware version that does not match the rest of the vehicle";
CM_ SG_ 1370 GTW_HCM3RmismatchFault "Reports the right LED matrix Headlamp Control Module (HCM3R) electronic control unit (ECU) running a firmware version that does not match the rest of the vehicle";
CM_ SG_ 1370 GTW_HCMLmismatchFault "Reports the left Headlamp Control Module (HCML) electronic control unit (ECU) running a firmware version that does not match the rest of the vehicle";
CM_ SG_ 1370 GTW_HCMRmismatchFault "Reports the right Headlamp Control Module (HCMR) electronic control unit (ECU) running a firmware version that does not match the rest of the vehicle";
CM_ SG_ 1370 GTW_HVPmismatchFault "Reports the High Voltage Processor (HVP) electronic control unit (ECU) running a firmware version that does not match the rest of the vehicle";
CM_ SG_ 1370 GTW_IBSTCALmismatchFault "Reports the electromechanical brake booster calibration, or iBooster Calibration (IBSTCAL), electronic control unit (ECU) running a firmware version that does not match the rest of the vehicle";
CM_ SG_ 1370 GTW_IBSTmismatchFault "Reports the electromechanical brake booster, or iBooster (IBST), electronic control unit (ECU) running a firmware version that does not match the rest of the vehicle";
CM_ SG_ 1370 GTW_LVBMSmismatchFault "Reports the Low Voltage Battery Management System (LVBMS) electronic control unit (ECU) running a firmware version that does not match the rest of the vehicle";
CM_ SG_ 1370 GTW_OCS1PmismatchFault "Reports the Occupancy Classification System - 1st Row Passenger (OCS1P) electronic control unit (ECU) running a firmware version that does not match the rest of the vehicle";
CM_ SG_ 1370 GTW_OPCFmismatchFault "Reports the front Oil Pump Controller (OPCF) electronic control unit (ECU) running a firmware version that does not match the rest of the vehicle";
CM_ SG_ 1370 GTW_OPCRmismatchFault "Reports the rear Oil Pump Controller (OPCR) electronic control unit (ECU) running a firmware version that does not match the rest of the vehicle";
CM_ SG_ 1370 GTW_PARKmismatchFault "Reports the Park Assist (PARK) electronic control unit (ECU) running a firmware version that does not match the rest of the vehicle";
CM_ SG_ 1370 GTW_PCSCPU2mismatchFault "Reports the Power Conversion System AC charging core (PCSCPU2) electronic control unit (ECU) running a firmware version that does not match the rest of the vehicle";
CM_ SG_ 1370 GTW_PCSmismatchFault "Reports the Power Conversion System (PCS) electronic control unit (ECU) running a firmware version that does not match the rest of the vehicle";
CM_ SG_ 1370 GTW_PMFmismatchFault "Reports the front Pedal Monitor (PMF) electronic control unit (ECU) running a firmware version that does not match the rest of the vehicle";
CM_ SG_ 1370 GTW_PMRmismatchFault "Reports the rear Pedal Monitor (PMR) electronic control unit (ECU) running a firmware version that does not match the rest of the vehicle";
CM_ SG_ 1370 GTW_PTCmismatchFault "Reports the Positive Temperature Coefficient (PTC) heater electronic control unit (ECU) running a firmware version that does not match the rest of the vehicle";
CM_ SG_ 1370 GTW_RCMCALmismatchFault "Reports the Restraint Control Module Calibration (RCMCAL) electronic control unit (ECU) running a firmware version that does not match the rest of the vehicle";
CM_ SG_ 1370 GTW_RCMmismatchFault "Reports the Restraint Control Module (RCM) electronic control unit (ECU) running a firmware version that does not match the rest of the vehicle";
CM_ SG_ 1370 GTW_SCCMmismatchFault "Reports the Steering Column Control Module (SCCM) electronic control unit (ECU) running a firmware version that does not match the rest of the vehicle";
CM_ SG_ 1370 GTW_SDCRmismatchFault "Reports the Secondary Disconnect Controller (SDCR) electronic control unit (ECU) running a firmware version that does not match the rest of the vehicle";
CM_ SG_ 1370 GTW_SWCmismatchFault "Reports the Steering Wheel Controller (SWC) electronic control unit (ECU) running a firmware version that does not match the rest of the vehicle";
CM_ SG_ 1370 GTW_THSmismatchFault "Reports the Temperature Humidity Sensor (THS) electronic control unit (ECU) running a firmware version that does not match the rest of the vehicle";
CM_ SG_ 1370 GTW_VCFRONTmismatchFault "Reports the front vehicle controller (VCFRONT) electronic control unit (ECU) running a firmware version that does not match the rest of the vehicle";
CM_ SG_ 1370 GTW_VCLEFTmismatchFault "Reports the left vehicle controller (VCLEFT) electronic control unit (ECU) running a firmware version that does not match the rest of the vehicle";
CM_ SG_ 1370 GTW_VCRIGHTmismatchFault "Reports the right vehicle controller (VCRIGHT) electronic control unit (ECU) running a firmware version that does not match the rest of the vehicle";
CM_ SG_ 1370 GTW_VCSECmismatchFault "Reports the vehicle security controller (VCSEC) electronic control unit (ECU) running a firmware version that does not match the rest of the vehicle";
CM_ SG_ 1370 GTW_PMmismatchFault "Reports the Pedal Monitor (PM) electronic control unit (ECU) running a firmware version that does not match the rest of the vehicle";
CM_ BO_ 840 "Gateway message: status";
CM_ SG_ 840 GTW_vehicleVersionMatchStatus "Signal to indicate if the vehicle ECUs are all on a matched production version";
CM_ SG_ 840 GTW_hwtype "Describes the chip GTW is running on; raw 0 = signal not available (SNA)";
CM_ SG_ 840 GTW_jcanProductName "Describes the JCAN reference (product) name; raw 0 = signal not available (SNA)";
CM_ SG_ 840 GTW_uptimeSeconds "GTW uptime in seconds";
CM_ SG_ 840 GTW_boardRevision "Board revision ID of the MCU PCBA";
CM_ SG_ 840 GTW_touchcoreOsType "Gateway: touchcore os type";
CM_ SG_ 840 GTW_sentryModeState "Sentry Mode state; raw 6 = signal not available (SNA)";
CM_ SG_ 840 GTW_secureBootEnabled "Gateway: secure boot enabled";
CM_ SG_ 840 GTW_socSleepType "Describes the sleep type GTW is expecting from the SoC; raw 0 = signal not available (SNA)";
CM_ SG_ 840 GTW_resetType "Describes the type of reset GTW experienced; raw 0 = signal not available (SNA)";
CM_ BO_ 1005 "Gateway message: update status";
CM_ SG_ 1005 GTW_i2cUpdateActive "Gateway: i2c update active";
CM_ SG_ 1005 GTW_peripheralConfirmedUpdateNee "Detects if peripheral has confirmed update is needed";
CM_ SG_ 1005 GTW_ocuFailed "Reports the offboard charger update was unsuccessful.";
CM_ SG_ 1005 GTW_ecuUpdateStarted "Reports whether Electronic Control Unit (ECU) update phase is active.";
CM_ SG_ 1005 GTW_updateStarted "Main update in progress bit";
CM_ BO_ 1112 "Gateway message: veh nm";
CM_ SG_ 1112 GTW_nmGoingToSleep "Network management - Going to sleep state";
CM_ SG_ 1112 GTW_nmWakeUpBus "Gateway: nm wake up bus";
CM_ SG_ 1112 GTW_chBusAsleep "Chassis bus sleep state";
CM_ SG_ 1112 GTW_ethBusAsleep "ETH bus sleep state";
CM_ SG_ 1112 GTW_nmKeepAwakeReason "Network management - Keep awake reason; raw 0 = signal not available (SNA)";
CM_ SG_ 1112 GTW_nmWakeUpReason "Network management - Wakeup reason";
CM_ SG_ 1112 GTW_ethKeepAwakeReason "Reason GTW is keeping ETH bus awake; raw 0 = signal not available (SNA)";
CM_ SG_ 1112 GTW_nmDebugWakeUp "Gateway: nm debug wake up";
CM_ SG_ 1112 GTW_OTAKeepAwake "Signals that the vehicle buses should remain awake for an ongoing OTA update";
CM_ SG_ 1112 GTW_smsPokeReceived "The modem indicated it received an SMS poke";
CM_ SG_ 1112 GTW_bdyBusAsleep "BDY bus sleep state";
CM_ BO_ 1429 "Occupant classification system message: alert log";
CM_ SG_ 1429 OCS1P_alertID "Occupant classification system: alert ID";
CM_ SG_ 1429 OCS1P_alertState "Occupant classification system: alert state";
CM_ SG_ 1429 OCS1P_a121_sandwichFreq "Occupant classification system: a121 sandwich freq";
CM_ SG_ 1429 OCS1P_a122_sandwichFreq "Occupant classification system: a122 sandwich freq";
CM_ SG_ 1429 OCS1P_a123_sandwichFreq "Occupant classification system: a123 sandwich freq";
CM_ SG_ 1429 OCS1P_a124_cushionSelfFreq "Occupant classification system: a124 cushion self freq";
CM_ SG_ 1429 OCS1P_a125_cushionSelfFreq "Occupant classification system: a125 cushion self freq";
CM_ SG_ 1429 OCS1P_a126_cushionSelfFreq "Occupant classification system: a126 cushion self freq";
CM_ SG_ 1429 OCS1P_a127_seatbackSelfFreq "Occupant classification system: a127 seatback self freq";
CM_ SG_ 1429 OCS1P_a128_seatbackSelfFreq "Occupant classification system: a128 seatback self freq";
CM_ SG_ 1429 OCS1P_a129_seatbackSelfFreq "Occupant classification system: a129 seatback self freq";
CM_ SG_ 1429 OCS1P_a130_sandwichNoCalib "Occupant classification system: a130 sandwich no calib";
CM_ SG_ 1429 OCS1P_a131_cushionSelfNoCalib "Occupant classification system: a131 cushion self no calib";
CM_ SG_ 1429 OCS1P_a132_seatbackSelfNoCalib "Occupant classification system: a132 seatback self no calib";
CM_ SG_ 1429 OCS1P_a133_sandwichBadCalib "Occupant classification system: a133 sandwich bad calib";
CM_ SG_ 1429 OCS1P_a134_uninitializedCalib "Occupant classification system: a134 uninitialized calib";
CM_ SG_ 1429 OCS1P_a135_tempNoCalib "Occupant classification system: a135 temp no calib";
CM_ SG_ 1429 OCS1P_a140_tempInvalidCalib "Occupant classification system: a140 temp invalid calib";
CM_ SG_ 1429 OCS1P_a141_humidityInvalidCalib "Occupant classification system: a141 humidity invalid calib";
CM_ SG_ 1429 OCS1P_a142_tempHumidityInvalid "Occupant classification system: a142 temp humidity invalid";
CM_ SG_ 1429 OCS1P_a143_mismatchPassAirbag "Occupant classification system: a143 mismatch pass airbag";
CM_ SG_ 1429 OCS1P_a144_mismatchCarRegion "Occupant classification system: a144 mismatch car region";
CM_ BO_ 767 "Occupant classification system message: alert matrix";
CM_ SG_ 767 OCS1P_matrixIndex "Occupant classification system: matrix index";
CM_ SG_ 767 OCS1P_w015_NVMMAlert "Occupant classification system: w015 NVMM alert";
CM_ SG_ 767 OCS1P_w121_sandwichOpen "Occupant classification system: w121 sandwich open";
CM_ SG_ 767 OCS1P_w122_sandwichLow "Occupant classification system: w122 sandwich low";
CM_ SG_ 767 OCS1P_w123_sandwichShort "Occupant classification system: w123 sandwich short";
CM_ SG_ 767 OCS1P_w124_cushionSelfOpen "Occupant classification system: w124 cushion self open";
CM_ SG_ 767 OCS1P_w125_cushionSelfLow "Occupant classification system: w125 cushion self low";
CM_ SG_ 767 OCS1P_w126_cushionSelfShort "Occupant classification system: w126 cushion self short";
CM_ SG_ 767 OCS1P_w127_seatbackSelfOpen "Occupant classification system: w127 seatback self open";
CM_ SG_ 767 OCS1P_w128_seatbackSelfLow "Occupant classification system: w128 seatback self low";
CM_ SG_ 767 OCS1P_w129_seatbackSelfShort "Occupant classification system: w129 seatback self short";
CM_ SG_ 767 OCS1P_w130_sandwichNoCalib "Occupant classification system: w130 sandwich no calib";
CM_ SG_ 767 OCS1P_w131_cushionSelfNoCalib "Occupant classification system: w131 cushion self no calib";
CM_ SG_ 767 OCS1P_w132_seatbackSelfNoCalib "Occupant classification system: w132 seatback self no calib";
CM_ SG_ 767 OCS1P_w133_sandwichBadCalib "Occupant classification system: w133 sandwich bad calib";
CM_ SG_ 767 OCS1P_w134_uninitializedCalib "Occupant classification system: w134 uninitialized calib";
CM_ SG_ 767 OCS1P_w135_tempNoCalib "Occupant classification system: w135 temp no calib";
CM_ SG_ 767 OCS1P_w136_cushionSelfDutyLow "Occupant classification system: w136 cushion self duty low";
CM_ SG_ 767 OCS1P_w137_cushionSelfDutyHigh "Occupant classification system: w137 cushion self duty high";
CM_ SG_ 767 OCS1P_w138_seatbackSelfDutyLow "Occupant classification system: w138 seatback self duty low";
CM_ SG_ 767 OCS1P_w139_seatbackSelfDutyHigh "Occupant classification system: w139 seatback self duty high";
CM_ SG_ 767 OCS1P_w140_tempInvalidCalib "Occupant classification system: w140 temp invalid calib";
CM_ SG_ 767 OCS1P_w141_humidityInvalidCalib "Occupant classification system: w141 humidity invalid calib";
CM_ SG_ 767 OCS1P_w142_tempHumidityInvalid "Occupant classification system: w142 temp humidity invalid";
CM_ SG_ 767 OCS1P_w143_mismatchPassAirbag "Occupant classification system: w143 mismatch pass airbag";
CM_ SG_ 767 OCS1P_w144_mismatchCarRegion "Occupant classification system: w144 mismatch car region";
CM_ SG_ 767 OCS1P_w145_rebaselineTriggered "Occupant classification system: w145 rebaseline triggered";
CM_ SG_ 767 OCS1P_w148_classificationMismatc "Occupant classification system: w148 classification mismatch";
CM_ SG_ 767 OCS1P_w150_rbEntryTriggered "Occupant classification system: w150 rb entry triggered";
CM_ SG_ 767 OCS1P_w151_rbEntryExited "Occupant classification system: w151 rb entry exited";
CM_ SG_ 767 OCS1P_w152_rbExit1Triggered "Occupant classification system: w152 rb exit1 triggered";
CM_ SG_ 767 OCS1P_w153_rbExit1Exited "Occupant classification system: w153 rb exit1 exited";
CM_ SG_ 767 OCS1P_w154_rbExit2Exited1 "Occupant classification system: w154 rb exit2 exited1";
CM_ SG_ 767 OCS1P_w155_rbExit2Exited2 "Occupant classification system: w155 rb exit2 exited2";
CM_ SG_ 767 OCS1P_w156_seatbeltReminderUnava "Occupant classification system: w156 seatbelt reminder unavailable";
CM_ BO_ 766 "Occupant classification system message: info";
CM_ SG_ 766 OCS1P_infoIndex "Occupant classification system: info index";
CM_ SG_ 766 OCS1P_infoBuildType "Occupant classification system: info build type";
CM_ SG_ 766 OCS1P_infoBuildConfigID "Occupant classification system: info build config ID";
CM_ SG_ 766 OCS1P_infoHardwareID "Occupant classification system: info hardware ID";
CM_ SG_ 766 OCS1P_infoComponentID "Occupant classification system: info component ID";
CM_ SG_ 766 OCS1P_infoPcbaID "Occupant classification system: info pcba ID";
CM_ SG_ 766 OCS1P_infoAssemblyID "Occupant classification system: info assembly ID";
CM_ SG_ 766 OCS1P_infoUsageID "Occupant classification system: info usage ID";
CM_ SG_ 766 OCS1P_infoSubUsageID "Occupant classification system: info sub usage ID";
CM_ SG_ 766 OCS1P_infoApplicationCRC "Occupant classification system: info application CRC";
CM_ SG_ 766 OCS1P_infoBootSvnRev "Occupant classification system: info boot svn rev";
CM_ SG_ 766 OCS1P_infoAppGitHashBytes "Occupant classification system: info app git hash bytes";
CM_ SG_ 766 OCS1P_infoBootGitHashBytes "Occupant classification system: info boot git hash bytes";
CM_ SG_ 766 OCS1P_infoPlatformType "Occupant classification system: info platform type";
CM_ SG_ 766 OCS1P_infoBootUdsProtoVersion "Occupant classification system: info boot uds proto version";
CM_ SG_ 766 OCS1P_infoBootloaderCRC "Occupant classification system: info bootloader CRC";
CM_ BO_ 771 "Occupant classification system message: status";
CM_ SG_ 771 OCS1P_occupantClassification "Occupant Classification (Filtered); raw 255 = signal not available (SNA)";
CM_ SG_ 771 OCS1P_occupantClassificationQF "Occupant classification system: occupant classification QF";
CM_ SG_ 771 OCS1P_occupiedState "Passenger seat occupied State; raw 3 = signal not available (SNA)";
CM_ SG_ 771 OCS1P_triggerSnapshot "Occupant classification system: trigger snapshot";
CM_ SG_ 771 OCS1P_occupantClassificationRaw "Occupant classification system: occupant classification raw; raw 7 = signal not available (SNA)";
CM_ SG_ 771 OCS1P_occupantClassificationSelf "Occupant classification system: occupant classification self; raw 7 = signal not available (SNA)";
CM_ SG_ 771 OCS1P_occupantClassificationRawC "Occupant classification system: occupant classification raw cap; raw 7 = signal not available (SNA)";
CM_ SG_ 771 OCS1P_occupantClassificationCap "Occupant classification system: occupant classification cap; raw 7 = signal not available (SNA)";
CM_ SG_ 771 OCS1P_classificationHeld "Whether occupant classification is filtered due to door state or stability based on frequency";
CM_ SG_ 771 OCS1P_cushionStable "Whether frequency reading is unchanging of Cushion Self sensor";
CM_ SG_ 771 OCS1P_classificationExtHold "Occupant classification request to be filtered due to door state";
CM_ SG_ 771 OCS1P_classificationHoldState "Occupant classification system: classification hold state";
CM_ SG_ 771 OCS1P_classificationVariant "The combination of sensors used to classify occupant";
CM_ SG_ 771 OCS1P_sandwichDisabled "Cushion mutual sensor disabled by calibration";
CM_ SG_ 771 OCS1P_noSandwichType "Configuration set in factory or service that determines logic around uninstalled sandwich";
CM_ SG_ 771 OCS1P_sandwichBoundaryType "Occupant classification system: sandwich boundary type";
CM_ SG_ 771 OCS1P_sbrBoundaryType "Occupant classification system: sbr boundary type";
CM_ SG_ 771 OCS1P_occupiedStateCap "Occupant classification system: occupied state cap; raw 3 = signal not available (SNA)";
CM_ SG_ 771 OCS1P_seatbackStable "Whether frequency reading is unchanging of Seatback Self sensor";
CM_ SG_ 771 OCS1P_sandwichStable "Whether frequency reading is unchanging of Cushion Mutual sensor";
CM_ SG_ 771 OCS1P_cushionStableCap "Occupant classification system: cushion stable cap";
CM_ SG_ 771 OCS1P_seatbackStableCap "Occupant classification system: seatback stable cap";
CM_ SG_ 771 OCS1P_classificationHeldCap "Occupant classification system: classification held cap";
CM_ SG_ 771 OCS1P_statusCounter "Occupant classification system: status counter";
CM_ SG_ 771 OCS1P_statusChecksum "Occupant classification system: status checksum";
CM_ BO_ 1619 "Occupant classification system message: uds response";
CM_ SG_ 1619 OCS1P_udsResponseData "Occupant classification system: uds response data";
CM_ BO_ 519 "Cabin heater message: feedback status";
CM_ SG_ 519 PTC_leftFlagFault "Heater left bank fault indication flag";
CM_ SG_ 519 PTC_rightFlagFault "Heater right bank fault indication flag";
CM_ SG_ 519 PTC_leftPowerDerating "Heater left bank power derating state";
CM_ SG_ 519 PTC_rightPowerDerating "Heater right bank power derating state";
CM_ SG_ 519 PTC_ocpEvent "Indication that an over current protection event has occurred";
CM_ SG_ 519 PTC_leftDutyFeedback "Current PWM duty cycle applied to left side of PTC heater";
CM_ SG_ 519 PTC_rightDutyFeedback "Current PWM duty cycle applied to right side of PTC heater";
CM_ SG_ 519 PTC_leftPowerHV "Heater left bank power";
CM_ SG_ 519 PTC_rightPowerHV "Heater right bank power";
CM_ SG_ 519 PTC_leftTempEstOutlet "Cabin heater: left temp est outlet";
CM_ SG_ 519 PTC_rightTempEstOutlet "Cabin heater: right temp est outlet";
CM_ SG_ 519 PTC_tliErrorCount "Heater top level interrupt error count";
CM_ SG_ 519 PTC_tliEvent "Indicator of heater top level interrupt event";
CM_ SG_ 519 PTC_tliSource "Heater top level interrupt event source";
CM_ BO_ 1297 "Restraint control module message: alert log";
CM_ SG_ 1297 RCM_alertID "Restraint control module: alert ID";
CM_ SG_ 1297 RCM_alertState "Restraint control module: alert state";
CM_ SG_ 1297 RCM_a000_eventArmStatus "Restraint control module: a000 event arm status";
CM_ SG_ 1297 RCM_a000_eventFactoryMode "Restraint control module: a000 event factory mode";
CM_ SG_ 1297 RCM_a000_eventDiagEnabled "Restraint control module: a000 event diag enabled";
CM_ SG_ 1297 RCM_a000_eventDriveOrientation "Restraint control module: a000 event drive orientation";
CM_ SG_ 1297 RCM_a000_crashDetectedFront "Restraint control module: a000 crash detected front";
CM_ SG_ 1297 RCM_a000_crashDetectedRear "Restraint control module: a000 crash detected rear";
CM_ SG_ 1297 RCM_a000_crashDetectedLeft "Restraint control module: a000 crash detected left";
CM_ SG_ 1297 RCM_a000_crashDetectedRight "Restraint control module: a000 crash detected right";
CM_ SG_ 1297 RCM_a000_crashDetectedRoll "Restraint control module: a000 crash detected roll";
CM_ SG_ 1297 RCM_a000_crashDetectedPreten "Restraint control module: a000 crash detected preten";
CM_ SG_ 1297 RCM_a000_crashDetectedStage1 "Restraint control module: a000 crash detected stage1";
CM_ SG_ 1297 RCM_a000_crashDetectedStage2 "Restraint control module: a000 crash detected stage2";
CM_ SG_ 1297 RCM_a000_crashDetectedHVpyro "Restraint control module: a000 crash detected h vpyro";
CM_ SG_ 1297 RCM_a000_eventIDFsignal "Restraint control module: a000 event ID fsignal";
CM_ SG_ 1297 RCM_a000_eventFrontLeftSeatbelt "Restraint control module: a000 event front left seatbelt";
CM_ SG_ 1297 RCM_a000_eventFrontRightSeatbelt "Restraint control module: a000 event front right seatbelt";
CM_ SG_ 1297 RCM_a000_eventVehicleSpeed "Restraint control module: a000 event vehicle speed";
CM_ SG_ 1297 RCM_a000_eventSteeringAngle "Restraint control module: a000 event steering angle";
CM_ SG_ 1297 RCM_a000_eventDriverBrakeApply "Restraint control module: a000 event driver brake apply";
CM_ SG_ 1297 RCM_a000_eventAccelPedalPos "Restraint control module: a000 event accel pedal pos";
CM_ SG_ 1297 RCM_a001_eventArmStatus "Restraint control module: a001 event arm status";
CM_ SG_ 1297 RCM_a001_eventFactoryMode "Restraint control module: a001 event factory mode";
CM_ SG_ 1297 RCM_a001_eventDiagEnabled "Restraint control module: a001 event diag enabled";
CM_ SG_ 1297 RCM_a001_eventDriveOrientation "Restraint control module: a001 event drive orientation";
CM_ SG_ 1297 RCM_a001_nearDeployFront "Restraint control module: a001 near deploy front";
CM_ SG_ 1297 RCM_a001_nearDeployRear "Restraint control module: a001 near deploy rear";
CM_ SG_ 1297 RCM_a001_nearDeployLeft "Restraint control module: a001 near deploy left";
CM_ SG_ 1297 RCM_a001_nearDeployRight "Restraint control module: a001 near deploy right";
CM_ SG_ 1297 RCM_a001_nearDeployRoll "Restraint control module: a001 near deploy roll";
CM_ SG_ 1297 RCM_a001_nearDeployPretensioner "Restraint control module: a001 near deploy pretensioner";
CM_ SG_ 1297 RCM_a001_eventIDFsignal "Restraint control module: a001 event ID fsignal";
CM_ SG_ 1297 RCM_a001_eventFrontLeftSeatbelt "Restraint control module: a001 event front left seatbelt";
CM_ SG_ 1297 RCM_a001_eventFrontRightSeatbelt "Restraint control module: a001 event front right seatbelt";
CM_ SG_ 1297 RCM_a001_eventVehicleSpeed "Restraint control module: a001 event vehicle speed";
CM_ SG_ 1297 RCM_a001_eventSteeringAngle "Restraint control module: a001 event steering angle";
CM_ SG_ 1297 RCM_a001_eventDriverBrakeApply "Restraint control module: a001 event driver brake apply; raw 3 = signal not available (SNA)";
CM_ SG_ 1297 RCM_a001_eventAccelPedalPos "Restraint control module: a001 event accel pedal pos; raw 255 = signal not available (SNA)";
CM_ SG_ 1297 RCM_a002_eventArmStatus "Restraint control module: a002 event arm status";
CM_ SG_ 1297 RCM_a002_eventFactoryMode "Restraint control module: a002 event factory mode";
CM_ SG_ 1297 RCM_a002_eventDiagEnabled "Restraint control module: a002 event diag enabled";
CM_ SG_ 1297 RCM_a002_eventDriveOrientation "Restraint control module: a002 event drive orientation";
CM_ SG_ 1297 RCM_a002_airbagsUnArmed "Restraint control module: a002 airbags un armed";
CM_ SG_ 1297 RCM_a002_eventIDFsignal "Restraint control module: a002 event ID fsignal";
CM_ SG_ 1297 RCM_a002_eventFrontLeftSeatbelt "Restraint control module: a002 event front left seatbelt";
CM_ SG_ 1297 RCM_a002_eventFrontRightSeatbelt "Restraint control module: a002 event front right seatbelt";
CM_ SG_ 1297 RCM_a002_eventVehicleSpeed "Restraint control module: a002 event vehicle speed";
CM_ SG_ 1297 RCM_a002_eventSteeringAngle "Restraint control module: a002 event steering angle";
CM_ SG_ 1297 RCM_a002_eventDriverBrakeApply "Restraint control module: a002 event driver brake apply; raw 3 = signal not available (SNA)";
CM_ SG_ 1297 RCM_a002_eventAccelPedalPos "Restraint control module: a002 event accel pedal pos; raw 255 = signal not available (SNA)";
CM_ SG_ 1297 RCM_a003_eventArmStatus "Restraint control module: a003 event arm status";
CM_ SG_ 1297 RCM_a003_eventFactoryMode "Restraint control module: a003 event factory mode";
CM_ SG_ 1297 RCM_a003_eventDiagEnabled "Restraint control module: a003 event diag enabled";
CM_ SG_ 1297 RCM_a003_eventDriveOrientation "Restraint control module: a003 event drive orientation";
CM_ SG_ 1297 RCM_a003_warningIndicatorOn "Restraint control module: a003 warning indicator on";
CM_ SG_ 1297 RCM_a003_eventIDFsignal "Restraint control module: a003 event ID fsignal";
CM_ SG_ 1297 RCM_a003_eventFrontLeftSeatbelt "Restraint control module: a003 event front left seatbelt";
CM_ SG_ 1297 RCM_a003_eventFrontRightSeatbelt "Restraint control module: a003 event front right seatbelt";
CM_ SG_ 1297 RCM_a003_eventVehicleSpeed "Restraint control module: a003 event vehicle speed";
CM_ SG_ 1297 RCM_a003_eventSteeringAngle "Restraint control module: a003 event steering angle";
CM_ SG_ 1297 RCM_a003_eventDriverBrakeApply "Restraint control module: a003 event driver brake apply; raw 3 = signal not available (SNA)";
CM_ SG_ 1297 RCM_a003_eventAccelPedalPos "Restraint control module: a003 event accel pedal pos; raw 255 = signal not available (SNA)";
CM_ SG_ 1297 RCM_a004_eventArmStatus "Restraint control module: a004 event arm status";
CM_ SG_ 1297 RCM_a004_eventFactoryMode "Restraint control module: a004 event factory mode";
CM_ SG_ 1297 RCM_a004_eventDiagEnabled "Restraint control module: a004 event diag enabled";
CM_ SG_ 1297 RCM_a004_eventDriveOrientation "Restraint control module: a004 event drive orientation";
CM_ SG_ 1297 RCM_a004_frontAlgoDisabled "Restraint control module: a004 front algo disabled";
CM_ SG_ 1297 RCM_a004_sideAlgoDisabled "Restraint control module: a004 side algo disabled";
CM_ SG_ 1297 RCM_a004_rollAlgoDisabled "Restraint control module: a004 roll algo disabled";
CM_ SG_ 1297 RCM_a004_idleMode "Restraint control module: a004 idle mode";
CM_ SG_ 1297 RCM_a004_internalFaultDetected "Restraint control module: a004 internal fault detected";
CM_ SG_ 1297 RCM_a004_swVersionMismatch "Restraint control module: a004 sw version mismatch";
CM_ SG_ 1297 RCM_a004_paramLayoutIDInv "Restraint control module: a004 param layout ID inv";
CM_ SG_ 1297 RCM_a004_algoPASIDMismatch "Restraint control module: a004 algo PASID mismatch";
CM_ SG_ 1297 RCM_a004_eventIDFsignal "Restraint control module: a004 event ID fsignal";
CM_ SG_ 1297 RCM_a004_eventFrontLeftSeatbelt "Restraint control module: a004 event front left seatbelt";
CM_ SG_ 1297 RCM_a004_eventFrontRightSeatbelt "Restraint control module: a004 event front right seatbelt";
CM_ SG_ 1297 RCM_a004_eventVehicleSpeed "Restraint control module: a004 event vehicle speed";
CM_ SG_ 1297 RCM_a004_eventSteeringAngle "Restraint control module: a004 event steering angle";
CM_ SG_ 1297 RCM_a004_eventDriverBrakeApply "Restraint control module: a004 event driver brake apply; raw 3 = signal not available (SNA)";
CM_ SG_ 1297 RCM_a004_eventAccelPedalPos "Restraint control module: a004 event accel pedal pos; raw 255 = signal not available (SNA)";
CM_ SG_ 1297 RCM_a005_eventArmStatus "Restraint control module: a005 event arm status";
CM_ SG_ 1297 RCM_a005_eventFactoryMode "Restraint control module: a005 event factory mode";
CM_ SG_ 1297 RCM_a005_eventDiagEnabled "Restraint control module: a005 event diag enabled";
CM_ SG_ 1297 RCM_a005_eventDriveOrientation "Restraint control module: a005 event drive orientation";
CM_ SG_ 1297 RCM_a005_externalCRCError "Restraint control module: a005 external CRC error";
CM_ SG_ 1297 RCM_a005_eventIDFsignal "Restraint control module: a005 event ID fsignal";
CM_ SG_ 1297 RCM_a005_eventFrontLeftSeatbelt "Restraint control module: a005 event front left seatbelt";
CM_ SG_ 1297 RCM_a005_eventFrontRightSeatbelt "Restraint control module: a005 event front right seatbelt";
CM_ SG_ 1297 RCM_a005_eventVehicleSpeed "Restraint control module: a005 event vehicle speed";
CM_ SG_ 1297 RCM_a005_eventSteeringAngle "Restraint control module: a005 event steering angle";
CM_ SG_ 1297 RCM_a005_eventDriverBrakeApply "Restraint control module: a005 event driver brake apply; raw 3 = signal not available (SNA)";
CM_ SG_ 1297 RCM_a005_eventAccelPedalPos "Restraint control module: a005 event accel pedal pos; raw 255 = signal not available (SNA)";
CM_ SG_ 1297 RCM_a006_eventArmStatus "Restraint control module: a006 event arm status";
CM_ SG_ 1297 RCM_a006_eventFactoryMode "Restraint control module: a006 event factory mode";
CM_ SG_ 1297 RCM_a006_eventDiagEnabled "Restraint control module: a006 event diag enabled";
CM_ SG_ 1297 RCM_a006_eventDriveOrientation "Restraint control module: a006 event drive orientation";
CM_ SG_ 1297 RCM_a006_batteryVoltageTooHigh "Restraint control module: a006 battery voltage too high";
CM_ SG_ 1297 RCM_a006_batteryVoltageTooLow "Restraint control module: a006 battery voltage too low";
CM_ SG_ 1297 RCM_a006_eventIDFsignal "Restraint control module: a006 event ID fsignal";
CM_ SG_ 1297 RCM_a006_eventFrontLeftSeatbelt "Restraint control module: a006 event front left seatbelt";
CM_ SG_ 1297 RCM_a006_eventFrontRightSeatbelt "Restraint control module: a006 event front right seatbelt";
CM_ SG_ 1297 RCM_a006_eventVehicleSpeed "Restraint control module: a006 event vehicle speed";
CM_ SG_ 1297 RCM_a006_eventSteeringAngle "Restraint control module: a006 event steering angle";
CM_ SG_ 1297 RCM_a006_eventDriverBrakeApply "Restraint control module: a006 event driver brake apply; raw 3 = signal not available (SNA)";
CM_ SG_ 1297 RCM_a006_eventAccelPedalPos "Restraint control module: a006 event accel pedal pos; raw 255 = signal not available (SNA)";
CM_ SG_ 1297 RCM_a008_eventArmStatus "Restraint control module: a008 event arm status";
CM_ SG_ 1297 RCM_a008_eventFactoryMode "Restraint control module: a008 event factory mode";
CM_ SG_ 1297 RCM_a008_eventDiagEnabled "Restraint control module: a008 event diag enabled";
CM_ SG_ 1297 RCM_a008_eventDriveOrientation "Restraint control module: a008 event drive orientation";
CM_ SG_ 1297 RCM_a008_lossOfMainPwrSupMonit "Restraint control module: a008 loss of main pwr sup monit";
CM_ SG_ 1297 RCM_a008_lossOfBckupPwrSupMonit "Restraint control module: a008 loss of bckup pwr sup monit";
CM_ SG_ 1297 RCM_a008_normalShtdwnUnavail "Restraint control module: a008 normal shtdwn unavail";
CM_ SG_ 1297 RCM_a008_eventIDFsignal "Restraint control module: a008 event ID fsignal";
CM_ SG_ 1297 RCM_a008_eventFrontLeftSeatbelt "Restraint control module: a008 event front left seatbelt";
CM_ SG_ 1297 RCM_a008_eventFrontRightSeatbelt "Restraint control module: a008 event front right seatbelt";
CM_ SG_ 1297 RCM_a008_eventVehicleSpeed "Restraint control module: a008 event vehicle speed";
CM_ SG_ 1297 RCM_a008_eventSteeringAngle "Restraint control module: a008 event steering angle";
CM_ SG_ 1297 RCM_a008_eventDriverBrakeApply "Restraint control module: a008 event driver brake apply; raw 3 = signal not available (SNA)";
CM_ SG_ 1297 RCM_a008_eventAccelPedalPos "Restraint control module: a008 event accel pedal pos; raw 255 = signal not available (SNA)";
CM_ SG_ 1297 RCM_a009_eventArmStatus "Restraint control module: a009 event arm status";
CM_ SG_ 1297 RCM_a009_eventFactoryMode "Restraint control module: a009 event factory mode";
CM_ SG_ 1297 RCM_a009_eventDiagEnabled "Restraint control module: a009 event diag enabled";
CM_ SG_ 1297 RCM_a009_eventDriveOrientation "Restraint control module: a009 event drive orientation";
CM_ SG_ 1297 RCM_a009_reprogramLimitExceeded "Restraint control module: a009 reprogram limit exceeded";
CM_ SG_ 1297 RCM_a009_eventIDFsignal "Restraint control module: a009 event ID fsignal";
CM_ SG_ 1297 RCM_a009_eventFrontLeftSeatbelt "Restraint control module: a009 event front left seatbelt";
CM_ SG_ 1297 RCM_a009_eventFrontRightSeatbelt "Restraint control module: a009 event front right seatbelt";
CM_ SG_ 1297 RCM_a009_eventVehicleSpeed "Restraint control module: a009 event vehicle speed";
CM_ SG_ 1297 RCM_a009_eventSteeringAngle "Restraint control module: a009 event steering angle";
CM_ SG_ 1297 RCM_a009_eventDriverBrakeApply "Restraint control module: a009 event driver brake apply; raw 3 = signal not available (SNA)";
CM_ SG_ 1297 RCM_a009_eventAccelPedalPos "Restraint control module: a009 event accel pedal pos; raw 255 = signal not available (SNA)";
CM_ SG_ 1297 RCM_a011_eventArmStatus "Restraint control module: a011 event arm status";
CM_ SG_ 1297 RCM_a011_eventFactoryMode "Restraint control module: a011 event factory mode";
CM_ SG_ 1297 RCM_a011_eventDiagEnabled "Restraint control module: a011 event diag enabled";
CM_ SG_ 1297 RCM_a011_eventDriveOrientation "Restraint control module: a011 event drive orientation";
CM_ SG_ 1297 RCM_a011_edrDataAreaLocked "Restraint control module: a011 edr data area locked";
CM_ SG_ 1297 RCM_a011_eventIDFsignal "Restraint control module: a011 event ID fsignal";
CM_ SG_ 1297 RCM_a011_eventFrontLeftSeatbelt "Restraint control module: a011 event front left seatbelt";
CM_ SG_ 1297 RCM_a011_eventFrontRightSeatbelt "Restraint control module: a011 event front right seatbelt";
CM_ SG_ 1297 RCM_a011_eventVehicleSpeed "Restraint control module: a011 event vehicle speed";
CM_ SG_ 1297 RCM_a011_eventSteeringAngle "Restraint control module: a011 event steering angle";
CM_ SG_ 1297 RCM_a011_eventDriverBrakeApply "Restraint control module: a011 event driver brake apply; raw 3 = signal not available (SNA)";
CM_ SG_ 1297 RCM_a011_eventAccelPedalPos "Restraint control module: a011 event accel pedal pos; raw 255 = signal not available (SNA)";
CM_ SG_ 1297 RCM_a012_eventArmStatus "Restraint control module: a012 event arm status";
CM_ SG_ 1297 RCM_a012_eventFactoryMode "Restraint control module: a012 event factory mode";
CM_ SG_ 1297 RCM_a012_eventDiagEnabled "Restraint control module: a012 event diag enabled";
CM_ SG_ 1297 RCM_a012_eventDriveOrientation "Restraint control module: a012 event drive orientation";
CM_ SG_ 1297 RCM_a012_vinMismatch "Restraint control module: a012 vin mismatch";
CM_ SG_ 1297 RCM_a012_vinNotProgrammed "Restraint control module: a012 vin not programmed";
CM_ SG_ 1297 RCM_a012_eventIDFsignal "Restraint control module: a012 event ID fsignal";
CM_ SG_ 1297 RCM_a012_eventFrontLeftSeatbelt "Restraint control module: a012 event front left seatbelt";
CM_ SG_ 1297 RCM_a012_eventFrontRightSeatbelt "Restraint control module: a012 event front right seatbelt";
CM_ SG_ 1297 RCM_a012_eventVehicleSpeed "Restraint control module: a012 event vehicle speed";
CM_ SG_ 1297 RCM_a012_eventSteeringAngle "Restraint control module: a012 event steering angle";
CM_ SG_ 1297 RCM_a012_eventDriverBrakeApply "Restraint control module: a012 event driver brake apply; raw 3 = signal not available (SNA)";
CM_ SG_ 1297 RCM_a012_eventAccelPedalPos "Restraint control module: a012 event accel pedal pos; raw 255 = signal not available (SNA)";
CM_ SG_ 1297 RCM_a013_eventArmStatus "Restraint control module: a013 event arm status";
CM_ SG_ 1297 RCM_a013_eventFactoryMode "Restraint control module: a013 event factory mode";
CM_ SG_ 1297 RCM_a013_eventDiagEnabled "Restraint control module: a013 event diag enabled";
CM_ SG_ 1297 RCM_a013_eventDriveOrientation "Restraint control module: a013 event drive orientation";
CM_ SG_ 1297 RCM_a013_driveOrientiInitNotDone "Restraint control module: a013 drive orienti init not done";
CM_ SG_ 1297 RCM_a013_driveOrientPlausiCheck "Restraint control module: a013 drive orient plausi check";
CM_ SG_ 1297 RCM_a013_eventIDFsignal "Restraint control module: a013 event ID fsignal";
CM_ SG_ 1297 RCM_a013_eventFrontLeftSeatbelt "Restraint control module: a013 event front left seatbelt";
CM_ SG_ 1297 RCM_a013_eventFrontRightSeatbelt "Restraint control module: a013 event front right seatbelt";
CM_ SG_ 1297 RCM_a013_eventVehicleSpeed "Restraint control module: a013 event vehicle speed";
CM_ SG_ 1297 RCM_a013_eventSteeringAngle "Restraint control module: a013 event steering angle";
CM_ SG_ 1297 RCM_a013_eventDriverBrakeApply "Restraint control module: a013 event driver brake apply; raw 3 = signal not available (SNA)";
CM_ SG_ 1297 RCM_a013_eventAccelPedalPos "Restraint control module: a013 event accel pedal pos; raw 255 = signal not available (SNA)";
CM_ SG_ 1297 RCM_a014_eventArmStatus "Restraint control module: a014 event arm status";
CM_ SG_ 1297 RCM_a014_eventFactoryMode "Restraint control module: a014 event factory mode";
CM_ SG_ 1297 RCM_a014_eventDiagEnabled "Restraint control module: a014 event diag enabled";
CM_ SG_ 1297 RCM_a014_eventDriveOrientation "Restraint control module: a014 event drive orientation";
CM_ SG_ 1297 RCM_a014_driverABStg1Sht2Gnd "Restraint control module: a014 driver AB stg1 sht2 gnd";
CM_ SG_ 1297 RCM_a014_driverABStg1Sht2Bat "Restraint control module: a014 driver AB stg1 sht2 bat";
CM_ SG_ 1297 RCM_a014_driverABStg1Open "Restraint control module: a014 driver AB stg1 open";
CM_ SG_ 1297 RCM_a014_driverABStg1Short "Restraint control module: a014 driver AB stg1 short";
CM_ SG_ 1297 RCM_a014_driverABStg1CrossCoup "Restraint control module: a014 driver AB stg1 cross coup";
CM_ SG_ 1297 RCM_a014_driverABStg1Config "Restraint control module: a014 driver AB stg1 config";
CM_ SG_ 1297 RCM_a014_eventIDFsignal "Restraint control module: a014 event ID fsignal";
CM_ SG_ 1297 RCM_a014_eventFrontLeftSeatbelt "Restraint control module: a014 event front left seatbelt";
CM_ SG_ 1297 RCM_a014_eventFrontRightSeatbelt "Restraint control module: a014 event front right seatbelt";
CM_ SG_ 1297 RCM_a014_eventVehicleSpeed "Restraint control module: a014 event vehicle speed";
BA_DEF_ BO_ "GenMsgCycleTime" INT 0 3600000;
BA_DEF_ BO_ "GenMsgSendType" ENUM "Cyclic","NotUsed","NotUsed","NotUsed","NotUsed","NotUsed","NotUsed","IfActive","NoMsgSendType","NotUsed";
BA_DEF_ BO_ "VFrameFormat" ENUM "StandardCAN","ExtendedCAN","reserved","J1939PG","reserved","reserved","reserved","reserved","reserved","reserved","reserved","reserved","reserved","reserved","StandardCAN_FD","ExtendedCAN_FD";
BA_DEF_ BO_ "CANFD_BRS" ENUM "0","1";
BA_DEF_ SG_ "GenSigSNA" STRING;
BA_DEF_ SG_ "SystemSignalLongSymbol" STRING;
BA_DEF_ SG_ "Confidence" ENUM "validated","plausible","layout-only","contradicted";
BA_DEF_DEF_ "GenMsgCycleTime" 0;
BA_DEF_DEF_ "GenMsgSendType" "NoMsgSendType";
BA_DEF_DEF_ "VFrameFormat" "StandardCAN";
BA_DEF_DEF_ "CANFD_BRS" "1";
BA_DEF_DEF_ "GenSigSNA" "";
BA_DEF_DEF_ "SystemSignalLongSymbol" "";
BA_DEF_DEF_ "Confidence" "layout-only";
BA_ "GenMsgCycleTime" BO_ 2047 100;
BA_ "GenMsgSendType" BO_ 2047 0;
BA_ "GenMsgCycleTime" BO_ 792 100;
BA_ "GenMsgSendType" BO_ 792 0;
BA_ "GenMsgCycleTime" BO_ 1638 250;
BA_ "GenMsgSendType" BO_ 1638 0;
BA_ "GenMsgCycleTime" BO_ 1080 100;
BA_ "GenMsgSendType" BO_ 1080 0;
BA_ "GenMsgCycleTime" BO_ 1376 1000;
BA_ "GenMsgSendType" BO_ 1376 0;
BA_ "GenMsgCycleTime" BO_ 1656 100;
BA_ "GenMsgSendType" BO_ 1656 0;
BA_ "GenMsgCycleTime" BO_ 2033 2000;
BA_ "GenMsgSendType" BO_ 2033 0;
BA_ "GenMsgCycleTime" BO_ 2026 1000;
BA_ "GenMsgSendType" BO_ 2026 0;
BA_ "GenMsgCycleTime" BO_ 60 2000;
BA_ "GenMsgSendType" BO_ 60 0;
BA_ "GenMsgCycleTime" BO_ 1370 250;
BA_ "GenMsgSendType" BO_ 1370 0;
BA_ "GenMsgCycleTime" BO_ 840 1000;
BA_ "GenMsgSendType" BO_ 840 0;
BA_ "GenMsgCycleTime" BO_ 1005 1000;
BA_ "GenMsgSendType" BO_ 1005 0;
BA_ "GenMsgCycleTime" BO_ 1112 100;
BA_ "GenMsgSendType" BO_ 1112 0;
BA_ "GenMsgCycleTime" BO_ 767 100;
BA_ "GenMsgSendType" BO_ 767 0;
BA_ "GenMsgCycleTime" BO_ 766 1000;
BA_ "GenMsgSendType" BO_ 766 0;
BA_ "GenMsgCycleTime" BO_ 771 500;
BA_ "GenMsgSendType" BO_ 771 0;
BA_ "GenMsgCycleTime" BO_ 519 100;
BA_ "GenMsgSendType" BO_ 519 0;
BA_ "Confidence" SG_ 2047 GTW_deliveryStatus 0;
BA_ "Confidence" SG_ 2047 GTW_cabinPTCHeaterType 0;
BA_ "Confidence" SG_ 2047 GTW_rightHandDrive 0;
BA_ "Confidence" SG_ 2047 GTW_rearLightType 0;
BA_ "Confidence" SG_ 2047 GTW_headlamps 0;
BA_ "Confidence" SG_ 2047 GTW_country 0;
BA_ "Confidence" SG_ 2047 GTW_tireType 0;
BA_ "Confidence" SG_ 2047 GTW_dasHw 0;
BA_ "Confidence" SG_ 2047 GTW_brakeHWType 0;
BA_ "Confidence" SG_ 2047 GTW_restraintsHardwareType 0;
BA_ "Confidence" SG_ 2047 GTW_drivetrainType 0;
BA_ "Confidence" SG_ 2047 GTW_radarHeaterType 0;
BA_ "Confidence" SG_ 2047 GTW_exteriorTrimType 0;
BA_ "Confidence" SG_ 2047 GTW_frontSeatHeaters 0;
BA_ "Confidence" SG_ 2047 GTW_rearSeatHeaters 0;
BA_ "Confidence" SG_ 2047 GTW_eCallAntennaHW 0;
BA_ "Confidence" SG_ 2047 GTW_homelinkType 0;
BA_ "Confidence" SG_ 2047 GTW_vdcType 0;
BA_ "Confidence" SG_ 2047 GTW_memoryMirrors 0;
BA_ "Confidence" SG_ 2047 GTW_powerLiftgateType 0;
BA_ "Confidence" SG_ 2047 GTW_lumbarECUType 0;
BA_ "Confidence" SG_ 2047 GTW_rearSeatHeaterType 0;
BA_ "Confidence" SG_ 2047 GTW_auxParkLamps 0;
BA_ "Confidence" SG_ 2047 GTW_interiorCabinRadarType 0;
BA_ "Confidence" SG_ 2047 GTW_hvacPanelVaneType 0;
BA_ "Confidence" SG_ 2047 GTW_intakeAirFilterType 0;
BA_ "Confidence" SG_ 2047 GTW_eBuckConfig 0;
BA_ "Confidence" SG_ 2047 GTW_steeringHeaterEnabled 0;
BA_ "Confidence" SG_ 2047 GTW_activeHighBeam 0;
BA_ "Confidence" SG_ 2047 GTW_airbagCutoffSwitch 0;
BA_ "Confidence" SG_ 2047 GTW_intrusionSensorType 0;
BA_ "Confidence" SG_ 2047 GTW_spoilerType 0;
BA_ "Confidence" SG_ 2047 GTW_backupCameraType 0;
BA_ "Confidence" SG_ 2047 GTW_rearFogLamps 0;
BA_ "Confidence" SG_ 2047 GTW_roofType 0;
BA_ "Confidence" SG_ 2047 GTW_thirdRowSeatType 0;
BA_ "Confidence" SG_ 2047 GTW_autopilot 0;
BA_ "Confidence" SG_ 2047 GTW_superchargingAccess 0;
BA_ "Confidence" SG_ 2047 GTW_exteriorColor 0;
BA_ "Confidence" SG_ 2047 GTW_pedestrianWarningSound 0;
BA_ "Confidence" SG_ 2047 GTW_steeringColumnUJointType 0;
BA_ "Confidence" SG_ 2047 GTW_bPillarNFCParam 0;
BA_ "Confidence" SG_ 2047 GTW_interiorLighting 0;
BA_ "Confidence" SG_ 2047 GTW_headlightLevelerType 0;
BA_ "Confidence" SG_ 2047 GTW_numberHVILNodes 0;
BA_ "Confidence" SG_ 2047 GTW_mapRegion 0;
BA_ "Confidence" SG_ 2047 GTW_performancePackage 0;
BA_ "Confidence" SG_ 2047 GTW_chassisType 0;
BA_ "Confidence" SG_ 2047 GTW_airSuspension 0;
BA_ "Confidence" SG_ 2047 GTW_centerConsoleControllerType 0;
BA_ "Confidence" SG_ 2047 GTW_autopilotCameraType 0;
BA_ "Confidence" SG_ 2047 GTW_connectivityPackage 0;
BA_ "Confidence" SG_ 2047 GTW_plcSupportType 0;
BA_ "Confidence" SG_ 2047 GTW_badgingVersion 0;
BA_ "Confidence" SG_ 2047 GTW_packEnergy 0;
BA_ "Confidence" SG_ 2047 GTW_frontSeatReclinerHardware 0;
BA_ "Confidence" SG_ 2047 GTW_brakeLineSwitchType 0;
BA_ "Confidence" SG_ 2047 GTW_espValveType 0;
BA_ "Confidence" SG_ 2047 GTW_softRange 0;
BA_ "Confidence" SG_ 2047 GTW_refrigerantType 0;
BA_ "Confidence" SG_ 2047 GTW_wheelType 0;
BA_ "Confidence" SG_ 2047 GTW_ptcControlMode 0;
BA_ "Confidence" SG_ 2047 GTW_brakeActuationType 0;
BA_ "Confidence" SG_ 2047 GTW_secondRowSeatType 0;
BA_ "Confidence" SG_ 2047 GTW_secondRowSeatMotorType 0;
BA_ "Confidence" SG_ 2047 GTW_birthday 0;
BA_ "Confidence" SG_ 2047 GTW_eCallEnabled 0;
BA_ "Confidence" SG_ 2047 GTW_parkAssistECUType 0;
BA_ "Confidence" SG_ 2047 GTW_passengerAirbagType 0;
BA_ "Confidence" SG_ 2047 GTW_forwardRadarHw 0;
BA_ "Confidence" SG_ 2047 GTW_frontSeatType 0;
BA_ "Confidence" SG_ 2047 GTW_secondRowDisplayType 0;
BA_ "Confidence" SG_ 2047 GTW_wirelessPhoneChargerType 0;
BA_ "Confidence" SG_ 2047 GTW_ethernetTunerType 0;
BA_ "Confidence" SG_ 2047 GTW_interiorTrimType 0;
BA_ "Confidence" SG_ 2047 GTW_gloveboxUSBType 0;
BA_ "Confidence" SG_ 2047 GTW_coolantPumpType 0;
BA_ "Confidence" SG_ 2047 GTW_epblHwType 0;
BA_ "Confidence" SG_ 2047 GTW_epbrHwType 0;
BA_ "Confidence" SG_ 2047 GTW_blowerMotorType 0;
BA_ "Confidence" SG_ 2047 GTW_rearLeftBLEEndpointParameter 0;
BA_ "SystemSignalLongSymbol" SG_ 2047 GTW_rearLeftBLEEndpointParameter "GTW_rearLeftBLEEndpointParameterType";
BA_ "Confidence" SG_ 2047 GTW_powerMirrorFoldType 0;
BA_ "Confidence" SG_ 2047 GTW_frontUsbHubType 0;
BA_ "Confidence" SG_ 2047 GTW_superManifoldType 0;
BA_ "Confidence" SG_ 2047 GTW_rcmLocation 0;
BA_ "Confidence" SG_ 2047 GTW_autopilotExteriorCameraType 0;
BA_ "Confidence" SG_ 2047 GTW_interiorCamBeautyCoverType 0;
BA_ "Confidence" SG_ 2047 GTW_sirenType 0;
BA_ "Confidence" SG_ 2047 GTW_hornType 0;
BA_ "Confidence" SG_ 2047 GTW_passengerTrackMotorType 0;
BA_ "Confidence" SG_ 2047 GTW_steeringColumnMotorType 0;
BA_ "Confidence" SG_ 2047 GTW_refrigACLineType 0;
BA_ "Confidence" SG_ 2047 GTW_refrigFilterType 0;
BA_ "Confidence" SG_ 2047 GTW_diBurnInType 0;
BA_ "Confidence" SG_ 2047 GTW_specialBadgingType 0;
BA_ "Confidence" SG_ 2047 GTW_chassisSubType 0;
BA_ "Confidence" SG_ 2047 GTW_towPackage 0;
BA_ "Confidence" SG_ 2047 GTW_refrigLccType 0;
BA_ "Confidence" SG_ 2047 GTW_restraintControlsType 0;
BA_ "Confidence" SG_ 2047 GTW_caliperColorType 0;
BA_ "Confidence" SG_ 2047 GTW_wiperMotorType 0;
BA_ "Confidence" SG_ 2047 GTW_frontOverheadConsoleType 0;
BA_ "Confidence" SG_ 2047 GTW_shifterType 0;
BA_ "Confidence" SG_ 2047 GTW_compressorType 0;
BA_ "Confidence" SG_ 2047 GTW_twelveVBatteryType 0;
BA_ "Confidence" SG_ 2047 GTW_efuseSWConfig 0;
BA_ "Confidence" SG_ 2047 GTW_tollCollectionModuleType 0;
BA_ "Confidence" SG_ 2047 GTW_bleEndpointUpdateMethod 0;
BA_ "Confidence" SG_ 2047 GTW_steeringWheelControllerType 0;
BA_ "Confidence" SG_ 2047 GTW_frontSeatVentilationEnabled 0;
BA_ "Confidence" SG_ 2047 GTW_gloveboxActuatorType 0;
BA_ "Confidence" SG_ 2047 GTW_epasType 0;
BA_ "Confidence" SG_ 2047 GTW_homologationRegionOverride 0;
BA_ "Confidence" SG_ 2047 GTW_windowCommandsPermissionType 0;
BA_ "Confidence" SG_ 2047 GTW_headlightStepperStallDetectM 0;
BA_ "SystemSignalLongSymbol" SG_ 2047 GTW_headlightStepperStallDetectM "GTW_headlightStepperStallDetectMode";
BA_ "Confidence" SG_ 2047 GTW_rgbInteriorLightingEnabled 0;
BA_ "Confidence" SG_ 2047 GTW_windshieldWiperHeaterType 0;
BA_ "Confidence" SG_ 2047 GTW_thirdRowSeatReclinerType 0;
BA_ "Confidence" SG_ 2047 GTW_driveInterfaceType 0;
BA_ "Confidence" SG_ 2047 GTW_efficiencyPackage 0;
BA_ "Confidence" SG_ 2047 GTW_visorLightType 0;
BA_ "Confidence" SG_ 2047 GTW_gnssAntennaType 0;
BA_ "Confidence" SG_ 2047 GTW_airDistributionBoxType 0;
BA_ "Confidence" SG_ 2047 GTW_frontSeatHeatersEnabled 0;
BA_ "Confidence" SG_ 2047 GTW_windshieldWiperHeaterEnabled 0;
BA_ "Confidence" SG_ 2047 GTW_alcoholInterlockType 0;
BA_ "Confidence" SG_ 2047 GTW_fasciaType 0;
BA_ "Confidence" SG_ 2047 GTW_powerSteeringColumn 0;
BA_ "Confidence" SG_ 2047 GTW_frontSeatHeaterType 0;
BA_ "Confidence" SG_ 2047 GTW_softPerformanceLimit 0;
BA_ "Confidence" SG_ 2047 GTW_gsrFeatureType 0;
BA_ "Confidence" SG_ 2047 GTW_immersiveAudio 0;
BA_ "Confidence" SG_ 2047 GTW_frontSeatVentilationType 0;
BA_ "Confidence" SG_ 2047 GTW_passengerOccupancySensorType 0;
BA_ "Confidence" SG_ 2047 GTW_packPerformanceDeviation 0;
BA_ "Confidence" SG_ 2047 GTW_pressurePadType 1;
BA_ "Confidence" SG_ 2047 GTW_frontFogLamps 0;
BA_ "Confidence" SG_ 2047 GTW_driverOccupancySensorType 0;
BA_ "Confidence" SG_ 2047 GTW_audioType 0;
BA_ "Confidence" SG_ 2047 GTW_thighExtenderType 0;
BA_ "Confidence" SG_ 2047 GTW_occupancyClassificationFeatu 0;
BA_ "SystemSignalLongSymbol" SG_ 2047 GTW_occupancyClassificationFeatu "GTW_occupancyClassificationFeatureType";
BA_ "Confidence" SG_ 2047 GTW_frontControllerArchitectureT 0;
BA_ "SystemSignalLongSymbol" SG_ 2047 GTW_frontControllerArchitectureT "GTW_frontControllerArchitectureType";
BA_ "Confidence" SG_ 2047 GTW_domeLightType 0;
BA_ "Confidence" SG_ 2047 GTW_tpmsType 0;
BA_ "Confidence" SG_ 2047 GTW_authenticationEndpointLayout 0;
BA_ "Confidence" SG_ 2047 GTW_socSleepOverride 0;
BA_ "Confidence" SG_ 2047 GTW_r79BehaviorOverride 0;
BA_ "Confidence" SG_ 2047 GTW_steeringHeaterType 0;
BA_ "Confidence" SG_ 2047 GTW_narrowWipingSupported 0;
BA_ "Confidence" SG_ 2047 GTW_frontSeatHeaterGridType 0;
BA_ "Confidence" SG_ 2047 GTW_frontSeatSideSwitchType 0;
BA_ "Confidence" SG_ 2047 GTW_sohRegulatoryStatus 0;
BA_ "Confidence" SG_ 2047 GTW_passengerTiltMotorType 0;
BA_ "Confidence" SG_ 2047 GTW_frunkInteriorReleaseType 0;
BA_ "Confidence" SG_ 2047 GTW_m3yBusArchitecture 0;
BA_ "Confidence" SG_ 2047 GTW_passengerLiftMotorType 0;
BA_ "Confidence" SG_ 2047 GTW_interiorUpperTrimType 0;
BA_ "Confidence" SG_ 2047 GTW_blindSpotIndicatorLightType 0;
BA_ "Confidence" SG_ 2047 GTW_wiperMotorAsicType 0;
BA_ "Confidence" SG_ 2047 GTW_hvacCaseDoorType 0;
BA_ "Confidence" SG_ 2047 GTW_occupancyDetectionSourceRequ 0;
BA_ "SystemSignalLongSymbol" SG_ 2047 GTW_occupancyDetectionSourceRequ "GTW_occupancyDetectionSourceRequest";
BA_ "Confidence" SG_ 2047 GTW_rduCableType 0;
BA_ "Confidence" SG_ 2047 GTW_parkTelltaleBehaviorType 0;
BA_ "Confidence" SG_ 2047 GTW_numberKeyCardsPairedInFactor 0;
BA_ "SystemSignalLongSymbol" SG_ 2047 GTW_numberKeyCardsPairedInFactor "GTW_numberKeyCardsPairedInFactory";
BA_ "Confidence" SG_ 2047 GTW_secondRowSeatVentilationType 0;
BA_ "Confidence" SG_ 2047 GTW_thirdRowSeatHeaterType 0;
BA_ "Confidence" SG_ 2047 GTW_interiorCameraType 0;
BA_ "Confidence" SG_ 2047 GTW_frontFasciaCameraType 0;
BA_ "Confidence" SG_ 2047 GTW_interiorCamFanType 0;
BA_ "Confidence" SG_ 2047 GTW_puddleLampType 0;
BA_ "Confidence" SG_ 2047 GTW_solarLensType 0;
BA_ "Confidence" SG_ 2047 GTW_liftgateGeometryType 0;
BA_ "Confidence" SG_ 2047 GTW_repeaterAeroRibType 0;
BA_ "Confidence" SG_ 2047 GTW_highTipForceWiperArmsType 0;
BA_ "Confidence" SG_ 2047 GTW_rcmUndersideAbuseZThreshold 0;
BA_ "Confidence" SG_ 2047 GTW_rcmUndersideAbuseYThreshold 0;
BA_ "Confidence" SG_ 2047 GTW_rcmUndersideAbuseWindow 0;
BA_ "Confidence" SG_ 2047 GTW_uhfChargePortEnabled 0;
BA_ "Confidence" SG_ 2047 GTW_automaticFeatureResetPackage 0;
BA_ "Confidence" SG_ 2047 GTW_autopilotFeaturePackage 0;
BA_ "Confidence" SG_ 2047 GTW_doorLatchType 0;
BA_ "Confidence" SG_ 2047 GTW_headlinerMaterialType 0;
BA_ "Confidence" SG_ 2047 GTW_glareShieldHeaterType 0;
BA_ "Confidence" SG_ 2047 GTW_rearLightHardwareVariant 0;
BA_ "Confidence" SG_ 2047 GTW_fasciaHarnessCleanPointType 0;
BA_ "Confidence" SG_ 2047 GTW_epasSubType 0;
BA_ "Confidence" SG_ 2047 GTW_wiperSupplyChainOrigin 0;
BA_ "GenSigSNA" SG_ 2047 GTW_wiperSupplyChainOrigin "0";
BA_ "Confidence" SG_ 2047 GTW_windowPinchParameterType 0;
BA_ "Confidence" SG_ 2047 GTW_badgingMaterialType 0;
BA_ "Confidence" SG_ 2047 GTW_mRecordVersion 0;
BA_ "Confidence" SG_ 2047 GTW_tcuType 0;
BA_ "Confidence" SG_ 2047 GTW_carbComplianceBehaviorType 0;
BA_ "Confidence" SG_ 2047 GTW_indirectTPMSCalibrationType 0;
BA_ "Confidence" SG_ 2047 GTW_v2xEnabled 0;
BA_ "Confidence" SG_ 2047 GTW_liftgateStrutType 0;
BA_ "Confidence" SG_ 2047 GTW_exteriorMicrophoneType 0;
BA_ "Confidence" SG_ 2047 GTW_contactorPowerSource 0;
BA_ "Confidence" SG_ 2047 GTW_roofGlassType 0;
BA_ "Confidence" SG_ 2047 GTW_pedalMapNameOverride 0;
BA_ "Confidence" SG_ 792 GTW_factoryGated 1;
BA_ "Confidence" SG_ 1638 GTW_diagRemainingSeconds 0;
BA_ "Confidence" SG_ 1638 GTW_diagSessionActive 0;
BA_ "Confidence" SG_ 1638 GTW_diagLevel 0;
BA_ "Confidence" SG_ 1638 GTW_diagUnlockProcedureActive 0;
BA_ "Confidence" SG_ 1638 GTW_diagOverrideActive 0;
BA_ "Confidence" SG_ 1638 GTW_diagPhysicalLinkEstablished 0;
BA_ "Confidence" SG_ 1080 GTW_ethGotoSleep 0;
BA_ "Confidence" SG_ 1080 GTW_ethWakeUpBus 0;
BA_ "Confidence" SG_ 1080 GTW_vehBusAsleep 0;
BA_ "Confidence" SG_ 1080 GTW_ethHeartBeatCounter 0;
BA_ "Confidence" SG_ 1080 GTW_ethWakeUpReason 0;
BA_ "Confidence" SG_ 1376 GTW_OCS1Ppresent 1;
BA_ "Confidence" SG_ 1376 GTW_PCSpresent 1;
BA_ "Confidence" SG_ 1376 GTW_HVPpresent 1;
BA_ "Confidence" SG_ 1376 GTW_BMSpresent 1;
BA_ "Confidence" SG_ 1376 GTW_CPpresent 1;
BA_ "Confidence" SG_ 1376 GTW_RCMpresent 1;
BA_ "Confidence" SG_ 1376 GTW_SCCMpresent 1;
BA_ "Confidence" SG_ 1376 GTW_VCSECpresent 1;
BA_ "Confidence" SG_ 1376 GTW_EPAS3Ppresent 1;
BA_ "Confidence" SG_ 1376 GTW_EPBLpresent 1;
BA_ "Confidence" SG_ 1376 GTW_EPBRpresent 1;
BA_ "Confidence" SG_ 1376 GTW_ESPpresent 1;
BA_ "Confidence" SG_ 1376 GTW_IBSTpresent 1;
BA_ "Confidence" SG_ 1376 GTW_PARKpresent 1;
BA_ "Confidence" SG_ 1376 GTW_RADCpresent 1;
BA_ "Confidence" SG_ 1376 GTW_TPMSpresent 1;
BA_ "Confidence" SG_ 1376 GTW_VCFRONTpresent 1;
BA_ "Confidence" SG_ 1376 GTW_VCLEFTpresent 1;
BA_ "Confidence" SG_ 1376 GTW_VCRIGHTpresent 1;
BA_ "Confidence" SG_ 1376 GTW_EPAS3Spresent 1;
BA_ "Confidence" SG_ 1376 GTW_CMPpresent 1;
BA_ "Confidence" SG_ 1376 GTW_DASpresent 1;
BA_ "Confidence" SG_ 1376 GTW_PTCpresent 1;
BA_ "Confidence" SG_ 1376 GTW_SWCpresent 1;
BA_ "Confidence" SG_ 1376 GTW_PMRpresent 1;
BA_ "Confidence" SG_ 1376 GTW_PMFpresent 1;
BA_ "Confidence" SG_ 1376 GTW_DIRpresent 1;
BA_ "Confidence" SG_ 1376 GTW_DIFpresent 1;
BA_ "Confidence" SG_ 1656 GTW_gearControlChecksum 0;
BA_ "Confidence" SG_ 1656 GTW_gearControlCounter 0;
BA_ "Confidence" SG_ 1656 GTW_gearShiftRequest 0;
BA_ "GenSigSNA" SG_ 1656 GTW_gearShiftRequest "0";
BA_ "Confidence" SG_ 1656 GTW_osdActive 0;
BA_ "Confidence" SG_ 1656 GTW_primaryGearControlStatus 0;
BA_ "Confidence" SG_ 1656 GTW_gearStripEnable 0;
BA_ "Confidence" SG_ 1656 GTW_showNeutralButton 0;
BA_ "Confidence" SG_ 1656 GTW_showAutoParkButton 0;
BA_ "Confidence" SG_ 1656 GTW_autoParkRequest 0;
BA_ "Confidence" SG_ 1656 GTW_smartShiftStatus 0;
BA_ "GenSigSNA" SG_ 1656 GTW_smartShiftStatus "0";
BA_ "Confidence" SG_ 1656 GTW_processingRDgestures 0;
BA_ "Confidence" SG_ 1656 GTW_processingTapPgestures 0;
BA_ "Confidence" SG_ 1656 GTW_gearStripChangeReason 0;
BA_ "GenSigSNA" SG_ 1656 GTW_gearStripChangeReason "0";
BA_ "Confidence" SG_ 1656 GTW_touchActive 0;
BA_ "Confidence" SG_ 1656 GTW_steamOff 0;
BA_ "Confidence" SG_ 1656 GTW_screenPCBTemperature 1;
BA_ "GenSigSNA" SG_ 1656 GTW_screenPCBTemperature "2047";
BA_ "Confidence" SG_ 2033 GTW_hrlIndex 1;
BA_ "Confidence" SG_ 2033 GTW_hrlSdCardSizeGB 0;
BA_ "GenSigSNA" SG_ 2033 GTW_hrlSdCardSizeGB "0";
BA_ "Confidence" SG_ 2033 GTW_hrlState 0;
BA_ "Confidence" SG_ 2033 GTW_hrlTriggerDuration 1;
BA_ "Confidence" SG_ 2033 GTW_hrlTriggerType 0;
BA_ "Confidence" SG_ 2033 GTW_hrlTriggerId 1;
BA_ "Confidence" SG_ 2026 GTW_hrlEventStartEpoch 1;
BA_ "Confidence" SG_ 2026 GTW_hrlEventEndEpoch 1;
BA_ "Confidence" SG_ 60 GTW_infoIndex 1;
BA_ "Confidence" SG_ 60 GTW_buildType 0;
BA_ "Confidence" SG_ 60 GTW_hardwareId 0;
BA_ "Confidence" SG_ 60 GTW_platformType 0;
BA_ "Confidence" SG_ 60 GTW_appCrc 0;
BA_ "Confidence" SG_ 60 GTW_applicationGitHash 0;
BA_ "Confidence" SG_ 60 GTW_bootGitHash 0;
BA_ "Confidence" SG_ 1370 GTW_mismatchFaultIndex 1;
BA_ "Confidence" SG_ 1370 GTW_mismatchFaultChecksum 0;
BA_ "Confidence" SG_ 1370 GTW_mismatchFaultCounter 0;
BA_ "Confidence" SG_ 1370 GTW_GTWmismatchFault 0;
BA_ "Confidence" SG_ 1370 GTW_BMSmismatchFault 0;
BA_ "Confidence" SG_ 1370 GTW_APSmismatchFault 0;
BA_ "Confidence" SG_ 1370 GTW_BLEEPCENTERmismatchFault 0;
BA_ "Confidence" SG_ 1370 GTW_BLEEPLEFTmismatchFault 0;
BA_ "Confidence" SG_ 1370 GTW_BLEEPREARmismatchFault 0;
BA_ "Confidence" SG_ 1370 GTW_BLEEPRIGHTmismatchFault 0;
BA_ "Confidence" SG_ 1370 GTW_CBCmismatchFault 0;
BA_ "Confidence" SG_ 1370 GTW_CMPmismatchFault 0;
BA_ "Confidence" SG_ 1370 GTW_CPmismatchFault 0;
BA_ "Confidence" SG_ 1370 GTW_DIFmismatchFault 0;
BA_ "Confidence" SG_ 1370 GTW_DIRmismatchFault 0;
BA_ "Confidence" SG_ 1370 GTW_EPAS3PmismatchFault 0;
BA_ "Confidence" SG_ 1370 GTW_EPAS3SmismatchFault 0;
BA_ "Confidence" SG_ 1370 GTW_EPBLmismatchFault 0;
BA_ "Confidence" SG_ 1370 GTW_EPBRmismatchFault 0;
BA_ "Confidence" SG_ 1370 GTW_ESPCALmismatchFault 0;
BA_ "Confidence" SG_ 1370 GTW_ESPmismatchFault 0;
BA_ "Confidence" SG_ 1370 GTW_HCM3LmismatchFault 0;
BA_ "Confidence" SG_ 1370 GTW_HCM3RmismatchFault 0;
BA_ "Confidence" SG_ 1370 GTW_HCMLmismatchFault 0;
BA_ "Confidence" SG_ 1370 GTW_HCMRmismatchFault 0;
BA_ "Confidence" SG_ 1370 GTW_HVPmismatchFault 0;
BA_ "Confidence" SG_ 1370 GTW_IBSTCALmismatchFault 0;
BA_ "Confidence" SG_ 1370 GTW_IBSTmismatchFault 0;
BA_ "Confidence" SG_ 1370 GTW_LVBMSmismatchFault 0;
BA_ "Confidence" SG_ 1370 GTW_OCS1PmismatchFault 0;
BA_ "Confidence" SG_ 1370 GTW_OPCFmismatchFault 0;
BA_ "Confidence" SG_ 1370 GTW_OPCRmismatchFault 0;
BA_ "Confidence" SG_ 1370 GTW_PARKmismatchFault 0;
BA_ "Confidence" SG_ 1370 GTW_PCSCPU2mismatchFault 0;
BA_ "Confidence" SG_ 1370 GTW_PCSmismatchFault 0;
BA_ "Confidence" SG_ 1370 GTW_PMFmismatchFault 0;
BA_ "Confidence" SG_ 1370 GTW_PMRmismatchFault 0;
BA_ "Confidence" SG_ 1370 GTW_PTCmismatchFault 0;
BA_ "Confidence" SG_ 1370 GTW_RCMCALmismatchFault 0;
BA_ "Confidence" SG_ 1370 GTW_RCMmismatchFault 0;
BA_ "Confidence" SG_ 1370 GTW_SCCMmismatchFault 0;
BA_ "Confidence" SG_ 1370 GTW_SDCRmismatchFault 0;
BA_ "Confidence" SG_ 1370 GTW_SWCmismatchFault 0;
BA_ "Confidence" SG_ 1370 GTW_THSmismatchFault 0;
BA_ "Confidence" SG_ 1370 GTW_VCFRONTmismatchFault 0;
BA_ "Confidence" SG_ 1370 GTW_VCLEFTmismatchFault 0;
BA_ "Confidence" SG_ 1370 GTW_VCRIGHTmismatchFault 0;
BA_ "Confidence" SG_ 1370 GTW_VCSECmismatchFault 0;
BA_ "Confidence" SG_ 1370 GTW_PMmismatchFault 0;
BA_ "Confidence" SG_ 840 GTW_vehicleVersionMatchStatus 0;
BA_ "Confidence" SG_ 840 GTW_hwtype 0;
BA_ "GenSigSNA" SG_ 840 GTW_hwtype "0";
BA_ "Confidence" SG_ 840 GTW_jcanProductName 0;
BA_ "GenSigSNA" SG_ 840 GTW_jcanProductName "0";
BA_ "Confidence" SG_ 840 GTW_uptimeSeconds 1;
BA_ "Confidence" SG_ 840 GTW_boardRevision 0;
BA_ "Confidence" SG_ 840 GTW_touchcoreOsType 0;
BA_ "Confidence" SG_ 840 GTW_sentryModeState 0;
BA_ "GenSigSNA" SG_ 840 GTW_sentryModeState "6";
BA_ "Confidence" SG_ 840 GTW_secureBootEnabled 0;
BA_ "Confidence" SG_ 840 GTW_socSleepType 0;
BA_ "GenSigSNA" SG_ 840 GTW_socSleepType "0";
BA_ "Confidence" SG_ 840 GTW_resetType 0;
BA_ "GenSigSNA" SG_ 840 GTW_resetType "0";
BA_ "Confidence" SG_ 1005 GTW_peripheralConfirmedUpdateNee 1;
BA_ "SystemSignalLongSymbol" SG_ 1005 GTW_peripheralConfirmedUpdateNee "GTW_peripheralConfirmedUpdateNeeded";
BA_ "Confidence" SG_ 1005 GTW_ocuFailed 0;
BA_ "Confidence" SG_ 1005 GTW_ecuUpdateStarted 0;
BA_ "Confidence" SG_ 1005 GTW_updateStarted 1;
BA_ "Confidence" SG_ 1112 GTW_nmGoingToSleep 0;
BA_ "Confidence" SG_ 1112 GTW_nmWakeUpBus 0;
BA_ "Confidence" SG_ 1112 GTW_chBusAsleep 0;
BA_ "Confidence" SG_ 1112 GTW_ethBusAsleep 0;
BA_ "Confidence" SG_ 1112 GTW_nmKeepAwakeReason 0;
BA_ "GenSigSNA" SG_ 1112 GTW_nmKeepAwakeReason "0";
BA_ "Confidence" SG_ 1112 GTW_nmWakeUpReason 0;
BA_ "Confidence" SG_ 1112 GTW_ethKeepAwakeReason 0;
BA_ "GenSigSNA" SG_ 1112 GTW_ethKeepAwakeReason "0";
BA_ "Confidence" SG_ 1112 GTW_nmDebugWakeUp 0;
BA_ "Confidence" SG_ 1112 GTW_OTAKeepAwake 0;
BA_ "Confidence" SG_ 1112 GTW_smsPokeReceived 0;
BA_ "Confidence" SG_ 1112 GTW_bdyBusAsleep 0;
BA_ "Confidence" SG_ 1429 OCS1P_alertID 1;
BA_ "Confidence" SG_ 1429 OCS1P_alertState 1;
BA_ "Confidence" SG_ 767 OCS1P_matrixIndex 1;
BA_ "SystemSignalLongSymbol" SG_ 767 OCS1P_w148_classificationMismatc "OCS1P_w148_classificationMismatch";
BA_ "SystemSignalLongSymbol" SG_ 767 OCS1P_w156_seatbeltReminderUnava "OCS1P_w156_seatbeltReminderUnavailable";
BA_ "Confidence" SG_ 766 OCS1P_infoIndex 1;
BA_ "Confidence" SG_ 766 OCS1P_infoBuildType 0;
BA_ "Confidence" SG_ 766 OCS1P_infoBuildConfigID 0;
BA_ "Confidence" SG_ 766 OCS1P_infoHardwareID 0;
BA_ "Confidence" SG_ 766 OCS1P_infoComponentID 0;
BA_ "Confidence" SG_ 766 OCS1P_infoPcbaID 0;
BA_ "Confidence" SG_ 766 OCS1P_infoAssemblyID 0;
BA_ "Confidence" SG_ 766 OCS1P_infoUsageID 0;
BA_ "Confidence" SG_ 766 OCS1P_infoSubUsageID 0;
BA_ "Confidence" SG_ 766 OCS1P_infoApplicationCRC 0;
BA_ "Confidence" SG_ 766 OCS1P_infoBootSvnRev 0;
BA_ "Confidence" SG_ 766 OCS1P_infoAppGitHashBytes 0;
BA_ "Confidence" SG_ 766 OCS1P_infoBootGitHashBytes 0;
BA_ "Confidence" SG_ 766 OCS1P_infoPlatformType 0;
BA_ "Confidence" SG_ 766 OCS1P_infoBootUdsProtoVersion 0;
BA_ "Confidence" SG_ 766 OCS1P_infoBootloaderCRC 0;
BA_ "Confidence" SG_ 771 OCS1P_occupantClassification 0;
BA_ "GenSigSNA" SG_ 771 OCS1P_occupantClassification "255";
BA_ "Confidence" SG_ 771 OCS1P_occupantClassificationQF 0;
BA_ "Confidence" SG_ 771 OCS1P_occupiedState 0;
BA_ "GenSigSNA" SG_ 771 OCS1P_occupiedState "3";
BA_ "Confidence" SG_ 771 OCS1P_triggerSnapshot 0;
BA_ "Confidence" SG_ 771 OCS1P_occupantClassificationRaw 0;
BA_ "GenSigSNA" SG_ 771 OCS1P_occupantClassificationRaw "7";
BA_ "Confidence" SG_ 771 OCS1P_occupantClassificationSelf 0;
BA_ "GenSigSNA" SG_ 771 OCS1P_occupantClassificationSelf "7";
BA_ "Confidence" SG_ 771 OCS1P_occupantClassificationRawC 0;
BA_ "GenSigSNA" SG_ 771 OCS1P_occupantClassificationRawC "7";
BA_ "SystemSignalLongSymbol" SG_ 771 OCS1P_occupantClassificationRawC "OCS1P_occupantClassificationRawCap";
BA_ "Confidence" SG_ 771 OCS1P_occupantClassificationCap 0;
BA_ "GenSigSNA" SG_ 771 OCS1P_occupantClassificationCap "7";
BA_ "Confidence" SG_ 771 OCS1P_classificationHeld 0;
BA_ "Confidence" SG_ 771 OCS1P_cushionStable 0;
BA_ "Confidence" SG_ 771 OCS1P_classificationExtHold 0;
BA_ "Confidence" SG_ 771 OCS1P_classificationHoldState 0;
BA_ "Confidence" SG_ 771 OCS1P_classificationVariant 0;
BA_ "Confidence" SG_ 771 OCS1P_sandwichDisabled 0;
BA_ "Confidence" SG_ 771 OCS1P_noSandwichType 0;
BA_ "Confidence" SG_ 771 OCS1P_sandwichBoundaryType 0;
BA_ "Confidence" SG_ 771 OCS1P_sbrBoundaryType 0;
BA_ "Confidence" SG_ 771 OCS1P_occupiedStateCap 0;
BA_ "GenSigSNA" SG_ 771 OCS1P_occupiedStateCap "3";
BA_ "Confidence" SG_ 771 OCS1P_seatbackStable 0;
BA_ "Confidence" SG_ 771 OCS1P_sandwichStable 0;
BA_ "Confidence" SG_ 771 OCS1P_cushionStableCap 0;
BA_ "Confidence" SG_ 771 OCS1P_seatbackStableCap 0;
BA_ "Confidence" SG_ 771 OCS1P_classificationHeldCap 0;
BA_ "Confidence" SG_ 771 OCS1P_statusCounter 0;
BA_ "Confidence" SG_ 771 OCS1P_statusChecksum 0;
BA_ "Confidence" SG_ 1619 OCS1P_udsResponseData 1;
BA_ "Confidence" SG_ 519 PTC_leftFlagFault 0;
BA_ "Confidence" SG_ 519 PTC_rightFlagFault 0;
BA_ "Confidence" SG_ 519 PTC_leftPowerDerating 0;
BA_ "Confidence" SG_ 519 PTC_rightPowerDerating 0;
BA_ "Confidence" SG_ 519 PTC_ocpEvent 0;
BA_ "Confidence" SG_ 519 PTC_leftDutyFeedback 0;
BA_ "Confidence" SG_ 519 PTC_rightDutyFeedback 0;
BA_ "Confidence" SG_ 519 PTC_leftPowerHV 0;
BA_ "Confidence" SG_ 519 PTC_rightPowerHV 0;
BA_ "Confidence" SG_ 519 PTC_leftTempEstOutlet 0;
BA_ "Confidence" SG_ 519 PTC_rightTempEstOutlet 0;
BA_ "Confidence" SG_ 519 PTC_tliErrorCount 0;
BA_ "Confidence" SG_ 519 PTC_tliEvent 0;
BA_ "Confidence" SG_ 519 PTC_tliSource 0;
BA_ "Confidence" SG_ 1297 RCM_alertID 1;
BA_ "Confidence" SG_ 1297 RCM_alertState 1;
BA_ "Confidence" SG_ 1297 RCM_a000_eventArmStatus 1;
BA_ "Confidence" SG_ 1297 RCM_a000_eventFactoryMode 1;
BA_ "Confidence" SG_ 1297 RCM_a000_eventDiagEnabled 1;
BA_ "Confidence" SG_ 1297 RCM_a000_eventDriveOrientation 1;
BA_ "Confidence" SG_ 1297 RCM_a000_eventIDFsignal 1;
BA_ "Confidence" SG_ 1297 RCM_a000_eventFrontLeftSeatbelt 1;
BA_ "Confidence" SG_ 1297 RCM_a000_eventFrontRightSeatbelt 1;
BA_ "Confidence" SG_ 1297 RCM_a000_eventVehicleSpeed 1;
BA_ "Confidence" SG_ 1297 RCM_a000_eventSteeringAngle 1;
BA_ "Confidence" SG_ 1297 RCM_a000_eventDriverBrakeApply 1;
BA_ "Confidence" SG_ 1297 RCM_a000_eventAccelPedalPos 1;
BA_ "Confidence" SG_ 1297 RCM_a001_eventArmStatus 1;
BA_ "Confidence" SG_ 1297 RCM_a001_eventFactoryMode 1;
BA_ "Confidence" SG_ 1297 RCM_a001_eventDiagEnabled 1;
BA_ "Confidence" SG_ 1297 RCM_a001_eventDriveOrientation 1;
BA_ "Confidence" SG_ 1297 RCM_a001_eventIDFsignal 1;
BA_ "Confidence" SG_ 1297 RCM_a001_eventFrontLeftSeatbelt 1;
BA_ "Confidence" SG_ 1297 RCM_a001_eventFrontRightSeatbelt 1;
BA_ "Confidence" SG_ 1297 RCM_a001_eventVehicleSpeed 1;
BA_ "Confidence" SG_ 1297 RCM_a001_eventSteeringAngle 1;
BA_ "Confidence" SG_ 1297 RCM_a001_eventDriverBrakeApply 1;
BA_ "GenSigSNA" SG_ 1297 RCM_a001_eventDriverBrakeApply "3";
BA_ "Confidence" SG_ 1297 RCM_a001_eventAccelPedalPos 1;
BA_ "GenSigSNA" SG_ 1297 RCM_a001_eventAccelPedalPos "255";
BA_ "Confidence" SG_ 1297 RCM_a002_eventArmStatus 1;
BA_ "Confidence" SG_ 1297 RCM_a002_eventFactoryMode 1;
BA_ "Confidence" SG_ 1297 RCM_a002_eventDiagEnabled 1;
BA_ "Confidence" SG_ 1297 RCM_a002_eventDriveOrientation 1;
BA_ "Confidence" SG_ 1297 RCM_a002_eventIDFsignal 1;
BA_ "Confidence" SG_ 1297 RCM_a002_eventFrontLeftSeatbelt 1;
BA_ "Confidence" SG_ 1297 RCM_a002_eventFrontRightSeatbelt 1;
BA_ "Confidence" SG_ 1297 RCM_a002_eventVehicleSpeed 1;
BA_ "Confidence" SG_ 1297 RCM_a002_eventSteeringAngle 1;
BA_ "Confidence" SG_ 1297 RCM_a002_eventDriverBrakeApply 1;
BA_ "GenSigSNA" SG_ 1297 RCM_a002_eventDriverBrakeApply "3";
BA_ "Confidence" SG_ 1297 RCM_a002_eventAccelPedalPos 1;
BA_ "GenSigSNA" SG_ 1297 RCM_a002_eventAccelPedalPos "255";
BA_ "Confidence" SG_ 1297 RCM_a003_eventArmStatus 1;
BA_ "Confidence" SG_ 1297 RCM_a003_eventFactoryMode 1;
BA_ "Confidence" SG_ 1297 RCM_a003_eventDiagEnabled 1;
BA_ "Confidence" SG_ 1297 RCM_a003_eventDriveOrientation 1;
BA_ "Confidence" SG_ 1297 RCM_a003_eventIDFsignal 1;
BA_ "Confidence" SG_ 1297 RCM_a003_eventFrontLeftSeatbelt 1;
BA_ "Confidence" SG_ 1297 RCM_a003_eventFrontRightSeatbelt 1;
BA_ "Confidence" SG_ 1297 RCM_a003_eventVehicleSpeed 1;
BA_ "Confidence" SG_ 1297 RCM_a003_eventSteeringAngle 1;
BA_ "Confidence" SG_ 1297 RCM_a003_eventDriverBrakeApply 1;
BA_ "GenSigSNA" SG_ 1297 RCM_a003_eventDriverBrakeApply "3";
BA_ "Confidence" SG_ 1297 RCM_a003_eventAccelPedalPos 1;
BA_ "GenSigSNA" SG_ 1297 RCM_a003_eventAccelPedalPos "255";
BA_ "Confidence" SG_ 1297 RCM_a004_eventArmStatus 1;
BA_ "Confidence" SG_ 1297 RCM_a004_eventFactoryMode 1;
BA_ "Confidence" SG_ 1297 RCM_a004_eventDiagEnabled 1;
BA_ "Confidence" SG_ 1297 RCM_a004_eventDriveOrientation 1;
BA_ "Confidence" SG_ 1297 RCM_a004_eventIDFsignal 1;
BA_ "Confidence" SG_ 1297 RCM_a004_eventFrontLeftSeatbelt 1;
BA_ "Confidence" SG_ 1297 RCM_a004_eventFrontRightSeatbelt 1;
BA_ "Confidence" SG_ 1297 RCM_a004_eventVehicleSpeed 1;
BA_ "Confidence" SG_ 1297 RCM_a004_eventSteeringAngle 1;
BA_ "Confidence" SG_ 1297 RCM_a004_eventDriverBrakeApply 1;
BA_ "GenSigSNA" SG_ 1297 RCM_a004_eventDriverBrakeApply "3";
BA_ "Confidence" SG_ 1297 RCM_a004_eventAccelPedalPos 1;
BA_ "GenSigSNA" SG_ 1297 RCM_a004_eventAccelPedalPos "255";
BA_ "Confidence" SG_ 1297 RCM_a005_eventArmStatus 1;
BA_ "Confidence" SG_ 1297 RCM_a005_eventFactoryMode 1;
BA_ "Confidence" SG_ 1297 RCM_a005_eventDiagEnabled 1;
BA_ "Confidence" SG_ 1297 RCM_a005_eventDriveOrientation 1;
BA_ "Confidence" SG_ 1297 RCM_a005_eventIDFsignal 1;
BA_ "Confidence" SG_ 1297 RCM_a005_eventFrontLeftSeatbelt 1;
BA_ "Confidence" SG_ 1297 RCM_a005_eventFrontRightSeatbelt 1;
BA_ "Confidence" SG_ 1297 RCM_a005_eventVehicleSpeed 1;
BA_ "Confidence" SG_ 1297 RCM_a005_eventSteeringAngle 1;
BA_ "Confidence" SG_ 1297 RCM_a005_eventDriverBrakeApply 1;
BA_ "GenSigSNA" SG_ 1297 RCM_a005_eventDriverBrakeApply "3";
BA_ "Confidence" SG_ 1297 RCM_a005_eventAccelPedalPos 1;
BA_ "GenSigSNA" SG_ 1297 RCM_a005_eventAccelPedalPos "255";
BA_ "Confidence" SG_ 1297 RCM_a006_eventArmStatus 1;
BA_ "Confidence" SG_ 1297 RCM_a006_eventFactoryMode 1;
BA_ "Confidence" SG_ 1297 RCM_a006_eventDiagEnabled 1;
BA_ "Confidence" SG_ 1297 RCM_a006_eventDriveOrientation 1;
BA_ "Confidence" SG_ 1297 RCM_a006_eventIDFsignal 1;
BA_ "Confidence" SG_ 1297 RCM_a006_eventFrontLeftSeatbelt 1;
BA_ "Confidence" SG_ 1297 RCM_a006_eventFrontRightSeatbelt 1;
BA_ "Confidence" SG_ 1297 RCM_a006_eventVehicleSpeed 1;
BA_ "Confidence" SG_ 1297 RCM_a006_eventSteeringAngle 1;
BA_ "Confidence" SG_ 1297 RCM_a006_eventDriverBrakeApply 1;
BA_ "GenSigSNA" SG_ 1297 RCM_a006_eventDriverBrakeApply "3";
BA_ "Confidence" SG_ 1297 RCM_a006_eventAccelPedalPos 1;
BA_ "GenSigSNA" SG_ 1297 RCM_a006_eventAccelPedalPos "255";
BA_ "Confidence" SG_ 1297 RCM_a008_eventArmStatus 1;
BA_ "Confidence" SG_ 1297 RCM_a008_eventFactoryMode 1;
BA_ "Confidence" SG_ 1297 RCM_a008_eventDiagEnabled 1;
BA_ "Confidence" SG_ 1297 RCM_a008_eventDriveOrientation 1;
BA_ "Confidence" SG_ 1297 RCM_a008_eventIDFsignal 1;
BA_ "Confidence" SG_ 1297 RCM_a008_eventFrontLeftSeatbelt 1;
BA_ "Confidence" SG_ 1297 RCM_a008_eventFrontRightSeatbelt 1;
BA_ "Confidence" SG_ 1297 RCM_a008_eventVehicleSpeed 1;
BA_ "Confidence" SG_ 1297 RCM_a008_eventSteeringAngle 1;
BA_ "Confidence" SG_ 1297 RCM_a008_eventDriverBrakeApply 1;
BA_ "GenSigSNA" SG_ 1297 RCM_a008_eventDriverBrakeApply "3";
BA_ "Confidence" SG_ 1297 RCM_a008_eventAccelPedalPos 1;
BA_ "GenSigSNA" SG_ 1297 RCM_a008_eventAccelPedalPos "255";
BA_ "Confidence" SG_ 1297 RCM_a009_eventArmStatus 1;
BA_ "Confidence" SG_ 1297 RCM_a009_eventFactoryMode 1;
BA_ "Confidence" SG_ 1297 RCM_a009_eventDiagEnabled 1;
BA_ "Confidence" SG_ 1297 RCM_a009_eventDriveOrientation 1;
BA_ "Confidence" SG_ 1297 RCM_a009_eventIDFsignal 1;
BA_ "Confidence" SG_ 1297 RCM_a009_eventFrontLeftSeatbelt 1;
BA_ "Confidence" SG_ 1297 RCM_a009_eventFrontRightSeatbelt 1;
BA_ "Confidence" SG_ 1297 RCM_a009_eventVehicleSpeed 1;
BA_ "Confidence" SG_ 1297 RCM_a009_eventSteeringAngle 1;
BA_ "Confidence" SG_ 1297 RCM_a009_eventDriverBrakeApply 1;
BA_ "GenSigSNA" SG_ 1297 RCM_a009_eventDriverBrakeApply "3";
BA_ "Confidence" SG_ 1297 RCM_a009_eventAccelPedalPos 1;
BA_ "GenSigSNA" SG_ 1297 RCM_a009_eventAccelPedalPos "255";
BA_ "Confidence" SG_ 1297 RCM_a011_eventArmStatus 1;
BA_ "Confidence" SG_ 1297 RCM_a011_eventFactoryMode 1;
BA_ "Confidence" SG_ 1297 RCM_a011_eventDiagEnabled 1;
BA_ "Confidence" SG_ 1297 RCM_a011_eventDriveOrientation 1;
BA_ "Confidence" SG_ 1297 RCM_a011_eventIDFsignal 1;
BA_ "Confidence" SG_ 1297 RCM_a011_eventFrontLeftSeatbelt 1;
BA_ "Confidence" SG_ 1297 RCM_a011_eventFrontRightSeatbelt 1;
BA_ "Confidence" SG_ 1297 RCM_a011_eventVehicleSpeed 1;
BA_ "Confidence" SG_ 1297 RCM_a011_eventSteeringAngle 1;
BA_ "Confidence" SG_ 1297 RCM_a011_eventDriverBrakeApply 1;
BA_ "GenSigSNA" SG_ 1297 RCM_a011_eventDriverBrakeApply "3";
BA_ "Confidence" SG_ 1297 RCM_a011_eventAccelPedalPos 1;
BA_ "GenSigSNA" SG_ 1297 RCM_a011_eventAccelPedalPos "255";
BA_ "Confidence" SG_ 1297 RCM_a012_eventArmStatus 1;
BA_ "Confidence" SG_ 1297 RCM_a012_eventFactoryMode 1;
BA_ "Confidence" SG_ 1297 RCM_a012_eventDiagEnabled 1;
BA_ "Confidence" SG_ 1297 RCM_a012_eventDriveOrientation 1;
BA_ "Confidence" SG_ 1297 RCM_a012_eventIDFsignal 1;
BA_ "Confidence" SG_ 1297 RCM_a012_eventFrontLeftSeatbelt 1;
BA_ "Confidence" SG_ 1297 RCM_a012_eventFrontRightSeatbelt 1;
BA_ "Confidence" SG_ 1297 RCM_a012_eventVehicleSpeed 1;
BA_ "Confidence" SG_ 1297 RCM_a012_eventSteeringAngle 1;
BA_ "Confidence" SG_ 1297 RCM_a012_eventDriverBrakeApply 1;
BA_ "GenSigSNA" SG_ 1297 RCM_a012_eventDriverBrakeApply "3";
BA_ "Confidence" SG_ 1297 RCM_a012_eventAccelPedalPos 1;
BA_ "GenSigSNA" SG_ 1297 RCM_a012_eventAccelPedalPos "255";
BA_ "Confidence" SG_ 1297 RCM_a013_eventArmStatus 1;
BA_ "Confidence" SG_ 1297 RCM_a013_eventFactoryMode 1;
BA_ "Confidence" SG_ 1297 RCM_a013_eventDiagEnabled 1;
BA_ "Confidence" SG_ 1297 RCM_a013_eventDriveOrientation 1;
BA_ "Confidence" SG_ 1297 RCM_a013_eventIDFsignal 1;
BA_ "Confidence" SG_ 1297 RCM_a013_eventFrontLeftSeatbelt 1;
BA_ "Confidence" SG_ 1297 RCM_a013_eventFrontRightSeatbelt 1;
BA_ "Confidence" SG_ 1297 RCM_a013_eventVehicleSpeed 1;
BA_ "Confidence" SG_ 1297 RCM_a013_eventSteeringAngle 1;
BA_ "Confidence" SG_ 1297 RCM_a013_eventDriverBrakeApply 1;
BA_ "GenSigSNA" SG_ 1297 RCM_a013_eventDriverBrakeApply "3";
BA_ "Confidence" SG_ 1297 RCM_a013_eventAccelPedalPos 1;
BA_ "GenSigSNA" SG_ 1297 RCM_a013_eventAccelPedalPos "255";
BA_ "Confidence" SG_ 1297 RCM_a014_eventArmStatus 1;
BA_ "Confidence" SG_ 1297 RCM_a014_eventFactoryMode 1;
BA_ "Confidence" SG_ 1297 RCM_a014_eventDiagEnabled 1;
BA_ "Confidence" SG_ 1297 RCM_a014_eventDriveOrientation 1;
BA_ "Confidence" SG_ 1297 RCM_a014_eventIDFsignal 1;
BA_ "Confidence" SG_ 1297 RCM_a014_eventFrontLeftSeatbelt 1;
BA_ "Confidence" SG_ 1297 RCM_a014_eventFrontRightSeatbelt 1;
BA_ "Confidence" SG_ 1297 RCM_a014_eventVehicleSpeed 1;
VAL_ 2047 GTW_deliveryStatus 1 "DELIVERED" 0 "NOT_DELIVERED" ;
VAL_ 2047 GTW_cabinPTCHeaterType 1 "NONE" 0 "BORGWARNER" ;
VAL_ 2047 GTW_rightHandDrive 1 "RIGHT" 0 "LEFT" ;
VAL_ 2047 GTW_rearLightType 2 "GLOBAL" 1 "EU_CN" 0 "NA" ;
VAL_ 2047 GTW_headlamps 2 "GLOBAL" 1 "PREMIUM" 0 "BASE" ;
VAL_ 2047 GTW_tireType 38 "HANKOOK_SUMMER_18" 37 "GITI_SUMMER_18" 36 "KUMHO_ALL_SEASON_18" 35 "GOODYEAR_ALL_SEASON_18" 34 "CONTI_SUMMER_19" 33 "BRIDGESTONE_ALL_SEASON_20" 32 "HANKOOK_ALL_SEASON_20" 31 "GOODYEAR_SUMMER_19" 30 "KUMHO_ALL_SEASON_19" 29 "HANKOOK_ALL_SEASON_21" 28 "PIRELLI_ALL_SEASON_19" 27 "GOODYEAR_ALL_SEASON_21" 26 "HANKOOK_ALL_SEASON_18" 25 "PIRELLI_ALL_SEASON_22" 24 "CONTI_SUMMER_22" 23 "CONTI_ALL_SEASON_20" 22 "MICHELIN_SUMMER_21" 21 "PIRELLI_SUMMER_20" 20 "PIRELLI_SUMMER_19" 19 "MICHELIN_ALL_SEASON_21" 18 "PIRELLI_SUMMER_21" 17 "GOODYEAR_ALL_SEASON_20" 16 "BRIDGESTONE_SUMMER_18" 7 "GOODYEAR_ALL_TERRAIN_20" 6 "PIRELLI_ALL_SEASON_20" 5 "MICHELIN_SUMMER_20" 4 "CONTI_ALL_SEASON_19" 3 "HANKOOK_SUMMER_19" 2 "MICHELIN_SUMMER_18" 1 "MICHELIN_ALL_SEASON_18" 0 "UNKNOWN" ;
VAL_ 2047 GTW_dasHw 5 "TESLA_AP4" 4 "TESLA_AP3" 3 "PARKER_PASCAL_2_5" ;
VAL_ 2047 GTW_brakeHWType 21 "HITACHI_P42_V2_MANDO_43MOC_LOW_DRAG" 20 "BREMBO_LARGE_P42_V2_MANDO_43MOC_LOW_DRAG" 18 "BREMBO_LARGE_P42_V2_BREMBO_44MOC_GA" 17 "HITACHI_P42_V2_MANDO_43MOC" 16 "BREMBO_P42LD_V2_MANDO_43MOC" 15 "BREMBO_P42LD_ZF_43MOC" 13 "BREMBO_P42_ZF_43MOC" 9 "BREMBO_P42_V2_MANDO_43MOC" 8 "BREMBO_LARGE_P42_V2_MANDO_43MOC" 7 "BREMBO_LARGE_P42_V2_BREMBO_LARGE_44MOC" 6 "BREMBO_LARGE_P42_V2_BREMBO_44MOC" 3 "BREMBO_LARGE_P42_BREMBO_LARGE_44MOC" 2 "BREMBO_LARGE_P42_MANDO_43MOC" 1 "BREMBO_LARGE_P42_BREMBO_44MOC" 0 "BREMBO_P42_MANDO_43MOC" ;
VAL_ 2047 GTW_restraintsHardwareType 239 "NA_NO_KAB_MYB" 238 "ROW_ECALL_E41_MYB" 237 "EU_ECALL_E41_MYB" 236 "NA_E41_MYB" 233 "NA_MYL" 232 "ECE_ECALL_PEDPRO_MYL" 89 "ROW_ECALL_PEDPRO_MYL" 88 "ROW_PEDPRO_MYB" 87 "ROW_PERF_ECALL_PEDPRO_MYB" 86 "EU_PERF_ECALL_PEDPRO_MYB" 85 "EU_ECALL_PEDPRO_MYB" 84 "ROW_ECALL_PEDPRO_MYB" 83 "ROW_MYB" 82 "ROW_ECALL_MYB" 81 "NA_MYB" ;
VAL_ 2047 GTW_drivetrainType 1 "AWD" 0 "RWD" ;
VAL_ 2047 GTW_radarHeaterType 1 "MODELY_BACKER_THIN_3M" 0 "NONE" ;
VAL_ 2047 GTW_exteriorTrimType 1 "SATIN_BLACK" 0 "STANDARD_CHROME" ;
VAL_ 2047 GTW_frontSeatHeaters 1 "KONGSBERG_LOW_POWER" 0 "NONE" ;
VAL_ 2047 GTW_rearSeatHeaters 1 "KONGSBERG_LOW_POWER" 0 "NONE" ;
VAL_ 2047 GTW_eCallAntennaHW 1 "MAIN_ANT_ONLY" 0 "BACKUP_OR_MAIN_ANT" ;
VAL_ 2047 GTW_homelinkType 1 "HOMELINK_V_OPT_2" 0 "NONE" ;
VAL_ 2047 GTW_vdcType 1 "TESLA_VDC" 0 "BOSCH_VDC" ;
VAL_ 2047 GTW_memoryMirrors 1 "SMR" 0 "NOT_INSTALLED" ;
VAL_ 2047 GTW_powerLiftgateType 2 "HUADE_REV1" 1 "TESLA_REV1" 0 "NOT_INSTALLED" ;
VAL_ 2047 GTW_lumbarECUType 10 "AEW_SINGLE_AXIS_DRIVER_ONLY_RHD" 9 "AEW_SINGLE_AXIS_DRIVER_ONLY_LHD" 8 "ND_DRIVER_ONLY_RHD" 7 "ND_DRIVER_ONLY_LHD" 6 "AEW_DRIVER_ONLY_RHD" 5 "AEW_DRIVER_ONLY_LHD" 4 "AEW" 3 "ALFMEIER_DRIVER_ONLY_RHD" 2 "ALFMEIER_DRIVER_ONLY_LHD" 1 "ALFMEIER" 0 "NONE" ;
VAL_ 2047 GTW_rearSeatHeaterType 3 "LEFT_RIGHT_ONLY_GENTHERM" 2 "NONE" 1 "LEFT_RIGHT_ONLY_KONGSBERG" ;
VAL_ 2047 GTW_auxParkLamps 3 "NONE" 2 "EU" 1 "NA_PREMIUM" 0 "NA_BASE" ;
VAL_ 2047 GTW_interiorCabinRadarType 1 "TESLA" 0 "NONE" ;
VAL_ 2047 GTW_hvacPanelVaneType 1 "CONVERGENT_V1" 0 "PARALLEL_V1" ;
VAL_ 2047 GTW_intakeAirFilterType 1 "HEPA" 0 "STANDARD" ;
VAL_ 2047 GTW_eBuckConfig 1 "DEV_BUCK" 0 "NONE" ;
VAL_ 2047 GTW_steeringHeaterEnabled 1 "ENABLED" 0 "DISABLED" ;
VAL_ 2047 GTW_activeHighBeam 1 "ACTIVE" 0 "NOT_ACTIVE" ;
VAL_ 2047 GTW_airbagCutoffSwitch 1 "CUTOFF_SWITCH_ENABLED" 0 "CUTOFF_SWITCH_DISABLED" ;
VAL_ 2047 GTW_intrusionSensorType 1 "VODAFONE" 0 "NOT_INSTALLED" ;
VAL_ 2047 GTW_spoilerType 1 "PASSIVE" 0 "NOT_INSTALLED" ;
VAL_ 2047 GTW_backupCameraType 1 "INTEGRATED_HEATER_V1" 0 "NO_HEATER" ;
VAL_ 2047 GTW_rearFogLamps 1 "INSTALLED" 0 "NOT_INSTALLED" ;
VAL_ 2047 GTW_roofType 1 "FIXED_GLASS" ;
VAL_ 2047 GTW_thirdRowSeatType 1 "FLAT_FOLD" 0 "NONE" ;
VAL_ 2047 GTW_autopilot 4 "BASIC" 3 "SELF_DRIVING" 2 "ENHANCED" 1 "HIGHWAY" 0 "NONE" ;
VAL_ 2047 GTW_superchargingAccess 2 "PAY_AS_YOU_GO" 1 "ALLOWED" 0 "NOT_ALLOWED" ;
VAL_ 2047 GTW_exteriorColor 20 "COASTAL_BLUE" 17 "MARINE_BLUE" 16 "SILKROAD_SILVER" 15 "DIAMOND_BLACK" 14 "GLACIER_BLUE" 13 "FROST_BLUE" 11 "STEALTH_GREY" 10 "ULTRA_RED" 9 "QUICKSILVER" 8 "ABYSS_BLUE" 7 "MIDNIGHT_CHERRY_RED" 6 "PEARL_WHITE" 5 "DEEP_BLUE" 3 "MIDNIGHT_SILVER" 2 "SILVER_METALLIC" 1 "SOLID_BLACK" 0 "RED_MULTICOAT" ;
VAL_ 2047 GTW_pedestrianWarningSound 2 "EXT_SPEAKER_V2" 1 "SPEAKER" 0 "NONE" ;
VAL_ 2047 GTW_steeringColumnUJointType 1 "C_SAMPLE_PHASING" ;
VAL_ 2047 GTW_bPillarNFCParam 1 "MODEL_Y" 0 "MODEL_3" ;
VAL_ 2047 GTW_interiorLighting 6 "FOOTWELL" 5 "FOOTWELL_RGB_IP" 4 "PREMIUM_WITH_RGB_IP_ONLY" 3 "PREMIUM_WITH_RGB" 2 "PREMIUM_NO_POCKET_LIGHT" 1 "PREMIUM" 0 "BASE" ;
VAL_ 2047 GTW_headlightLevelerType 2 "VIRTUAL_PITCH_SENSOR" 1 "GEN1" 0 "NONE" ;
VAL_ 2047 GTW_numberHVILNodes 3 "HVIL_NODES_3" 2 "HVIL_NODES_2" 0 "HVIL_NODES_0" ;
VAL_ 2047 GTW_mapRegion 13 "LA" 12 "IN" 11 "SE" 10 "MO" 9 "HK" 8 "ME" 7 "KR" 6 "TW" 5 "JP" 4 "AU" 3 "CN" 2 "NONE" 1 "EU" 0 "US" ;
VAL_ 2047 GTW_performancePackage 4 "BASE_2022" 3 "BASE_PLUS" 2 "BASE_2024" 1 "PERFORMANCE" 0 "BASE" ;
VAL_ 2047 GTW_chassisType 7 "MODEL_Y_LONG_WHEELBASE_CHASSIS_PATRONUS" 3 "MODEL_Y_CHASSIS" 2 "MODEL_3_CHASSIS" ;
VAL_ 2047 GTW_airSuspension 3 "COIL_ADAPTIVE_DAMPING" 0 "NONE" ;
VAL_ 2047 GTW_centerConsoleControllerType 2 "INSTALLED_NO_AIRWAVE" 1 "INSTALLED_V1" 0 "NONE" ;
VAL_ 2047 GTW_autopilotCameraType 1 "RGGB_CAMERAS" 0 "RCCB_CAMERAS" ;
VAL_ 2047 GTW_connectivityPackage 1 "PREMIUM" 0 "BASE" ;
VAL_ 2047 GTW_plcSupportType 2 "NATIVE_CHARGE_PORT" 1 "ONBOARD_ADAPTER" 0 "NONE" ;
VAL_ 2047 GTW_badgingVersion 2 "VERSION_2" 1 "VERSION_1" 0 "VERSION_0" ;
VAL_ 2047 GTW_packEnergy 2 "MR" 1 "LR" 0 "SR" ;
VAL_ 2047 GTW_frontSeatReclinerHardware 3 "LEFT_RIGHT_SEAT_REDUCED_RANGE" 2 "LEFT_SEAT_REDUCED_RANGE" 1 "RIGHT_SEAT_REDUCED_RANGE" 0 "STANDARD_RANGE" ;
VAL_ 2047 GTW_brakeLineSwitchType 1 "VC_ONLY" 0 "DI_VC_SHARED" ;
VAL_ 2047 GTW_espValveType 2 "VALVE_TYPE_2" 1 "VALVE_TYPE_1" 0 "UNKNOWN" ;
VAL_ 2047 GTW_softRange 4 "RANGE_260_MILES" 3 "RANGE_343_MILES" 2 "RANGE_93_MILES" 1 "RANGE_220_MILES" 0 "STANDARD" ;
VAL_ 2047 GTW_refrigerantType 2 "R1234YF" 1 "R134A" 0 "Default" ;
VAL_ 2047 GTW_wheelType 52 "UBERHELIX_20" 51 "GEMINI_19_DARK_STAGGERED" 50 "HELIX_V2_20_DARK" 48 "MACHINA_V2_19_STAGGERED" 47 "GLIDER_18_CAP_KIT" 46 "APERTURE_18" 41 "ARACHNID_V2_21" 40 "HELIX_V2_20" 39 "CROSSFLOW_19" 33 "WISHBONE_20_STAGGERED" 31 "HELIX_19" 30 "GLIDER_18" 27 "ZEROG_19_GUNPOWDER" 24 "PINWHEEL_REFRESH_18_CAP_KIT" 23 "UBERTURBINE_20_GUNPOWDER" 22 "PINWHEEL_REFRESH_18" 21 "STILETTO_REFRESH_19" 19 "ZEROG_20_GUNPOWDER" 18 "PINWHEEL_18_CAP_KIT" 14 "STILETTO_20_DARK_SQUARE" 5 "GEMINI_19_STAGGERED" 4 "GEMINI_19_SQUARE" 3 "STILETTO_20_DARK_STAGGERED" 2 "STILETTO_20" 1 "STILETTO_19" 0 "PINWHEEL_18" ;
VAL_ 2047 GTW_ptcControlMode 3 "SEQ_ROD_LIMITED" 2 "MESH_INSTALLED" 1 "SEQ_ROD" 0 "BASELINE" ;
VAL_ 2047 GTW_brakeActuationType 2 "ESP_DPB" 1 "IDB_RCU" 0 "ESP_IBST" ;
VAL_ 2047 GTW_secondRowSeatType 6 "TWO_SEATS_POWERED_RECLINE" 5 "FLAT_FOLD_V2" 4 "EASY_ENTRY_POWERED_RECLINE" 3 "POWERED_RECLINE" ;
VAL_ 2047 GTW_secondRowSeatMotorType 1 "KEIPER" 0 "SHB" ;
VAL_ 2047 GTW_eCallEnabled 2 "ENABLED_UI_SOS" 1 "ENABLED_OHC_SOS" 0 "DISABLED" ;
VAL_ 2047 GTW_parkAssistECUType 2 "NONE" 1 "TESLA" 0 "VALEO" ;
VAL_ 2047 GTW_passengerAirbagType 2 "EUROW" 1 "SAFETY_VENT" 0 "FULL_SUPPRESSION" ;
VAL_ 2047 GTW_forwardRadarHw 2 "NONE" 0 "CONTI_ARS410" ;
VAL_ 2047 GTW_frontSeatType 13 "PREMIUM_L_YANFENG_MINITILT_R_TESLA_MINITILT" 12 "PREMIUM_L_YANFENG_MINITILT_R_YANFENG_MINITILT" 11 "PREMIUM_L_YANFENG_MINITILT_R_YANFENG" 10 "PREMIUM_L_YANFENG_R_YANFENG_MINITILT" 9 "PREMIUM_L_TESLA_MINITILT_R_YANFENG_MINITILT" 8 "PREMIUM_L_TESLA_MINITILT_R_TESLA_MINITILT" 7 "PREMIUM_L_TESLA_MINITILT_R_TESLA" 6 "PREMIUM_L_TESLA_R_TESLA_MINITILT" 5 "PREMIUM_BROSE" 4 "PREMIUM_YANFENG" 3 "PREMIUM_L_TESLA_R_YANFENG" 2 "PREMIUM_L_YANFENG_R_TESLA" 1 "PREMIUM_TESLA" 0 "BASE_TESLA" ;
VAL_ 2047 GTW_secondRowDisplayType 1 "TYPE_1" 0 "NONE" ;
VAL_ 2047 GTW_wirelessPhoneChargerType 3 "FRONT_HIGH_POWER_UART" 1 "FRONT_LIN" 0 "NONE_OR_USB" ;
VAL_ 2047 GTW_ethernetTunerType 3 "HARMAN_GEN3" 2 "HIRSCHMANN" 1 "NONE" 0 "HARMAN" ;
VAL_ 2047 GTW_interiorTrimType 3 "WHITE_CONSOLE_2" 2 "BLACK_CONSOLE_2" 1 "WHITE" 0 "BLACK" ;
VAL_ 2047 GTW_gloveboxUSBType 2 "TSC_USB3_A_PLUS_BT" 1 "TSC_USB3_A" 0 "NOT_INSTALLED" ;
VAL_ 2047 GTW_coolantPumpType 5 "DUAL_MIX" 4 "DUAL_SAN_P4_LUB" 2 "DUAL_SAN_P4" 1 "SINGLE_PUMP_BATT" 0 "DUAL" ;
VAL_ 2047 GTW_epblHwType 8 "ZF" 5 "BREMBO_V2" 4 "BREMBO_V1" 2 "MANDO_V2" 1 "MANDO_V1" 0 "NOT_SET" ;
VAL_ 2047 GTW_epbrHwType 8 "ZF" 5 "BREMBO_V2" 4 "BREMBO_V1" 2 "MANDO_V2" 1 "MANDO_V1" 0 "NOT_SET" ;
VAL_ 2047 GTW_blowerMotorType 1 "DELTA" 0 "SHINANO" ;
VAL_ 2047 GTW_rearLeftBLEEndpointParameter 1 "VIVALDI_ANTENNA" 0 "NONE" ;
VAL_ 2047 GTW_powerMirrorFoldType 1 "TYPE_1" 0 "NOT_INSTALLED" ;
VAL_ 2047 GTW_frontUsbHubType 4 "NO_DATA" 0 "2" ;
VAL_ 2047 GTW_superManifoldType 2 "TYPE2" 1 "TYPE1" 0 "TYPE0" ;
VAL_ 2047 GTW_rcmLocation 0 "CENTER_CONSOLE" ;
VAL_ 2047 GTW_autopilotExteriorCameraType 1 "IMX00N" 0 "DEFAULT_FOR_APHW" ;
VAL_ 2047 GTW_interiorCamBeautyCoverType 2 "PITCHED_DOWN" 1 "PITCHED_UP" 0 "STANDARD" ;
VAL_ 2047 GTW_sirenType 1 "VODAPHONE_IF_INTRUSION" 0 "NONE" ;
VAL_ 2047 GTW_hornType 1 "EXT_SPEAKER_V2" 0 "TRUMPET" ;
VAL_ 2047 GTW_passengerTrackMotorType 1 "L_AND_V" 0 "INSTALLED_DEFAULT" ;
VAL_ 2047 GTW_steeringColumnMotorType 3 "NEXTEER" 2 "BOSCH_COMMON_TO_JE" 1 "JE" 0 "BOSCH" ;
VAL_ 2047 GTW_refrigACLineType 2 "CONTI_LIMITED" 1 "SAAA_LIMITED" 0 "UNLIMITED" ;
VAL_ 2047 GTW_refrigFilterType 2 "BLOCKED_V2" 1 "BLOCKED_V1" 0 "UNBLOCKED" ;
VAL_ 2047 GTW_diBurnInType 1 "ENABLED_V1" 0 "NONE" ;
VAL_ 2047 GTW_specialBadgingType 2 "LAUNCH_SERIES" 0 "NONE" ;
VAL_ 2047 GTW_chassisSubType 4 "MARKET_VARIANT_2" 3 "TRIM_DEVIATION_1" 2 "PERFORMANCE" 1 "BASE" 0 "UNKNOWN" ;
VAL_ 2047 GTW_towPackage 2 "TESLA_REV2" 1 "TESLA_REV1" 0 "NONE" ;
VAL_ 2047 GTW_refrigLccType 1 "LCCR" 0 "LCC" ;
VAL_ 2047 GTW_restraintControlsType 1 "TESLA" 0 "BOSCH" ;
VAL_ 2047 GTW_caliperColorType 2 "RED" 1 "GREY" 0 "UNKNOWN" ;
VAL_ 2047 GTW_wiperMotorType 1 "SHB" 0 "NOT_UPDATEABLE" ;
VAL_ 2047 GTW_frontOverheadConsoleType 3 "KOSTAL" 2 "PREH" 1 "BITRON" 0 "VALEO" ;
VAL_ 2047 GTW_shifterType 1 "DISPLAY" 0 "STALK" ;
VAL_ 2047 GTW_compressorType 10 "SANDEN_V4_1" 8 "SANDEN_V4" 7 "SANDEN_V3" 6 "SANDEN_V1_1" 5 "SANDEN_V2" 4 "DENSO_11K_COP1_ENABLED" 3 "SANDEN" 2 "DENSO_41CC_11K" 1 "DENSO_41CC_8K" 0 "HANON_33CC" ;
VAL_ 2047 GTW_twelveVBatteryType 3 "TESLA_16V_LI_ION" 2 "CATL_LI_ION" 1 "CLARIOS_B24_FLOODED" 0 "ATLASBX_B24_FLOODED" ;
VAL_ 2047 GTW_efuseSWConfig 3 "ALL_ENABLED" 2 "SQUARE_ENABLED" 1 "ROUND_ENABLED" 0 "DISABLED" ;
VAL_ 2047 GTW_tollCollectionModuleType 1 "WANJI_V1" 0 "NONE" ;
VAL_ 2047 GTW_bleEndpointUpdateMethod 1 "BOOTLOADER_UPDATE" ;
VAL_ 2047 GTW_steeringWheelControllerType 5 "DUAL_TESLA_GEN5" 2 "DUAL_KOSTAL" 1 "DUAL_PREH" ;
VAL_ 2047 GTW_frontSeatVentilationEnabled 1 "ENABLED" 0 "DISABLED" ;
VAL_ 2047 GTW_gloveboxActuatorType 2 "ELECTROMAGNET" 1 "SMA" 0 "SOLENOID" ;
VAL_ 2047 GTW_epasType 8 "THYSSENKRUPP_CGR65" 7 "MANDO_CGR65" 6 "THYSSENKRUPP_VGR69" 5 "MANDO_CGR69_SINGLE_ECU" 4 "MANDO_CGR69" 3 "MANDO_VGR69_GEN3_SINGLE_ECU" 0 "MANDO_VGR69_GEN3" ;
VAL_ 2047 GTW_homologationRegionOverride 2 "MX_UNECE" 1 "KR_UNECE" 0 "DEFAULT_FOR_COUNTRY_CODE" ;
VAL_ 2047 GTW_windowCommandsPermissionType 2 "US_FMVSS_S6" 1 "US_FMVSS_S4" 0 "ROW_OR_US_FMVSS_S5" ;
VAL_ 2047 GTW_headlightStepperStallDetectM 1 "ENABLED" 0 "DISABLED" ;
VAL_ 2047 GTW_rgbInteriorLightingEnabled 2 "ALL_COLORS" 1 "WHITE_ONLY" 0 "DISABLED_OR_NA" ;
VAL_ 2047 GTW_windshieldWiperHeaterType 1 "TYPE_1" 0 "NOT_INSTALLED" ;
VAL_ 2047 GTW_thirdRowSeatReclinerType 1 "POWERED_SHB" 0 "MANUAL_OR_NA" ;
VAL_ 2047 GTW_driveInterfaceType 1 "EXTERNAL" 0 "COMBINED" ;
VAL_ 2047 GTW_efficiencyPackage 42 "MY_2026_US" 39 "MY_2025_CN_PLUS" 38 "MY_2026_M53" 34 "MY_STANDARD_2026" 33 "MY_REFRESH_2025_CN_ALL_US_LR_RWD" 32 "MY_REFRESH_2025_ROW" 24 "MY_2024_GFSH_EXPORT_NA_SR_RWD" 23 "MY_2024C" 20 "MY_2023_SR_RWD" 16 "MY_2024" 15 "MY_2023_GFSH_EXPORT_NA" 12 "MY_RWD_EU_2022" 11 "MY_SR_PLUS_2022_Q1_TX" 9 "MY_SR_PLUS_2021_Q3_GFSH" 7 "MY_2021" 5 "MY_2020" 0 "DEFAULT" ;
VAL_ 2047 GTW_visorLightType 1 "DIMMABLE_TYPE_1" 0 "NON_DIMMABLE" ;
VAL_ 2047 GTW_gnssAntennaType 2 "GEN2_WITH_METAL_INSERT" 1 "GEN2_NO_METAL_INSERT" 0 "NA_OR_GEN1" ;
VAL_ 2047 GTW_airDistributionBoxType 1 "TYPE_1" 0 "NONE" ;
VAL_ 2047 GTW_frontSeatHeatersEnabled 1 "ENABLED" 0 "DISABLED" ;
VAL_ 2047 GTW_windshieldWiperHeaterEnabled 1 "ENABLED_OR_NA" 0 "DISABLED" ;
VAL_ 2047 GTW_alcoholInterlockType 1 "TYPE_1" 0 "NONE" ;
VAL_ 2047 GTW_fasciaType 8 "E41_BAYBERRY" 4 "PERFORMANCE_BAYBERRY" 3 "BASE_BAYBERRY" 0 "ORIGINAL" ;
VAL_ 2047 GTW_powerSteeringColumn 1 "TK" 0 "NOT_INSTALLED" ;
VAL_ 2047 GTW_frontSeatHeaterType 1 "GENTHERM" 0 "KONGSBERG" ;
VAL_ 2047 GTW_softPerformanceLimit 6 "LIMIT_230_KW" 4 "LIMIT_110_MPH" 2 "LIMIT_110_KW" 1 "LIMIT_160_KW" 0 "NONE" ;
VAL_ 2047 GTW_gsrFeatureType 2 "TYPE_2_GSR" 0 "NONE" ;
VAL_ 2047 GTW_immersiveAudio 2 "PREMIUM" 1 "BASE" 0 "DISABLED" ;
VAL_ 2047 GTW_frontSeatVentilationType 1 "TYPE_1" 0 "NONE" ;
VAL_ 2047 GTW_passengerOccupancySensorType 4 "NONE" 1 "RESISTIVE_PAD" 0 "OCS" ;
VAL_ 2047 GTW_packPerformanceDeviation 5 "PACK_POWER_DEVIATION_2" 4 "PACK_MASS_DEVIATION_2" 3 "PACK_STRUCTURAL_DEVIATION_1" 2 "PACK_POWER_DEVIATION_1" 1 "PACK_MASS_DEVIATION_1" 0 "NO_DEVIATION" ;
VAL_ 2047 GTW_pressurePadType 3 "BOSCH_LINDA_300N" 2 "BOSCH_B2_400N" 1 "BOSCH_B2_300N" 0 "NONE" ;
VAL_ 2047 GTW_frontFogLamps 1 "INSTALLED" 0 "NOT_INSTALLED" ;
VAL_ 2047 GTW_driverOccupancySensorType 1 "NONE" 0 "RESISTIVE_PAD" ;
VAL_ 2047 GTW_audioType 4 "ESSENTIAL_WITH_COMMODITY100" 3 "ESSENTIAL" 1 "PREMIUM" 0 "BASE" ;
VAL_ 2047 GTW_thighExtenderType 1 "YANFENG" 0 "NONE" ;
VAL_ 2047 GTW_occupancyClassificationFeatu 1 "TESLA_CABIN_RADAR" 0 "DISCRETE_SENSOR_OR_NA" ;
VAL_ 2047 GTW_frontControllerArchitectureT 1 "BETA_TYPE" 0 "ALPHA_TYPE" ;
VAL_ 2047 GTW_domeLightType 3 "2R_3R" 2 "2R" ;
VAL_ 2047 GTW_tpmsType 2 "INDIRECT" 1 "TESLA_BLE" 0 "CONTI_2" ;
VAL_ 2047 GTW_authenticationEndpointLayout 6 "M3_LAYOUT_3" 5 "MY_LAYOUT_3" 2 "MY_LAYOUT_2" 1 "M3_LAYOUT_2" 0 "LAYOUT_1" ;
VAL_ 2047 GTW_socSleepOverride 2 "FORCE_SHALLOW" 1 "FORCE_S3" 0 "PN_DERIVED" ;
VAL_ 2047 GTW_r79BehaviorOverride 1 "R79_ENABLED" 0 "NO_OVERRIDE" ;
VAL_ 2047 GTW_steeringHeaterType 7 "YF_V2" 4 "ZF_ROUND" 0 "NONE" ;
VAL_ 2047 GTW_narrowWipingSupported 1 "SUPPORTED" 0 "NOT_SUPPORTED" ;
VAL_ 2047 GTW_frontSeatHeaterGridType 1 "LARGER_SURFACE_AREA" 0 "STANDARD" ;
VAL_ 2047 GTW_frontSeatSideSwitchType 1 "NONE" 0 "STANDARD" ;
VAL_ 2047 GTW_sohRegulatoryStatus 1 "REGULATED_SOH" 0 "NON_REGULATED_SOH" ;
VAL_ 2047 GTW_passengerTiltMotorType 2 "MINITILT" 1 "NONE" 0 "INSTALLED_DEFAULT" ;
VAL_ 2047 GTW_frunkInteriorReleaseType 1 "NOT_INSTALLED" 0 "TYPE_1" ;
VAL_ 2047 GTW_m3yBusArchitecture 2 "PRIVATE_TORQUE_CHASSIS" 1 "PRIVATE_TORQUE" 0 "PUBLIC_TORQUE" ;
VAL_ 2047 GTW_passengerLiftMotorType 2 "BOSCH_KEIPER_COMMON" 1 "NONE" 0 "INSTALLED_DEFAULT" ;
VAL_ 2047 GTW_interiorUpperTrimType 1 "MAMMOTH_BLACK" 0 "POLAR_GREY" ;
VAL_ 2047 GTW_blindSpotIndicatorLightType 2 "INSTALLED_TYPE_2" 1 "INSTALLED_TYPE_1" 0 "NOT_INSTALLED" ;
VAL_ 2047 GTW_wiperMotorAsicType 2 "TYPE_2" 1 "TYPE_1" 0 "UNKNOWN_OR_NA" ;
VAL_ 2047 GTW_hvacCaseDoorType 1 "FLAT_EDGE" 0 "SERRATED_EDGE" ;
VAL_ 2047 GTW_occupancyDetectionSourceRequ 1 "TESLA_CABIN_RADAR" 0 "DISCRETE_SENSOR_OR_NA" ;
VAL_ 2047 GTW_rduCableType 1 "COPPER" 0 "ALUMINUM" ;
VAL_ 2047 GTW_parkTelltaleBehaviorType 1 "TYPE_1_REVISED_BEHAVIOR" 0 "LEGACY_BEHAVIOR" ;
VAL_ 2047 GTW_numberKeyCardsPairedInFactor 2 "2" 1 "1" ;
VAL_ 2047 GTW_secondRowSeatVentilationType 1 "TWO_SEATS_GENTHERM" 0 "NONE" ;
VAL_ 2047 GTW_thirdRowSeatHeaterType 1 "TWO_SEATS_KONGSBERG" 0 "NONE" ;
VAL_ 2047 GTW_interiorCameraType 2 "VD1942" 1 "VD6763" 0 "AR0136" ;
VAL_ 2047 GTW_frontFasciaCameraType 2 "IMX00N" 1 "IMX963" 0 "NONE" ;
VAL_ 2047 GTW_interiorCamFanType 3 "NIDEC" 2 "DELTA_FDB" 0 "NONE" ;
VAL_ 2047 GTW_puddleLampType 2 "INSTALLED_1R_ONLY_TYPE_1" 1 "INSTALLED_TYPE_1" 0 "NOT_INSTALLED" ;
VAL_ 2047 GTW_solarLensType 1 "PEGATRON" 0 "BCS" ;
VAL_ 2047 GTW_liftgateGeometryType 2 "TYPE_2" 1 "TYPE_1" 0 "DEFAULT" ;
VAL_ 2047 GTW_repeaterAeroRibType 4 "RETROFIT_OPTIMIZED" 3 "OPTIMIZED" 0 "UNOPTIMIZED" ;
VAL_ 2047 GTW_highTipForceWiperArmsType 1 "INSTALLED_TYPE_1" 0 "NOT_INSTALLED" ;
VAL_ 2047 GTW_rcmUndersideAbuseZThreshold 7 "threshold7" 6 "threshold6" 5 "threshold5" 4 "threshold4" 3 "threshold3" 2 "threshold2" 1 "threshold1" 0 "threshold0" ;
VAL_ 2047 GTW_rcmUndersideAbuseYThreshold 7 "threshold7" 6 "threshold6" 5 "threshold5" 4 "threshold4" 3 "threshold3" 2 "threshold2" 1 "threshold1" 0 "threshold0" ;
VAL_ 2047 GTW_rcmUndersideAbuseWindow 3 "window3" 2 "window2" 1 "window1" 0 "window0" ;
VAL_ 2047 GTW_uhfChargePortEnabled 1 "DISABLED" 0 "ENABLED" ;
VAL_ 2047 GTW_automaticFeatureResetPackage 1 "TYPE_1" 0 "NONE" ;
VAL_ 2047 GTW_autopilotFeaturePackage 1 "TACC_AND_FSD_ONLY" 0 "LEGACY_AND_FSD" ;
VAL_ 2047 GTW_doorLatchType 1 "SELF_TESTABLE" 0 "DIGITAL" ;
VAL_ 2047 GTW_headlinerMaterialType 2 "POLYURETHANE_FIBERGLASS_LIGHT" 1 "POLYURETHANE_FIBERGLASS" 0 "POLYCARBONATE_ABS" ;
VAL_ 2047 GTW_glareShieldHeaterType 1 "TYPE_1" 0 "NONE" ;
VAL_ 2047 GTW_rearLightHardwareVariant 2 "V3" 1 "V2" 0 "V1" ;
VAL_ 2047 GTW_fasciaHarnessCleanPointType 2 "POST_CLEANPOINT" 1 "PRE_CLEANPOINT" 0 "UNKOWN" ;
VAL_ 2047 GTW_epasSubType 1 "GEN4" 0 "GEN3_OR_NA" ;
VAL_ 2047 GTW_wiperSupplyChainOrigin 2 "NA_SUPPLY_CHAIN" 1 "CN_SUPPLY_CHAIN" 0 "UNKNOWN_OR_SNA" ;
VAL_ 2047 GTW_windowPinchParameterType 2 "TYPE_2" 1 "TYPE_1" 0 "DEFAULT" ;
VAL_ 2047 GTW_badgingMaterialType 1 "BLACK_MATTE" 0 "CHROME_SILVER" ;
VAL_ 2047 GTW_mRecordVersion 1 "VER_2025" 0 "VER_2016_OR_NA" ;
VAL_ 2047 GTW_tcuType 1 "5G" 0 "4G" ;
VAL_ 2047 GTW_carbComplianceBehaviorType 1 "ACCII_2026_BEHAVIOR" 0 "NONE" ;
VAL_ 2047 GTW_indirectTPMSCalibrationType 4 "EXPERIMENTAL_V2" 3 "EXPERIMENTAL_V1_EU" 2 "EXPERIMENTAL_V1" 1 "STANDARD_EU" 0 "STANDARD" ;
VAL_ 2047 GTW_v2xEnabled 1 "DISABLED" 0 "ENABLED" ;
VAL_ 2047 GTW_liftgateStrutType 1 "TYPE_1" 0 "DEFAULT" ;
VAL_ 2047 GTW_exteriorMicrophoneType 1 "TWO_EXT_MICS" 0 "NONE" ;
VAL_ 2047 GTW_contactorPowerSource 1 "VCFRONT" 0 "VCRIGHT" ;
VAL_ 2047 GTW_roofGlassType 4 "AG3" 3 "UNCOATED" 2 "NONE" 1 "TSA5_NOPET" 0 "TSA3_PET" ;
VAL_ 2047 GTW_pedalMapNameOverride 1 "CHILL_STANDARD" 0 "NO_OVERRIDE" ;
VAL_ 1638 GTW_diagLevel 100 "LEVEL_NORMAL_OPERATION" 80 "LEVEL_PARK" 70 "LEVEL_PARK_ROBOTAXI" 50 "LEVEL_SERVICE_DRIVE" 25 "LEVEL_SERVICE" 10 "LEVEL_DIAG_LINK_ACTIVE" 0 "LEVEL_FACTORY" ;
VAL_ 1080 GTW_ethWakeUpReason 17 "GTW_WAKEUP_REASON_TCU_TC10_VERSION_CHECK" 16 "GTW_WAKEUP_REASON_EGGLEFT_LINK_DOWN" 15 "GTW_WAKEUP_REASON_RCMPRIVATE_CAN" 14 "GTW_WAKEUP_REASON_VCLEFT" 13 "GTW_WAKEUP_REASON_LOOP" 12 "GTW_WAKEUP_REASON_DISPLAY_TAP" 11 "GTW_WAKEUP_REASON_URGENT_TRANSMIT_ALERT" 10 "GTW_WAKEUP_REASON_BDY_CAN" 9 "GTW_WAKEUP_REASON_PT_CAN" 8 "GTW_WAKEUP_REASON_UI_SCHEDULED" 7 "GTW_WAKEUP_REASON_RTC_ALARM" 6 "GTW_WAKEUP_REASON_VCFRONT" 5 "GTW_WAKEUP_REASON_VEH_CAN" 4 "GTW_WAKEUP_REASON_ETH_CAN" 3 "GTW_WAKEUP_REASON_CH_CAN" 2 "GTW_WAKEUP_REASON_GSM_RI" 1 "GTW_WAKEUP_REASON_RESET" 0 "GTW_WAKEUP_REASON_NONE" ;
VAL_ 1656 GTW_gearShiftRequest 4 "GEAR_REQUEST_DRIVE" 3 "GEAR_REQUEST_NEUTRAL" 2 "GEAR_REQUEST_REVERSE" 1 "GEAR_REQUEST_PARK" 0 "GEAR_REQUEST_IDLE_SNA" ;
VAL_ 1656 GTW_primaryGearControlStatus 14 "NOT_QUALIFIED_RHD_CONFIG_UNAVAILABLE" 13 "NOT_QUALIFIED_DISPLAY_KNOWN_FROZEN_SCREEN" 12 "NOT_QUALIFIED_DISPLAY_ASIL_VIDEO_ERROR" 11 "NOT_QUALIFIED_GEAR_STRIP_MISMATCH" 10 "NOT_QUALIFIED_DISPLAY_UNTRAINED" 9 "NOT_QUALIFIED_UI_NO_RESP_GEAR_STRIP" 8 "NOT_QUALIFIED_CENTER_DISP_UI_UNHEALTHY" 7 "NOT_QUALIFIED_DISPLAY_FROZEN_ON_GESTURE" 6 "NOT_QUALIFIED_LOW_BRIGHTNESS" 5 "NOT_QUALIFIED_FALSE_TOUCH" 4 "NOT_QUALIFIED_MANUAL" 3 "NOT_QUALIFIED_DISPLAY_ERRS" 2 "NOT_QUALIFIED_FULLSCREEN" 1 "QUALIFIED" 0 "NOT_QUALIFIED" ;
VAL_ 1656 GTW_autoParkRequest 1 "ACTIVE" 0 "IDLE" ;
VAL_ 1656 GTW_smartShiftStatus 9 "DISABLED_AUDIO_NOT_READY" 8 "DISABLED_OSD_ACTIVATED" 7 "DISABLED_DISQUALIFIED" 6 "DISABLED_FULLSCREEN" 5 "DISABLED_UI_MIA" 4 "DISABLED_CLUSTER_DISP_ERR" 3 "DISABLED_CENTER_DISP_ERR" 2 "DISABLED_UI_CONFIG" 1 "ENABLED" 0 "DISABLED_SNA" ;
VAL_ 1656 GTW_gearStripChangeReason 27 "EBUCK_DISABLE" 26 "SLEEP_DISABLE" 25 "VC_MIA_GRACE_DISABLE" 24 "VC_MIA_ENABLE" 23 "DRIVERLESS_NO_TAKEOVER_DISABLE" 22 "EMERGENCY_OPERATION_ENABLE" 21 "WOT_ENABLE" 20 "PARK_ENGAGED_ENABLE" 19 "MISSING_SPEED_OR_STEERING_ESTIMATE_IN_D_ENABLE" 18 "UI_MIA_ENABLE" 16 "NOT_DRIVE_STATE_DISABLE" 15 "FULLSCREEN_DISABLE" 14 "DEFAULT_DISABLE" 13 "REVERSE_ENABLE" 12 "NEUTRAL_ENABLE" 11 "P_AND_BRAKE_ENABLE" 10 "CHARGING_DISABLE" 9 "CRUISE_ACTIVE_DISABLE" 8 "DI_MIA_ENABLE" 7 "HIGH_ACCEL_DISABLE" 6 "MEDIUM_SPEED_DISABLE" 5 "TRAFFIC_CONTROL_NO_CHANGE" 4 "VERY_LOW_SPEED_ENABLE" 3 "HIGH_STEERING_ANGLE_ENABLE" 2 "HIGH_JERK_ENABLE" 1 "DRIVER_BRAKE_APPLY_ENABLE" 0 "SNA" ;
VAL_ 1656 GTW_screenPCBTemperature 2047 "GTW_I2C_TEMP_SNA" ;
VAL_ 2033 GTW_hrlIndex 2 "Mux2" 1 "Mux1" ;
VAL_ 2033 GTW_hrlSdCardSizeGB 0 "SNA" ;
VAL_ 2033 GTW_hrlState 1 "ENABLED" 0 "DISABLED" ;
VAL_ 2033 GTW_hrlTriggerType 15 "HRL_TRIGGER_NONE" 5 "HRL_TRIGGER_EVENT_EXTERNAL" 4 "HRL_TRIGGER_PSEUDONYMOUS" 3 "HRL_TRIGGER_CONTINUOUS" 2 "HRL_TRIGGER_GAME_MODE" 1 "HRL_TRIGGER_EVENT" 0 "HRL_TRIGGER_UDPAPI" ;
VAL_ 60 GTW_infoIndex 255 "END" 31 "SUBCOMPONENT_GITHASH" 30 "PACKAGE_SN_8_14" 29 "PACKAGE_SN_1_7" 27 "PACKAGE_PN_15_20" 26 "PACKAGE_PN_8_14" 25 "PACKAGE_PN_1_7" 23 "SUBCOMPONENT2" 22 "VARIANTCRC" 20 "UDS_PROTOCOL_BOOTCRC" 19 "VERSION_DEPRECATED" 18 "BOOTLOADER_GITHASH" 17 "APP_GITHASH" 16 "SUBCOMPONENT" 15 "BOOTLOADER_CRC" 14 "BOOTLOADER_SVN" 13 "APP_CRC" 11 "PCBAID_ASSYID_USAGEID" 10 "BUILD_HWID_COMPONENTID" 9 "DEPRECATED_9" 8 "DEPRECATED_8" 7 "DEPRECATED_7" 6 "DEPRECATED_6" 5 "DEPRECATED_5" 4 "DEPRECATED_4" 3 "DEPRECATED_3" 2 "DEPRECATED_2" 1 "DEPRECATED_1" 0 "DEPRECATED_0" ;
VAL_ 60 GTW_buildType 4 "INFO_MFG_BUILD" 3 "INFO_TRACEABLE_CI_BUILD" 2 "INFO_LOCAL_BUILD" 1 "INFO_PLATFORM_BUILD" 0 "INFO_UNKNOWN_BUILD" ;
VAL_ 60 GTW_platformType 255 "GTW_PLATFORM_END" 3 "GTW_PLATFORM_MODEL3" 0 "GTW_PLATFORM_UNKNOWN" ;
VAL_ 1370 GTW_mismatchFaultIndex 5 "Mux5" 4 "Mux4" 3 "Mux3" 2 "Mux2" 1 "Mux1" ;
VAL_ 840 GTW_vehicleVersionMatchStatus 2 "MATCHED" 1 "MISMATCHED" 0 "NOT_CALCULATED_YET" ;
VAL_ 840 GTW_hwtype 3 "TRAVEO2" 2 "SPC58" 1 "MPC57" 0 "SNA" ;
VAL_ 840 GTW_jcanProductName 11 "SEMITRUCKV2" 10 "GOLDENSNITCH" 8 "BAYBERRY" 7 "CYBERTRUCK" 6 "POPPYSEED" 5 "SEMITRUCK" 4 "TAMARIND" 3 "LYCHEE" 2 "MODELY" 1 "MODEL3" 0 "SNA" ;
VAL_ 840 GTW_touchcoreOsType 1 "GTW_OS_RT" 0 "GTW_OS_FREERTOS" ;
VAL_ 840 GTW_sentryModeState 6 "SNA" 5 "QUIET" 4 "PANIC" 3 "AWARE" 2 "ARMED" 1 "IDLE" 0 "OFF" ;
VAL_ 840 GTW_secureBootEnabled 1 "TRUE" 0 "FALSE" ;
VAL_ 840 GTW_socSleepType 2 "SHALLOW" 1 "S3" 0 "SNA" ;
VAL_ 840 GTW_resetType 8 "OTHER" 7 "TOUCHCORE_WATCHDOG" 6 "CANCORE_WATCHDOG" 5 "MAINCORE_WATCHDOG" 4 "WAKE" 3 "BUTTON" 2 "SOFTWARE" 1 "POR" 0 "SNA" ;
VAL_ 1005 GTW_peripheralConfirmedUpdateNee 3 "UPDATE_CONDITIONS_NOT_CORRECT" 2 "UPDATE_NOT_NEEDED" 1 "UPDATE_NEEDED" 0 "UNKNOWN" ;
VAL_ 1112 GTW_nmKeepAwakeReason 15 "GTW_KEEPAWAKE_REASON_TBD" 7 "GTW_KEEPAWAKE_REASON_TCU_TC10_VERSION_UNSUPPORTED" 6 "GTW_KEEPAWAKE_REASON_TCU_TC10_VERSION_CHECK" 5 "GTW_KEEPAWAKE_REASON_EGGLEFT_LINK_DOWN" 4 "GTW_KEEPAWAKE_REASON_URGENT_TRANSMIT_ALERT" 3 "GTW_KEEPAWAKE_REASON_FCSM_ACTIVE" 2 "GTW_KEEPAWAKE_REASON_GSM_RI" 1 "GTW_KEEPAWAKE_REASON_UI_SCHEDULED" 0 "GTW_KEEPAWAKE_REASON_NONE_SNA" ;
VAL_ 1112 GTW_nmWakeUpReason 17 "GTW_WAKEUP_REASON_TCU_TC10_VERSION_CHECK" 16 "GTW_WAKEUP_REASON_EGGLEFT_LINK_DOWN" 15 "GTW_WAKEUP_REASON_RCMPRIVATE_CAN" 14 "GTW_WAKEUP_REASON_VCLEFT" 13 "GTW_WAKEUP_REASON_LOOP" 12 "GTW_WAKEUP_REASON_DISPLAY_TAP" 11 "GTW_WAKEUP_REASON_URGENT_TRANSMIT_ALERT" 10 "GTW_WAKEUP_REASON_BDY_CAN" 9 "GTW_WAKEUP_REASON_PT_CAN" 8 "GTW_WAKEUP_REASON_UI_SCHEDULED" 7 "GTW_WAKEUP_REASON_RTC_ALARM" 6 "GTW_WAKEUP_REASON_VCFRONT" 5 "GTW_WAKEUP_REASON_VEH_CAN" 4 "GTW_WAKEUP_REASON_ETH_CAN" 3 "GTW_WAKEUP_REASON_CH_CAN" 2 "GTW_WAKEUP_REASON_GSM_RI" 1 "GTW_WAKEUP_REASON_RESET" 0 "GTW_WAKEUP_REASON_NONE" ;
VAL_ 1112 GTW_ethKeepAwakeReason 3 "TCU_TC10_VERSION_UNSUPPORTED" 2 "TCU_TC10_VERSION_CHECK" 1 "URGENT_TRANSMIT_ALERT" 0 "NONE_SNA" ;
VAL_ 1112 GTW_nmDebugWakeUp 2147483648 "WKPU_31" 1073741824 "WKPU_30" 536870912 "WKPU_29" 268435456 "WKPU_28" 134217728 "WKPU_27" 67108864 "WKPU_26" 33554432 "WKPU_25" 16777216 "WKPU_24" 8388608 "WKPU_23" 4194304 "WKPU_22" 2097152 "WKPU_21" 1048576 "WKPU_20" 524288 "WKPU_19" 262144 "WKPU_18" 131072 "WKPU_17" 65536 "WKPU_16" 32768 "WKPU_15" 16384 "WKPU_14" 8192 "WKPU_13" 4096 "WKPU_12" 2048 "WKPU_11" 1024 "WKPU_10" 512 "WKPU_9" 256 "WKPU_8" 128 "WKPU_7" 64 "WKPU_6" 32 "WKPU_5" 16 "WKPU_4" 8 "WKPU_3" 4 "WKPU_2" 2 "WKPU_1" 1 "WKPU_0" 0 "WKPU_NONE" ;
VAL_ 1429 OCS1P_alertID 156 "a156_seatbeltReminderUnavailable" 155 "a155_rbExit2Exited2" 154 "a154_rbExit2Exited1" 153 "a153_rbExit1Exited" 152 "a152_rbExit1Triggered" 151 "a151_rbEntryExited" 150 "a150_rbEntryTriggered" 148 "a148_classificationMismatch" 145 "a145_rebaselineTriggered" 144 "a144_mismatchCarRegion" 143 "a143_mismatchPassAirbag" 142 "a142_tempHumidityInvalid" 141 "a141_humidityInvalidCalib" 140 "a140_tempInvalidCalib" 139 "a139_seatbackSelfDutyHigh" 138 "a138_seatbackSelfDutyLow" 137 "a137_cushionSelfDutyHigh" 136 "a136_cushionSelfDutyLow" 135 "a135_tempNoCalib" 134 "a134_uninitializedCalib" 133 "a133_sandwichBadCalib" 132 "a132_seatbackSelfNoCalib" 131 "a131_cushionSelfNoCalib" 130 "a130_sandwichNoCalib" 129 "a129_seatbackSelfShort" 128 "a128_seatbackSelfLow" 127 "a127_seatbackSelfOpen" 126 "a126_cushionSelfShort" 125 "a125_cushionSelfLow" 124 "a124_cushionSelfOpen" 123 "a123_sandwichShort" 122 "a122_sandwichLow" 121 "a121_sandwichOpen" 15 "a015_NVMMAlert" 0 "ALERT_DO_NOT_USE_ZERO" ;
VAL_ 1429 OCS1P_alertState 1 "SET" 0 "CLEARED" ;
VAL_ 767 OCS1P_matrixIndex 2 "AlertMatrix2" 0 "AlertMatrix0" ;
VAL_ 766 OCS1P_infoIndex 20 "Mux20" 19 "Mux19" 18 "Mux18" 17 "Mux17" 14 "Mux14" 13 "Mux13" 11 "Mux11" 10 "Mux10" ;
VAL_ 766 OCS1P_infoBuildType 4 "INFO_MFG_BUILD" 3 "INFO_TRACEABLE_CI_BUILD" 2 "INFO_LOCAL_BUILD" 1 "INFO_PLATFORM_BUILD" 0 "INFO_UNKNOWN_BUILD" ;
VAL_ 771 OCS1P_occupantClassification 255 "OCCUPANT_CLASSIFICATION_SNA" 4 "OCCUPANT_CLASSIFICATION_INIT" 3 "OCCUPANT_CLASSIFICATION_OCCUPIED_ALLOW_LARGE" 2 "OCCUPANT_CLASSIFICATION_OCCUPIED_ALLOW_SMALL" 1 "OCCUPANT_CLASSIFICATION_OCCUPIED_INHIBIT" 0 "OCCUPANT_CLASSIFICATION_EMPTY" ;
VAL_ 771 OCS1P_occupantClassificationQF 1 "OCCUPANT_CLASSIFICATION_NOT_FAULTED" 0 "OCCUPANT_CLASSIFICATION_FAULTED" ;
VAL_ 771 OCS1P_occupiedState 3 "OCCUPIED_STATE_SNA" 1 "OCCUPIED_STATE_OCCUPIED" 0 "OCCUPIED_STATE_UNOCCUPIED" ;
VAL_ 771 OCS1P_triggerSnapshot 19 "REASON_LCB_TOO_HIGH" 18 "REASON_SWITCHED_TO_HCB" 17 "REASON_LARGE_REBASELINE" 16 "REASON_BORDERLINE_CLASSIFICATION" 15 "REASON_MISSED_EXIT_EVENT" 14 "REASON_MISSED_ENTRY_EVENT" 13 "REASON_EMPTY_CONFIDENT_EXITED" 12 "REASON_EMPTY_CONFIDENT_REBASELINED" 11 "REASON_EXIT_REBASELINED" 10 "REASON_EXIT_FAILED" 9 "REASON_EXIT_TRIGGERED" 8 "REASON_ENTRY_REBASELINED" 7 "REASON_ENTRY_FAILED" 6 "REASON_ENTRY_TRIGGERED" 5 "REASON_SENSOR_LOW_SHORT" 4 "REASON_SENSOR_OPEN" 3 "REASON_SANDWICH_LOW" 2 "REASON_REBASELINED" 1 "REASON_MISMATCH" 0 "REASON_NONE" ;
VAL_ 771 OCS1P_occupantClassificationRaw 7 "OCCUPANT_CLASSIFICATION_SNA" 4 "OCCUPANT_CLASSIFICATION_INIT" 3 "OCCUPANT_CLASSIFICATION_OCCUPIED_ALLOW_LARGE" 2 "OCCUPANT_CLASSIFICATION_OCCUPIED_ALLOW_SMALL" 1 "OCCUPANT_CLASSIFICATION_OCCUPIED_INHIBIT" 0 "OCCUPANT_CLASSIFICATION_EMPTY" ;
VAL_ 771 OCS1P_occupantClassificationSelf 7 "OCCUPANT_CLASSIFICATION_SNA" 4 "OCCUPANT_CLASSIFICATION_INIT" 3 "OCCUPANT_CLASSIFICATION_OCCUPIED_ALLOW_LARGE" 2 "OCCUPANT_CLASSIFICATION_OCCUPIED_ALLOW_SMALL" 1 "OCCUPANT_CLASSIFICATION_OCCUPIED_INHIBIT" 0 "OCCUPANT_CLASSIFICATION_EMPTY" ;
VAL_ 771 OCS1P_occupantClassificationRawC 7 "OCCUPANT_CLASSIFICATION_SNA" 4 "OCCUPANT_CLASSIFICATION_INIT" 3 "OCCUPANT_CLASSIFICATION_OCCUPIED_ALLOW_LARGE" 2 "OCCUPANT_CLASSIFICATION_OCCUPIED_ALLOW_SMALL" 1 "OCCUPANT_CLASSIFICATION_OCCUPIED_INHIBIT" 0 "OCCUPANT_CLASSIFICATION_EMPTY" ;
VAL_ 771 OCS1P_occupantClassificationCap 7 "OCCUPANT_CLASSIFICATION_SNA" 4 "OCCUPANT_CLASSIFICATION_INIT" 3 "OCCUPANT_CLASSIFICATION_OCCUPIED_ALLOW_LARGE" 2 "OCCUPANT_CLASSIFICATION_OCCUPIED_ALLOW_SMALL" 1 "OCCUPANT_CLASSIFICATION_OCCUPIED_INHIBIT" 0 "OCCUPANT_CLASSIFICATION_EMPTY" ;
VAL_ 771 OCS1P_classificationHoldState 3 "OCCUPANCY_HOLD_FAULT" 2 "OCCUPANCY_HOLD_EXTERNAL" 1 "OCCUPANCY_HOLD_BASIC" 0 "OCCUPANCY_HOLD_OFF" ;
VAL_ 771 OCS1P_classificationVariant 7 "CLASSIFICATION_VARIANT_UNKNOWN" 3 "CLASSIFICATION_VARIANT_SELF_SBR_RB" 2 "CLASSIFICATION_VARIANT_SELF_SBR" 1 "CLASSIFICATION_VARIANT_SELF_ONLY" 0 "CLASSIFICATION_VARIANT_ALL_SENSORS" ;
VAL_ 771 OCS1P_noSandwichType 3 "NO_SANDWICH_UNKNOWN" 2 "NO_SANDWICH_NA" 1 "NO_SANDWICH_EU" 0 "SANDWICH_INSTALLED" ;
VAL_ 771 OCS1P_sandwichBoundaryType 1 "SANDWICH_LRD" 0 "SANDWICH_DEFAULT" ;
VAL_ 771 OCS1P_sbrBoundaryType 1 "SBR_1669747_1763884" 0 "SBR_DEFAULT" ;
VAL_ 771 OCS1P_occupiedStateCap 3 "OCCUPIED_STATE_SNA" 1 "OCCUPIED_STATE_OCCUPIED" 0 "OCCUPIED_STATE_UNOCCUPIED" ;
VAL_ 519 PTC_leftPowerDerating 3 "OVERTEMPERATURE_CORE" 2 "OVERTEMPERATURE_IGBT" 1 "OVERTEMPERATURE_PCB" 0 "NOT_DERATED" ;
VAL_ 519 PTC_rightPowerDerating 3 "OVERTEMPERATURE_CORE" 2 "OVERTEMPERATURE_IGBT" 1 "OVERTEMPERATURE_PCB" 0 "NOT_DERATED" ;
VAL_ 519 PTC_ocpEvent 2 "OCP_EVENT_RIGHT_SIDE" 1 "OCP_EVENT_LEFT_SIDE" 0 "NO_OCP_EVENT" ;
VAL_ 519 PTC_tliSource 4 "HV_OVER_VOLTAGE" 3 "OCP" 2 "12_VOLTS" 1 "IGBT_DRIVER" 0 "NO_ERROR" ;
VAL_ 1297 RCM_alertID 118 "a118_imuInPlaneAcceleration" 117 "a117_imuVerticalAcceleration" 116 "a116_imuLateralAcceleration" 115 "a115_imuLinearAcceleration" 114 "a114_imuRollRate" 113 "a113_imuPitchRate" 112 "a112_imuYawRate" 111 "a111_diagnosticsEnabled" 110 "a110_factoryMode" 109 "a109_abuseImmunity" 108 "a108_crashAlgoWakeup" 107 "a107_imuVertAccOffstCompLim" 106 "a106_imuLatAccOffstCompLim" 105 "a105_imuLongAccOffstCompLim" 104 "a104_imuRollR8OffstCompLim" 103 "a103_imuPtchR8OffstCompLim" 102 "a102_imuYawR8OffstCompLim" 101 "a101_idfSystem" 100 "a100_comDIsystemStatus" 99 "a099_comDItorque" 98 "a098_comDIchassisControl" 97 "a097_comDIspeed" 96 "a096_comESPwheelSpeeds" 95 "a095_comESPstatus" 94 "a094_comVCRIGHTStatus" 93 "a093_comVCLEFTStatus" 92 "a092_comDASISF" 91 "a091_comEPAS3PsysStatus" 90 "a090_comPartyBusOff" 89 "a089_comCHCANPH3" 88 "a088_comCHCANPH2" 87 "a087_comCANSilent" 86 "a086_comVINMIA" 85 "a085_comGTWCarConfig" 84 "a084_comTPMSStatus" 83 "a083_comGTWCarState" 82 "a082_comUIodo" 81 "a081_comVCFRONTLVPwr" 80 "a080_comGTWACS" 79 "a079_comOCS1DStatus" 78 "a078_comOCS1PStatus" 77 "a077_comEPBRStatus" 76 "a076_comEPBLStatus" 75 "a075_comCHCANPH6" 74 "a074_comCHCANPH5" 73 "a073_comCHCANPH4" 72 "a072_comUnused" 71 "a071_comCHCANPH9" 70 "a070_comCHCANPH8" 69 "a069_comCHCANPH7" 68 "a068_comChassisBusOff" 67 "a067_comCANInitFailure" 66 "a066_seatBackSw2ndRowLeft" 65 "a065_driverOrientConfigPin" 64 "a064_hardwareCodingPin1" 63 "a063_sbsw2ndRowRight" 62 "a062_alrSwitch" 61 "a061_stpsRight" 60 "a060_stpsLeft" 59 "a059_buckle1stRowRight" 58 "a058_buckle1stRowLeft" 57 "a057_driverOCS" 56 "a056_passengerFrontOCS" 55 "a055_inertialMeasurement" 54 "a054_pressurePedProRight" 53 "a053_pressurePedProLeft" 52 "a052_pressureFrontRtDoor" 51 "a051_pressureFrontLftDoor" 50 "a050_upFrontSensorCenter" 49 "a049_sideAccelCPillarRight" 48 "a048_sideAccelCPillarLeft" 47 "a047_sideAccelBPillarRight" 46 "a046_sideAccelBPillarLeft" 45 "a045_upFrontSensorRight" 44 "a044_upFrontSensorLeft" 43 "a043_ens2Line" 42 "a042_ens1Line" 41 "a041_hoodActuatorLeft" 40 "a040_hoodActuatorRight" 39 "a039_unusedB" 38 "a038_unusedA" 37 "a037_curAB2ndRowRight" 36 "a036_curAB2ndRowLeft" 35 "a035_preten2ndRowRight" 34 "a034_preten2ndRowLeft" 33 "a033_curtainABRight" 32 "a032_curtainABLeft" 31 "a031_frontCenterAirbag" 30 "a030_farSideInboardAirbag" 29 "a029_driverABActiveVent" 28 "a028_sideAB1stRowRight" 27 "a027_sideAB1stRowLeft" 26 "a026_kneeABFrontPassenger" 25 "a025_kneeABDriver" 24 "a024_loadLimiterRightSide" 23 "a023_loadLimiterLeftSide" 22 "a022_pretenLapFrontRight" 21 "a021_pretenLapFrontLeft" 20 "a020_pretenShldFrontRight" 19 "a019_pretenShldrFrontLeft" 18 "a018_passengerActiveVent" 17 "a017_passABStage2" 16 "a016_passABStage1" 15 "a015_driverABStage2" 14 "a014_driverABStage1" 13 "a013_driverOrientation" 12 "a012_vinStorage" 11 "a011_eepromDataLocked" 10 "a010_scmDisabled" 9 "a009_reprogramLimit" 8 "a008_powerSupplyInternal" 7 "a007_powerSupplyExternal" 6 "a006_batteryVoltageRange" 5 "a005_crcError" 4 "a004_internalFault" 3 "a003_warningIndicator" 2 "a002_airbagsNotArmed" 1 "a001_nearDeploy" 0 "a000_crashDetected" ;
VAL_ 1297 RCM_alertState 1 "SET" 0 "CLEARED" ;
VAL_ 1297 RCM_a000_eventArmStatus 1 "ARMED" 0 "UNARMED" ;
VAL_ 1297 RCM_a000_eventFactoryMode 1 "ENABLED" 0 "DISABLED" ;
VAL_ 1297 RCM_a000_eventDiagEnabled 1 "ENABLED" 0 "DISABLED" ;
VAL_ 1297 RCM_a000_eventDriveOrientation 1 "RIGHT_HAND_DRIVE" 0 "LEFT_HAND_DRIVE" ;
VAL_ 1297 RCM_a000_eventIDFsignal 1 "ACTIVE" 0 "NOT_ACTIVE" ;
VAL_ 1297 RCM_a000_eventFrontLeftSeatbelt 1 "LATCHED" 0 "UNLATCHED" ;
VAL_ 1297 RCM_a000_eventFrontRightSeatbelt 1 "LATCHED" 0 "UNLATCHED" ;
VAL_ 1297 RCM_a000_eventDriverBrakeApply 3 "Faulty_SNA" 2 "Driver_applying_brakes" 1 "Not_Applied" 0 "NotInit_orOff" ;
VAL_ 1297 RCM_a000_eventAccelPedalPos 255 "SNA" ;
VAL_ 1297 RCM_a001_eventArmStatus 1 "ARMED" 0 "UNARMED" ;
VAL_ 1297 RCM_a001_eventFactoryMode 1 "ENABLED" 0 "DISABLED" ;
VAL_ 1297 RCM_a001_eventDiagEnabled 1 "ENABLED" 0 "DISABLED" ;
VAL_ 1297 RCM_a001_eventDriveOrientation 1 "RIGHT_HAND_DRIVE" 0 "LEFT_HAND_DRIVE" ;
VAL_ 1297 RCM_a001_eventIDFsignal 1 "ACTIVE" 0 "NOT_ACTIVE" ;
VAL_ 1297 RCM_a001_eventFrontLeftSeatbelt 1 "LATCHED" 0 "UNLATCHED" ;
VAL_ 1297 RCM_a001_eventFrontRightSeatbelt 1 "LATCHED" 0 "UNLATCHED" ;
VAL_ 1297 RCM_a001_eventDriverBrakeApply 3 "Faulty_SNA" 2 "Driver_applying_brakes" 1 "Not_Applied" 0 "NotInit_orOff" ;
VAL_ 1297 RCM_a001_eventAccelPedalPos 255 "SNA" ;
VAL_ 1297 RCM_a002_eventArmStatus 1 "ARMED" 0 "UNARMED" ;
VAL_ 1297 RCM_a002_eventFactoryMode 1 "ENABLED" 0 "DISABLED" ;
VAL_ 1297 RCM_a002_eventDiagEnabled 1 "ENABLED" 0 "DISABLED" ;
VAL_ 1297 RCM_a002_eventDriveOrientation 1 "RIGHT_HAND_DRIVE" 0 "LEFT_HAND_DRIVE" ;
VAL_ 1297 RCM_a002_eventIDFsignal 1 "ACTIVE" 0 "NOT_ACTIVE" ;
VAL_ 1297 RCM_a002_eventFrontLeftSeatbelt 1 "LATCHED" 0 "UNLATCHED" ;
VAL_ 1297 RCM_a002_eventFrontRightSeatbelt 1 "LATCHED" 0 "UNLATCHED" ;
VAL_ 1297 RCM_a002_eventDriverBrakeApply 3 "Faulty_SNA" 2 "Driver_applying_brakes" 1 "Not_Applied" 0 "NotInit_orOff" ;
VAL_ 1297 RCM_a002_eventAccelPedalPos 255 "SNA" ;
VAL_ 1297 RCM_a003_eventArmStatus 1 "ARMED" 0 "UNARMED" ;
VAL_ 1297 RCM_a003_eventFactoryMode 1 "ENABLED" 0 "DISABLED" ;
VAL_ 1297 RCM_a003_eventDiagEnabled 1 "ENABLED" 0 "DISABLED" ;
VAL_ 1297 RCM_a003_eventDriveOrientation 1 "RIGHT_HAND_DRIVE" 0 "LEFT_HAND_DRIVE" ;
VAL_ 1297 RCM_a003_eventIDFsignal 1 "ACTIVE" 0 "NOT_ACTIVE" ;
VAL_ 1297 RCM_a003_eventFrontLeftSeatbelt 1 "LATCHED" 0 "UNLATCHED" ;
VAL_ 1297 RCM_a003_eventFrontRightSeatbelt 1 "LATCHED" 0 "UNLATCHED" ;
VAL_ 1297 RCM_a003_eventDriverBrakeApply 3 "Faulty_SNA" 2 "Driver_applying_brakes" 1 "Not_Applied" 0 "NotInit_orOff" ;
VAL_ 1297 RCM_a003_eventAccelPedalPos 255 "SNA" ;
VAL_ 1297 RCM_a004_eventArmStatus 1 "ARMED" 0 "UNARMED" ;
VAL_ 1297 RCM_a004_eventFactoryMode 1 "ENABLED" 0 "DISABLED" ;
VAL_ 1297 RCM_a004_eventDiagEnabled 1 "ENABLED" 0 "DISABLED" ;
VAL_ 1297 RCM_a004_eventDriveOrientation 1 "RIGHT_HAND_DRIVE" 0 "LEFT_HAND_DRIVE" ;
VAL_ 1297 RCM_a004_eventIDFsignal 1 "ACTIVE" 0 "NOT_ACTIVE" ;
VAL_ 1297 RCM_a004_eventFrontLeftSeatbelt 1 "LATCHED" 0 "UNLATCHED" ;
VAL_ 1297 RCM_a004_eventFrontRightSeatbelt 1 "LATCHED" 0 "UNLATCHED" ;
VAL_ 1297 RCM_a004_eventDriverBrakeApply 3 "Faulty_SNA" 2 "Driver_applying_brakes" 1 "Not_Applied" 0 "NotInit_orOff" ;
VAL_ 1297 RCM_a004_eventAccelPedalPos 255 "SNA" ;
VAL_ 1297 RCM_a005_eventArmStatus 1 "ARMED" 0 "UNARMED" ;
VAL_ 1297 RCM_a005_eventFactoryMode 1 "ENABLED" 0 "DISABLED" ;
VAL_ 1297 RCM_a005_eventDiagEnabled 1 "ENABLED" 0 "DISABLED" ;
VAL_ 1297 RCM_a005_eventDriveOrientation 1 "RIGHT_HAND_DRIVE" 0 "LEFT_HAND_DRIVE" ;
VAL_ 1297 RCM_a005_eventIDFsignal 1 "ACTIVE" 0 "NOT_ACTIVE" ;
VAL_ 1297 RCM_a005_eventFrontLeftSeatbelt 1 "LATCHED" 0 "UNLATCHED" ;
VAL_ 1297 RCM_a005_eventFrontRightSeatbelt 1 "LATCHED" 0 "UNLATCHED" ;
VAL_ 1297 RCM_a005_eventDriverBrakeApply 3 "Faulty_SNA" 2 "Driver_applying_brakes" 1 "Not_Applied" 0 "NotInit_orOff" ;
VAL_ 1297 RCM_a005_eventAccelPedalPos 255 "SNA" ;
VAL_ 1297 RCM_a006_eventArmStatus 1 "ARMED" 0 "UNARMED" ;
VAL_ 1297 RCM_a006_eventFactoryMode 1 "ENABLED" 0 "DISABLED" ;
VAL_ 1297 RCM_a006_eventDiagEnabled 1 "ENABLED" 0 "DISABLED" ;
VAL_ 1297 RCM_a006_eventDriveOrientation 1 "RIGHT_HAND_DRIVE" 0 "LEFT_HAND_DRIVE" ;
VAL_ 1297 RCM_a006_eventIDFsignal 1 "ACTIVE" 0 "NOT_ACTIVE" ;
VAL_ 1297 RCM_a006_eventFrontLeftSeatbelt 1 "LATCHED" 0 "UNLATCHED" ;
VAL_ 1297 RCM_a006_eventFrontRightSeatbelt 1 "LATCHED" 0 "UNLATCHED" ;
VAL_ 1297 RCM_a006_eventDriverBrakeApply 3 "Faulty_SNA" 2 "Driver_applying_brakes" 1 "Not_Applied" 0 "NotInit_orOff" ;
VAL_ 1297 RCM_a006_eventAccelPedalPos 255 "SNA" ;
VAL_ 1297 RCM_a008_eventArmStatus 1 "ARMED" 0 "UNARMED" ;
VAL_ 1297 RCM_a008_eventFactoryMode 1 "ENABLED" 0 "DISABLED" ;
VAL_ 1297 RCM_a008_eventDiagEnabled 1 "ENABLED" 0 "DISABLED" ;
VAL_ 1297 RCM_a008_eventDriveOrientation 1 "RIGHT_HAND_DRIVE" 0 "LEFT_HAND_DRIVE" ;
VAL_ 1297 RCM_a008_eventIDFsignal 1 "ACTIVE" 0 "NOT_ACTIVE" ;
VAL_ 1297 RCM_a008_eventFrontLeftSeatbelt 1 "LATCHED" 0 "UNLATCHED" ;
VAL_ 1297 RCM_a008_eventFrontRightSeatbelt 1 "LATCHED" 0 "UNLATCHED" ;
VAL_ 1297 RCM_a008_eventDriverBrakeApply 3 "Faulty_SNA" 2 "Driver_applying_brakes" 1 "Not_Applied" 0 "NotInit_orOff" ;
VAL_ 1297 RCM_a008_eventAccelPedalPos 255 "SNA" ;
VAL_ 1297 RCM_a009_eventArmStatus 1 "ARMED" 0 "UNARMED" ;
VAL_ 1297 RCM_a009_eventFactoryMode 1 "ENABLED" 0 "DISABLED" ;
VAL_ 1297 RCM_a009_eventDiagEnabled 1 "ENABLED" 0 "DISABLED" ;
VAL_ 1297 RCM_a009_eventDriveOrientation 1 "RIGHT_HAND_DRIVE" 0 "LEFT_HAND_DRIVE" ;
VAL_ 1297 RCM_a009_eventIDFsignal 1 "ACTIVE" 0 "NOT_ACTIVE" ;
VAL_ 1297 RCM_a009_eventFrontLeftSeatbelt 1 "LATCHED" 0 "UNLATCHED" ;
VAL_ 1297 RCM_a009_eventFrontRightSeatbelt 1 "LATCHED" 0 "UNLATCHED" ;
VAL_ 1297 RCM_a009_eventDriverBrakeApply 3 "Faulty_SNA" 2 "Driver_applying_brakes" 1 "Not_Applied" 0 "NotInit_orOff" ;
VAL_ 1297 RCM_a009_eventAccelPedalPos 255 "SNA" ;
VAL_ 1297 RCM_a011_eventArmStatus 1 "ARMED" 0 "UNARMED" ;
VAL_ 1297 RCM_a011_eventFactoryMode 1 "ENABLED" 0 "DISABLED" ;
VAL_ 1297 RCM_a011_eventDiagEnabled 1 "ENABLED" 0 "DISABLED" ;
VAL_ 1297 RCM_a011_eventDriveOrientation 1 "RIGHT_HAND_DRIVE" 0 "LEFT_HAND_DRIVE" ;
VAL_ 1297 RCM_a011_eventIDFsignal 1 "ACTIVE" 0 "NOT_ACTIVE" ;
VAL_ 1297 RCM_a011_eventFrontLeftSeatbelt 1 "LATCHED" 0 "UNLATCHED" ;
VAL_ 1297 RCM_a011_eventFrontRightSeatbelt 1 "LATCHED" 0 "UNLATCHED" ;
VAL_ 1297 RCM_a011_eventDriverBrakeApply 3 "Faulty_SNA" 2 "Driver_applying_brakes" 1 "Not_Applied" 0 "NotInit_orOff" ;
VAL_ 1297 RCM_a011_eventAccelPedalPos 255 "SNA" ;
VAL_ 1297 RCM_a012_eventArmStatus 1 "ARMED" 0 "UNARMED" ;
VAL_ 1297 RCM_a012_eventFactoryMode 1 "ENABLED" 0 "DISABLED" ;
VAL_ 1297 RCM_a012_eventDiagEnabled 1 "ENABLED" 0 "DISABLED" ;
VAL_ 1297 RCM_a012_eventDriveOrientation 1 "RIGHT_HAND_DRIVE" 0 "LEFT_HAND_DRIVE" ;
VAL_ 1297 RCM_a012_eventIDFsignal 1 "ACTIVE" 0 "NOT_ACTIVE" ;
VAL_ 1297 RCM_a012_eventFrontLeftSeatbelt 1 "LATCHED" 0 "UNLATCHED" ;
VAL_ 1297 RCM_a012_eventFrontRightSeatbelt 1 "LATCHED" 0 "UNLATCHED" ;
VAL_ 1297 RCM_a012_eventDriverBrakeApply 3 "Faulty_SNA" 2 "Driver_applying_brakes" 1 "Not_Applied" 0 "NotInit_orOff" ;
VAL_ 1297 RCM_a012_eventAccelPedalPos 255 "SNA" ;
VAL_ 1297 RCM_a013_eventArmStatus 1 "ARMED" 0 "UNARMED" ;
VAL_ 1297 RCM_a013_eventFactoryMode 1 "ENABLED" 0 "DISABLED" ;
VAL_ 1297 RCM_a013_eventDiagEnabled 1 "ENABLED" 0 "DISABLED" ;
VAL_ 1297 RCM_a013_eventDriveOrientation 1 "RIGHT_HAND_DRIVE" 0 "LEFT_HAND_DRIVE" ;
VAL_ 1297 RCM_a013_eventIDFsignal 1 "ACTIVE" 0 "NOT_ACTIVE" ;
VAL_ 1297 RCM_a013_eventFrontLeftSeatbelt 1 "LATCHED" 0 "UNLATCHED" ;
VAL_ 1297 RCM_a013_eventFrontRightSeatbelt 1 "LATCHED" 0 "UNLATCHED" ;
VAL_ 1297 RCM_a013_eventDriverBrakeApply 3 "Faulty_SNA" 2 "Driver_applying_brakes" 1 "Not_Applied" 0 "NotInit_orOff" ;
VAL_ 1297 RCM_a013_eventAccelPedalPos 255 "SNA" ;
VAL_ 1297 RCM_a014_eventArmStatus 1 "ARMED" 0 "UNARMED" ;
VAL_ 1297 RCM_a014_eventFactoryMode 1 "ENABLED" 0 "DISABLED" ;
VAL_ 1297 RCM_a014_eventDiagEnabled 1 "ENABLED" 0 "DISABLED" ;
VAL_ 1297 RCM_a014_eventDriveOrientation 1 "RIGHT_HAND_DRIVE" 0 "LEFT_HAND_DRIVE" ;
VAL_ 1297 RCM_a014_eventIDFsignal 1 "ACTIVE" 0 "NOT_ACTIVE" ;
VAL_ 1297 RCM_a014_eventFrontLeftSeatbelt 1 "LATCHED" 0 "UNLATCHED" ;
VAL_ 1297 RCM_a014_eventFrontRightSeatbelt 1 "LATCHED" 0 "UNLATCHED" ;
